VERSION ""

NS_ :

BS_:

BU_: ACC GW LAS BDC mADC FC APA HPP

BO_ 898 ACC_382: 64 ACC
 SG_ ACC_TarVehLngRange : 487|12@0+ (0.1,0) [0|300] "m"  ACC,LAS,GW
 SG_ ACC_Target5ZoneID : 449|5@0+ (1,0) [0|31] ""  ACC,LAS,GW,mADC
 SG_ ACC_Target5HeadingAngle : 443|10@0+ (0.01,-3.14) [-3.14|3.14] "rad"  ACC,LAS,GW,mADC
 SG_ ACC_Target5Direction : 446|3@0+ (1,0) [0|7] ""  ACC,LAS,GW,mADC
 SG_ ACC_Target5LatRange : 424|10@0+ (0.1,-50) [-50|50] "m"  ACC,LAS,GW,mADC
 SG_ ACC_Target5LngRange : 420|12@0+ (0.1,-100) [-100|300] "m"  ACC,LAS,GW,mADC
 SG_ ACC_Target5Type : 408|4@0+ (1,0) [0|15] ""  ACC,LAS,GW,mADC
 SG_ ACC_Target5ID : 414|6@0+ (1,0) [0|63] ""  ACC,LAS,GW,mADC
 SG_ ACC_Target5Detection : 401|3@0+ (1,0) [0|7] ""  ACC,LAS,GW,mADC
 SG_ ACC_Target4ZoneID : 406|5@0+ (1,0) [0|31] ""  ACC,LAS,FC,GW,mADC
 SG_ ACC_Target4HeadingAngle : 384|10@0+ (0.01,-3.14) [-3.14|3.14] "rad"  ACC,LAS,FC,GW,mADC
 SG_ ACC_Target4Direction : 387|3@0+ (1,0) [0|7] ""  ACC,LAS,FC,GW,mADC
 SG_ ACC_Target4LatRange : 381|10@0+ (0.1,-50) [-50|50] "m"  ACC,LAS,FC,GW,mADC
 SG_ ACC_Target4LngRange : 361|12@0+ (0.1,-100) [-100|300] "m"  ACC,LAS,FC,GW,mADC
 SG_ ACC_Target4Type : 365|4@0+ (1,0) [0|15] ""  ACC,LAS,FC,GW,mADC
 SG_ ACC_Target4ID : 355|6@0+ (1,0) [0|63] ""  ACC,LAS,FC,GW,mADC
 SG_ ACC_Target4Detection : 358|3@0+ (1,0) [0|7] ""  ACC,LAS,FC,GW,mADC
 SG_ ACC_Target3ZoneID : 347|5@0+ (1,0) [0|31] ""  ACC,LAS,FC,GW,mADC
 SG_ ACC_Target3HeadingAngle : 341|10@0+ (0.01,-3.14) [-3.14|3.14] "rad"  ACC,LAS,FC,GW,mADC
 SG_ ACC_Target3Direction : 328|3@0+ (1,0) [0|7] ""  ACC,LAS,FC,GW,mADC
 SG_ ACC_Target3LatRange : 322|10@0+ (0.1,-50) [-50|50] "m"  ACC,LAS,FC,GW,mADC
 SG_ ACC_Target3LngRange : 318|12@0+ (0.1,-100) [-100|300] "m"  ACC,LAS,FC,GW,mADC
 SG_ ACC_Target3Type : 306|4@0+ (1,0) [0|15] ""  ACC,LAS,FC,GW,mADC
 SG_ ACC_Target3ID : 296|6@0+ (1,0) [0|63] ""  ACC,LAS,FC,GW,mADC
 SG_ ACC_Target3Detection : 299|3@0+ (1,0) [0|7] ""  ACC,LAS,FC,GW,mADC
 SG_ ACC_Target2ZoneID : 288|5@0+ (1,0) [0|31] ""  ACC,LAS,FC,GW,mADC
 SG_ ACC_Target2HeadingAngle : 282|10@0+ (0.01,-3.14) [-3.14|3.14] "rad"  ACC,LAS,FC,GW,mADC
 SG_ ACC_Target2Direction : 285|3@0+ (1,0) [0|7] ""  ACC,LAS,FC,GW,mADC
 SG_ ACC_Target2LatRange : 279|10@0+ (0.1,-50) [-50|50] "m"  ACC,LAS,FC,GW,mADC
 SG_ ACC_Target2LngRange : 259|12@0+ (0.1,-100) [-100|300] "m"  ACC,LAS,FC,GW,mADC
 SG_ ACC_Target2Type : 263|4@0+ (1,0) [0|15] ""  ACC,LAS,FC,GW,mADC
 SG_ ACC_Target2ID : 253|6@0+ (1,0) [0|63] ""  ACC,LAS,FC,GW,mADC
 SG_ ACC_Target2Detection : 240|3@0+ (1,0) [0|7] ""  ACC,LAS,FC,GW,mADC
 SG_ ACC_Target1ZoneID : 247|5@0+ (1,0) [0|31] ""  ACC,LAS,FC,GW,mADC
 SG_ ACC_Target1HeadingAngle : 225|10@0+ (0.01,-3.14) [-3.14|3.14] "rad"  ACC,LAS,FC,GW,mADC
 SG_ ACC_Target1Direction : 202|3@0+ (1,0) [0|7] ""  ACC,LAS,FC,GW,mADC
 SG_ ACC_Target1LatRange : 219|10@0+ (0.1,-50) [-50|50] "m"  ACC,LAS,FC,GW,mADC
 SG_ ACC_Target1LngRange : 215|12@0+ (0.1,-100) [-100|300] "m"  ACC,LAS,FC,GW,mADC
 SG_ ACC_Target1Type : 206|4@0+ (1,0) [0|15] ""  ACC,LAS,FC,GW,mADC
 SG_ ACC_Target1ID : 196|6@0+ (1,0) [0|63] ""  ACC,LAS,FC,GW,mADC
 SG_ ACC_Target1Detection : 199|3@0+ (1,0) [0|7] ""  ACC,LAS,FC,GW,mADC
 SG_ ACC_RollingCounter_3E6 : 179|4@0+ (1,0) [0|15] ""  ACC,LAS,GW
 SG_ ACC_CRCCheck_3E6 : 191|8@0+ (1,0) [0|255] ""  ACC,LAS,GW
 SG_ ACC_CRCCheck_35C : 127|8@0+ (1,0) [0|255] ""  ACC,LAS,FC,GW
 SG_ ACC_RollingCounter_35C : 115|4@0+ (1,0) [0|15] ""  ACC,LAS,FC,GW
 SG_ ACC_CRCCheck_35D : 63|8@0+ (1,0) [0|255] ""  ACC,LAS,GW
 SG_ ACC_RollingCounter_35D : 51|4@0+ (1,0) [0|15] ""  ACC,LAS,GW
 SG_ ACC_LaneEquationStatus : 181|2@0+ (1,0) [0|3] ""  ACC,LAS,FC,GW,mADC
 SG_ ACC_LaneEquationC3 : 161|12@0+ (4.768E-007,-0.0009760857) [-0.0009760857|0.0009760857] ""  ACC,LAS,FC,GW,mADC
 SG_ ACC_LaneEquationC2 : 157|12@0+ (1.52588E-005,-0.0312347412) [-0.0312347412|0.0312347412] ""  ACC,LAS,FC,GW,mADC
 SG_ ACC_LaneEquationC1 : 137|12@0+ (0.0004882813,-1) [-1|0.9990234375] "rad"  ACC,LAS,FC,GW,mADC
 SG_ ACC_LaneQuality : 134|6@0+ (0.015625,0) [0|0.984375] ""  ACC,LAS,FC,GW

BO_ 676 GW_2A4: 64 GW
 SG_ LCDAR_Left_RCTAAlert : 1|2@0+ (1,0) [0|3] ""  APA,mADC
 SG_ LCDAR_RCTAAlert : 21|2@0+ (1,0) [0|3] ""  APA,mADC
 SG_ LCDAR_BSD_LCASoundWar : 3|1@0+ (1,0) [0|1] ""  mADC
 SG_ LCDAR_RCTBStatus : 17|2@0+ (1,0) [0|3] ""  ACC,LAS,mADC
 SG_ LCDAR_CRCCheck_2AF : 63|8@0+ (1,0) [0|255] ""  LAS,FC,ACC
 SG_ LCDAR_RollingCounter_2AF : 51|4@0+ (1,0) [0|15] ""  LAS,FC,ACC
 SG_ LCDAR_ELK_oAlert : 25|2@0+ (1,0) [0|3] ""  LAS
 SG_ LCDAR_ELK_oStatus : 27|2@0+ (1,0) [0|3] ""  LAS
 SG_ LCDAR_Left_ELK_oAlert : 29|2@0+ (1,0) [0|3] ""  LAS,FC
 SG_ LCDAR_RCTBActive : 19|1@0+ (1,0) [0|1] ""  ACC,LAS,mADC
 SG_ LCDAR_RCTBTargetDecel : 39|16@0+ (0.0005,-16) [-16|16] "m/s2"  ACC,LAS
 SG_ LCDAR_RCTBEnable : 18|1@0+ (1,0) [0|1] ""  mADC
 SG_ LCDAR_SystemStatus : 12|3@0+ (1,0) [0|7] ""  ACC,LAS,FC,mADC

BO_ 1893 GW_765: 64 GW
 SG_ Diagnose_message765 : 0|1@0+ (1,0) [1|1] ""  ACC,mADC

BO_ 1901 ACC_76D: 64 ACC
 SG_ Diagnose_message76D : 0|1@0+ (1,0) [1|1] ""  mADC,GW

BO_ 1937 GW_791: 8 GW
 SG_ Diagnose_message791 : 0|1@0+ (1,0) [1|1] ""  ACC,mADC

BO_ 1945 ACC_799: 8 ACC
 SG_ Diagnose_message799 : 0|1@0+ (1,0) [1|1] ""  mADC,GW

BO_ 1874 GW_752: 64 GW
 SG_ Diagnose_message752 : 0|1@0+ (1,0) [1|1] ""  FC,LAS

BO_ 1882 LAS_75A: 64 LAS
 SG_ Diagnose_message75A : 0|1@0+ (1,0) [1|1] ""  FC,GW

BO_ 1891 GW_763: 8 GW
 SG_ Diagnose_message763 : 0|1@0+ (1,0) [1|1] ""  FC,LAS

BO_ 1899 LAS_76B: 8 LAS
 SG_ Diagnose_message76B : 0|1@0+ (1,0) [1|1] ""  FC,GW

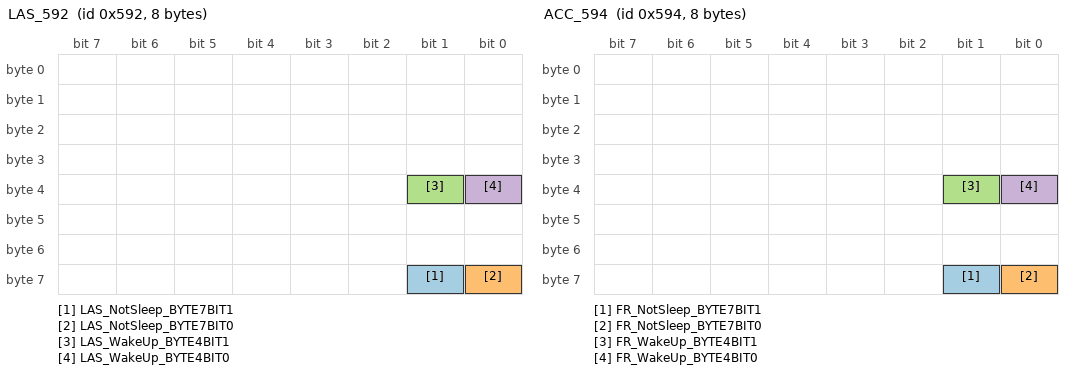
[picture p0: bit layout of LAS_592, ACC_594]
BO_ 1426 LAS_592: 8 LAS
 SG_ LAS_NotSleep_BYTE7BIT1 : 57|1@0+ (1,0) [0|1] ""  FC,GW
 SG_ LAS_NotSleep_BYTE7BIT0 : 56|1@0+ (1,0) [0|1] ""  FC,GW
 SG_ LAS_WakeUp_BYTE4BIT1 : 33|1@0+ (1,0) [0|1] ""  FC,GW
 SG_ LAS_WakeUp_BYTE4BIT0 : 32|1@0+ (1,0) [0|1] ""  FC,GW

BO_ 1428 ACC_594: 8 ACC
 SG_ FR_NotSleep_BYTE7BIT1 : 57|1@0+ (1,0) [0|1] ""  GW,mADC
 SG_ FR_NotSleep_BYTE7BIT0 : 56|1@0+ (1,0) [0|1] ""  GW,mADC
 SG_ FR_WakeUp_BYTE4BIT1 : 33|1@0+ (1,0) [0|1] ""  GW,mADC
 SG_ FR_WakeUp_BYTE4BIT0 : 32|1@0+ (1,0) [0|1] ""  GW,mADC

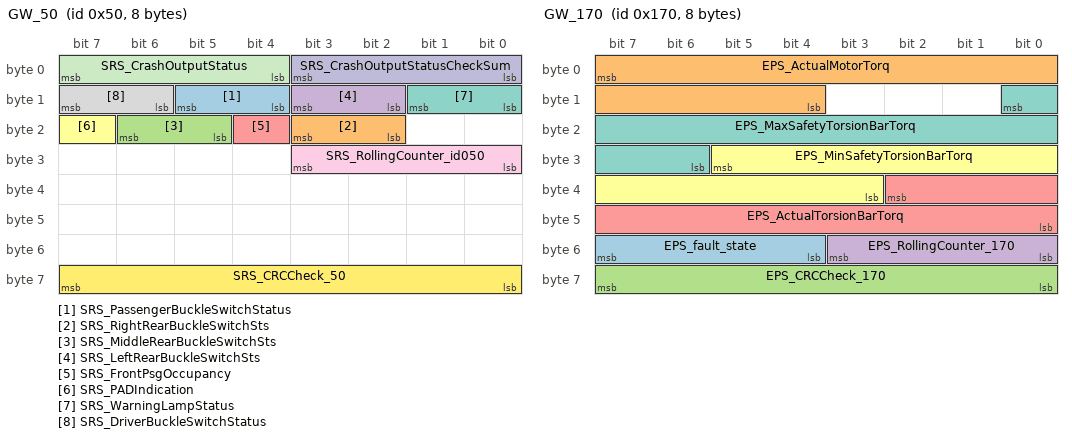
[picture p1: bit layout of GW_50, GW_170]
BO_ 80 GW_50: 8 GW
 SG_ SRS_PassengerBuckleSwitchStatus : 13|2@0+ (1,0) [0|3] ""  mADC
 SG_ SRS_RightRearBuckleSwitchSts : 19|2@0+ (1,0) [0|3] ""  mADC
 SG_ SRS_MiddleRearBuckleSwitchSts : 22|2@0+ (1,0) [0|3] ""  mADC
 SG_ SRS_LeftRearBuckleSwitchSts : 11|2@0+ (1,0) [0|3] ""  mADC
 SG_ SRS_FrontPsgOccupancy : 20|1@0+ (1,0) [0|1] ""  mADC
 SG_ SRS_PADIndication : 23|1@0+ (1,0) [0|1] ""  mADC
 SG_ SRS_WarningLampStatus : 9|2@0+ (1,0) [0|3] ""  ACC,LAS,FC,mADC
 SG_ SRS_DriverBuckleSwitchStatus : 15|2@0+ (1,0) [0|3] ""  ACC,LAS,FC,APA,mADC
 SG_ SRS_RollingCounter_id050 : 27|4@0+ (1,0) [0|15] ""  ACC,LAS,FC,mADC
 SG_ SRS_CrashOutputStatusCheckSum : 3|4@0+ (1,0) [0|15] ""  ACC,LAS,FC,mADC
 SG_ SRS_CrashOutputStatus : 7|4@0+ (1,0) [0|15] ""  ACC,LAS,FC,APA,mADC
 SG_ SRS_CRCCheck_50 : 63|8@0+ (1,0) [0|255] ""  ACC,LAS,FC,mADC

BO_ 368 GW_170: 8 GW
 SG_ EPS_fault_state : 55|4@0+ (1,0) [0|15] ""  LAS,ACC,FC,mADC
 SG_ EPS_ActualMotorTorq : 7|12@0+ (0.01,-20.48) [-20.48|20.46] "Nm"  LAS,FC,mADC
 SG_ EPS_CRCCheck_170 : 63|8@0+ (1,0) [0|255] ""  mADC,ACC,LAS
 SG_ EPS_RollingCounter_170 : 51|4@0+ (1,0) [0|15] ""  ACC,LAS,FC,mADC
 SG_ EPS_ActualTorsionBarTorq : 34|11@0+ (0.02,-20.48) [-20.48|20.44] "Nm"  LAS,FC,mADC
 SG_ EPS_MinSafetyTorsionBarTorq : 29|11@0+ (0.02,-20.48) [-20.48|20.44] "Nm"  LAS,FC,mADC
 SG_ EPS_MaxSafetyTorsionBarTorq : 8|11@0+ (0.02,-20.48) [-20.48|20.44] "Nm"  LAS,FC,mADC

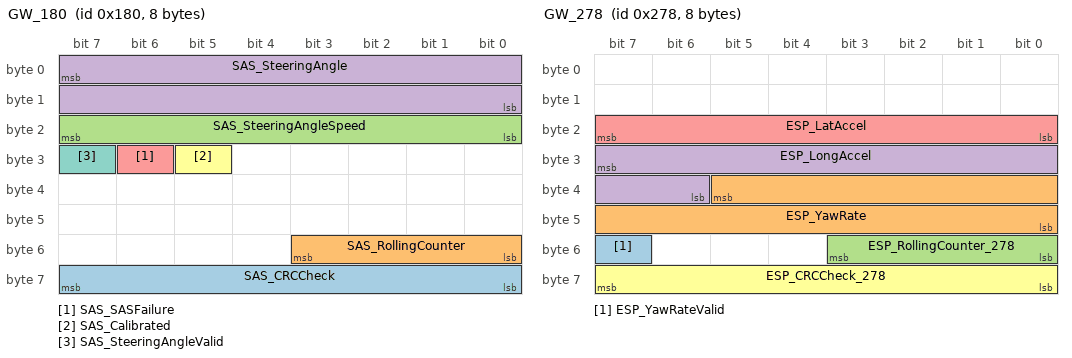
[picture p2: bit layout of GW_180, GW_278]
BO_ 384 GW_180: 8 GW
 SG_ SAS_CRCCheck : 63|8@0+ (1,0) [0|255] ""  APA,ACC,LAS,FC,HPP,mADC
 SG_ SAS_RollingCounter : 51|4@0+ (1,0) [0|15] ""  APA,ACC,LAS,FC,HPP,mADC
 SG_ SAS_SteeringAngleSpeed : 23|8@0+ (4,0) [0|1016] "deg/s"  APA,ACC,LAS,FC,HPP,mADC
 SG_ SAS_SteeringAngle : 7|16@0- (0.1,0) [-780|780] "degree"  APA,ACC,LAS,FC,HPP,mADC
 SG_ SAS_SASFailure : 30|1@0+ (1,0) [0|1] ""  APA,ACC,LAS,FC,mADC
 SG_ SAS_Calibrated : 29|1@0+ (1,0) [0|1] ""  APA,ACC,LAS,FC,mADC
 SG_ SAS_SteeringAngleValid : 31|1@0+ (1,0) [0|1] ""  APA,ACC,LAS,FC,mADC

BO_ 580 ACC_244: 64 ACC
 SG_ ADS_EOMTOReq : 155|2@0+ (1,0) [0|3] ""  ACC,LAS,GW
 SG_ ACC_HandsOnReq : 158|3@0+ (1,0) [0|7] ""  ACC,LAS,GW,APA,mADC
 SG_ ACC_LatTakeoverReq : 138|2@0+ (1,0) [0|3] ""  ACC,LAS,FC,GW,APA,mADC
 SG_ ACC_LngTakeOverReq : 140|2@0+ (1,0) [0|3] ""  ACC,LAS,FC,GW,APA,mADC
 SG_ ACC_LDWShakeLevStatus : 21|2@0+ (1,0) [0|3] ""  ACC,LAS,GW,mADC
 SG_ ACC_TextInfoForDriver : 30|6@0+ (1,0) [0|63] ""  ACC,LAS,GW,mADC
 SG_ ADS__RollingCounter_244 : 427|4@0+ (1,0) [0|15] ""  ACC,LAS,GW,mADC
 SG_ ADS_CRCCheck_244 : 439|16@0+ (1,0) [0|65535] ""  ACC,LAS,GW,mADC
 SG_ ACC_CRCCheck_25E : 127|8@0+ (1,0) [0|255] ""  ACC,LAS,GW,mADC
 SG_ ACC_RollingCounter_25E : 115|4@0+ (1,0) [0|15] ""  ACC,LAS,GW,mADC
 SG_ ACC_AEBCtrlType : 104|4@0+ (1,0) [0|15] ""  GW,ACC,LAS,APA,mADC
 SG_ ACC_AccTrqReq : 88|14@0+ (5,-5000) [-5000|5000] "NM"  ACC,LAS,GW,mADC
 SG_ ACC_AccTrqReqActive : 106|1@0+ (1,0) [0|1] ""  ACC,LAS,GW,mADC
 SG_ ACC_AEBVehilceHoldReq : 90|1@0+ (1,0) [0|1] ""  ACC,LAS,GW,mADC
 SG_ ACC_FCWPreWarning : 91|1@0+ (1,0) [0|1] ""  ACC,LAS,GW,APA,mADC
 SG_ ACC_FCWLatentWarning : 92|1@0+ (1,0) [0|1] ""  ACC,LAS,GW,mADC
 SG_ ACC_FCWActive : 93|1@0+ (1,0) [0|1] ""  ACC,LAS,GW,mADC
 SG_ ACC_PrefillActive : 94|1@0+ (1,0) [0|1] ""  ACC,LAS,GW,mADC
 SG_ ACC_AWBActive : 95|1@0+ (1,0) [0|1] ""  ACC,LAS,GW,APA,mADC
 SG_ ACC_AWBlevel : 83|4@0+ (1,0) [0|15] ""  ACC,LAS,GW,mADC
 SG_ ACC_ABAActive : 84|1@0+ (1,0) [0|1] ""  ACC,LAS,GW,mADC
 SG_ ACC_ABAlevel : 86|2@0+ (1,0) [0|3] ""  ACC,LAS,GW,mADC
 SG_ ACC_AEBActive : 87|1@0+ (1,0) [0|1] ""  ACC,GW,APA,LAS,mADC
 SG_ ACC_AEBTargetDeceleration : 71|16@0+ (0.0005,-16) [-16|16] "m/s2"  ACC,LAS,GW,mADC
 SG_ ACC_EmergencyDataRrdReq : 23|2@0+ (1,0) [0|3] ""  ACC,LAS,APA,GW,mADC
 SG_ ACC_CRCCheck_24E : 63|8@0+ (1,0) [0|255] ""  ACC,LAS,GW,mADC
 SG_ ACC_RollingCounter_24E : 51|4@0+ (1,0) [0|15] ""  ACC,LAS,GW,mADC
 SG_ ACC_Driveoff_Request : 55|1@0+ (1,0) [0|1] ""  ACC,LAS,GW,mADC
 SG_ ACC_ACCMode : 54|3@0+ (1,0) [0|7] ""  ACC,LAS,GW,APA,mADC
 SG_ ACC_CDDActive : 44|1@0+ (1,0) [0|1] ""  ACC,LAS,GW,mADC
 SG_ ACC_DecToStop : 31|1@0+ (1,0) [0|1] ""  ACC,LAS,GW,mADC
 SG_ ACC_LKAStatus : 13|2@0+ (1,0) [0|3] ""  ACC,LAS,GW,mADC
 SG_ ACC_LDWVibrationWarningReq : 11|2@0+ (1,0) [0|3] ""  ACC,LAS,GW,mADC
 SG_ ACC_LDWStatus : 9|2@0+ (1,0) [0|3] ""  ACC,LAS,GW,mADC
 SG_ ACC_ACCTargetAcceleration : 7|8@0+ (0.05,-5) [-5|7.75] "m/s2"  ACC,LAS,GW,mADC

BO_ 632 GW_278: 8 GW
 SG_ ESP_YawRateValid : 55|1@0+ (1,0) [0|1] ""  ACC,LAS,FC,APA,HPP
 SG_ ESP_YawRate : 37|14@0+ (0.01,-81.91) [-81.91|81.91] "degree/s"  ACC,LAS,FC,APA,HPP
 SG_ ESP_RollingCounter_278 : 51|4@0+ (1,0) [0|15] ""  ACC,LAS,FC,APA,HPP
 SG_ ESP_LongAccel : 31|10@0+ (0.03125,-16) [-16|15.90625] "m/s2"  ACC,LAS,FC,APA,HPP
 SG_ ESP_LatAccel : 23|8@0+ (0.1,-12.7) [-12.7|12.7] "m/s2"  ACC,LAS,FC,APA,HPP
 SG_ ESP_CRCCheck_278 : 63|8@0+ (1,0) [0|255] ""  ACC,LAS,FC,APA,HPP

BO_ 664 GW_298: 8 GW
 SG_ BCM_TrunkUnlockReq : 29|1@0+ (1,0) [0|1] "" Vector__XXX
 SG_ BCM_DriverDoorLockStatus : 44|2@0+ (1,0) [0|3] ""  ACC,LAS,APA,mADC
 SG_ BCM_CRCCheck_298 : 63|8@0+ (1,0) [0|255] ""  mADC
 SG_ BCM_RollingCounter_298 : 51|4@0+ (1,0) [0|15] ""  mADC
 SG_ BCM_PassengerDoorLockStatus : 42|2@0+ (1,0) [0|3] ""  mADC
 SG_ BCM_LeftRearDoorStatus : 40|1@0+ (1,0) [0|1] ""  ACC,FC,LAS,APA,mADC
 SG_ PEPS_SmartWelcomeLightStaus : 37|2@0+ (1,0) [0|3] "" Vector__XXX
 SG_ PEPS_TrunkKeyStatus : 35|2@0+ (1,0) [0|3] ""  APA,mADC
 SG_ PEPS_UnLockKeyStatus : 33|2@0+ (1,0) [0|3] ""  APA,mADC
 SG_ PEPS_LockKeyStatus : 31|2@0+ (1,0) [0|3] ""  APA,mADC
 SG_ PEPS_SmartTrunkUlockRemind : 23|2@0+ (1,0) [0|3] "" Vector__XXX
 SG_ PEPS_UnlockSignal : 21|2@0+ (1,0) [0|3] ""  mADC
 SG_ PEPS_LockSignal : 17|2@0+ (1,0) [0|3] ""  mADC
 SG_ PEPS_KeyNumber : 15|3@0+ (1,0) [0|7] "" Vector__XXX
 SG_ PEPS_KeyAuthenticationStatus : 12|2@0+ (1,0) [0|3] "" Vector__XXX
 SG_ PEPS_Easy_open : 10|1@0+ (1,0) [0|1] "" Vector__XXX
 SG_ PEPS_Welcomelamp : 9|2@0+ (1,0) [0|3] "" Vector__XXX
 SG_ PEPS_TrunkRequestSignal : 7|1@0+ (1,0) [0|1] "" Vector__XXX
 SG_ PEPS_KeyLearningSignal : 6|2@0+ (1,0) [0|3] "" Vector__XXX
 SG_ PEPS_EasyOpenOrginalSignal : 4|1@0+ (1,0) [0|1] "" Vector__XXX
 SG_ PEPS_RemoteFailedAlarmSignal : 3|1@0+ (1,0) [0|1] "" Vector__XXX
 SG_ PEPS_SearchCarSignal : 2|1@0+ (1,0) [0|1] "" Vector__XXX
 SG_ PEPS_LuggageUnlockSignal : 1|2@0+ (1,0) [0|3] "" Vector__XXX

BO_ 775 ACC_307: 64 ACC
 SG_ ACC_AEBTargetSelected : 235|3@0+ (1,0) [0|7] ""  ACC,LAS,GW
 SG_ ACC_AEBFeatureConfig : 84|4@0+ (1,0) [0|15] ""  ACC,LAS,GW
 SG_ ACC_ACCTargetLngRange : 71|9@0+ (0.5,-70) [-70|180] "m"  ACC,GW
 SG_ ACC_IACCSuspendReason : 39|3@0+ (1,0) [0|7] ""  ACC,LAS,FC,GW,mADC
 SG_ ACC_RLaneDistanceFus : 415|7@0+ (0.05,-5) [-5|1] "m"  ACC,LAS,GW,mADC
 SG_ ACC_LLaneDistanceFus : 407|7@0+ (0.05,-1) [-1|5] "m"  ACC,LAS,GW,mADC
 SG_ ACC_RRLaneDis : 399|8@0+ (0.05,-12) [-12|0] "m"  ACC,LAS,GW,mADC
 SG_ ACC_LLLaneDis : 391|8@0+ (0.05,0) [0|12] "m"  ACC,LAS,GW,mADC
 SG_ ACC_Target7ZoneID : 375|5@0+ (1,0) [0|31] ""  ACC,LAS,GW,mADC
 SG_ ACC_Target7HeadingAngle : 353|10@0+ (0.01,-3.14) [-3.14|3.14] "rad"  ACC,LAS,GW,mADC
 SG_ ACC_Target7Direction : 330|3@0+ (1,0) [0|7] ""  ACC,LAS,GW,mADC
 SG_ ACC_Target7LatRange : 347|10@0+ (0.1,-50) [-50|50] "m"  ACC,LAS,GW,mADC
 SG_ ACC_Target7LngRange : 343|12@0+ (0.1,-100) [-100|300] "m"  ACC,LAS,GW,mADC
 SG_ ACC_Target7Type : 334|4@0+ (1,0) [0|15] ""  ACC,LAS,GW,mADC
 SG_ ACC_Target7ID : 324|6@0+ (1,0) [0|63] ""  ACC,LAS,GW,mADC
 SG_ ACC_Target7Detection : 327|3@0+ (1,0) [0|7] ""  ACC,LAS,GW,mADC
 SG_ ACC_Target6ZoneID : 311|5@0+ (1,0) [0|31] ""  ACC,LAS,GW,mADC
 SG_ ACC_Target6HeadingAngle : 289|10@0+ (0.01,-3.14) [-3.14|3.14] "rad"  ACC,LAS,GW,mADC
 SG_ ACC_Target6Direction : 266|3@0+ (1,0) [0|7] ""  ACC,LAS,GW,mADC
 SG_ ACC_Target6LatRange : 283|10@0+ (0.1,-50) [-50|50] "m"  ACC,LAS,GW,mADC
 SG_ ACC_Target6LngRange : 279|12@0+ (0.1,-100) [-100|300] "m"  ACC,LAS,GW,mADC
 SG_ ACC_Target6Type : 270|4@0+ (1,0) [0|15] ""  ACC,LAS,GW,mADC
 SG_ ACC_Target6ID : 260|6@0+ (1,0) [0|63] ""  ACC,LAS,GW,mADC
 SG_ ACC_Target6Detection : 263|3@0+ (1,0) [0|7] ""  ACC,LAS,GW,mADC
 SG_ ACC_AEBEnable : 26|1@0+ (1,0) [0|1] ""  ACC,LAS,GW,mADC
 SG_ ACC_VehicleStartRemindSts : 425|3@0+ (1,0) [0|7] ""  ACC,LAS,GW,mADC
 SG_ ACC_CRCCheck_35F : 255|8@0+ (1,0) [0|255] ""  ACC,LAS,FC,GW,mADC
 SG_ ACC_RollingCounter_35F : 243|4@0+ (1,0) [0|15] ""  ACC,LAS,FC,GW,mADC
 SG_ ACC_CSLAEnableStatus : 245|2@0+ (1,0) [0|3] ""  ACC,LAS,GW
 SG_ ACC_CSLSetReq : 227|1@0+ (1,0) [0|1] ""  ACC,LAS,GW,mADC
 SG_ ACC_CRCCheck_344 : 191|8@0+ (1,0) [0|255] ""  ACC,LAS,FC,GW,mADC
 SG_ ACC_RollingCounter_344 : 179|4@0+ (1,0) [0|15] ""  ACC,LAS,FC,GW,mADC
 SG_ ACC_CRCCheck_322 : 127|8@0+ (1,0) [0|255] ""  ACC,LAS,FC,GW,mADC
 SG_ ACC_RollingCounter_322 : 115|4@0+ (1,0) [0|15] ""  ACC,LAS,FC,GW,mADC
 SG_ ACC_ACCTargetRelSpd : 92|9@0+ (1,-250) [-250|250] "km/h"  ACC,LAS,GW
 SG_ ACC_FRadarCalibrationStatus : 94|2@0+ (1,0) [0|3] ""  ACC,LAS,GW,mADC
 SG_ ACC_CRCCheck_35E : 63|8@0+ (1,0) [0|255] ""  ACC,LAS,FC,GW,mADC
 SG_ ACC_RollingCounter_35E : 51|4@0+ (1,0) [0|15] ""  ACC,LAS,FC,GW,mADC
 SG_ ACC_FCWSettingStatus : 30|3@0+ (1,0) [0|7] ""  ACC,LAS,GW,mADC
 SG_ ACC_ACCEPBrequest : 23|1@0+ (1,0) [0|1] ""  ACC,LAS,FC,GW,mADC
 SG_ ACC_ObjValid : 13|1@0+ (1,0) [0|1] ""  ACC,LAS,FC,GW
 SG_ ACC_TimeGapSet : 18|3@0+ (1,0) [0|7] ""  ACC,LAS,FC,GW,mADC
 SG_ ACC_DistanceLevel : 22|3@0+ (1,0) [0|7] ""  ACC,LAS,FC,GW,mADC
 SG_ ACC_SetSpeed : 6|8@0+ (1,0) [0|254] "Km/h"  ACC,LAS,FC,GW,mADC

BO_ 786 ACC_312: 64 ACC
 SG_ ACC_AEBTargetFourWheelProb : 276|7@0+ (1,0) [0|100] "%"  ACC,LAS,GW
 SG_ ACC_AEBTargetProb : 38|7@0+ (1,0) [0|100] "%"  ACC,LAS,GW,mADC
 SG_ ACC_AEBTargetAx : 263|9@0+ (0.1,-16) [-16|16] "m/s2"  ACC,LAS,mADC,GW
 SG_ ACC_Selflearning_status : 13|2@0+ (1,0) [0|3] ""  FC,ACC,LAS,GW,mADC
 SG_ ACC_Selflearning_angle : 238|11@0+ (0.01,-10.25) [-10.25|10.22] "degree"  ACC,LAS,FC,GW,mADC
 SG_ ADS_NDAAudioWarEnableStatus : 107|1@0+ (1,0) [0|1] ""  ACC,LAS,GW,mADC
 SG_ ADS_ADSVoiceRequest : 102|9@0+ (1,0) [0|511] ""  ACC,LAS,GW
 SG_ ADS_EOMWarnning : 71|3@0+ (1,0) [0|7] ""  ACC,LAS,GW,APA
 SG_ ADS_CRCCheck_3D7 : 255|8@0+ (1,0) [0|255] ""  ACC,LAS,GW
 SG_ ADS_RollingCounter_3D7 : 243|4@0+ (1,0) [0|15] ""  ACC,LAS,GW
 SG_ ACC_DriverWindowControl : 198|7@0+ (1,0) [0|100] "%"  ACC,LAS,GW,mADC
 SG_ ACC_AEBTargetDirection : 47|3@0+ (1,0) [0|7] ""  ACC,LAS,GW,mADC
 SG_ ACC_AEBTargetDetection : 44|1@0+ (1,0) [0|1] ""  ACC,LAS,GW,mADC
 SG_ ACC_AEBTargetType : 43|4@0+ (1,0) [0|15] ""  ACC,LAS,GW,mADC
 SG_ ACC_CRCCheck_3E4 : 63|8@0+ (1,0) [0|255] ""  FC,ACC,LAS,GW,mADC
 SG_ ACC_RollingCounter_3E4 : 51|4@0+ (1,0) [0|15] ""  FC,ACC,LAS,GW,mADC

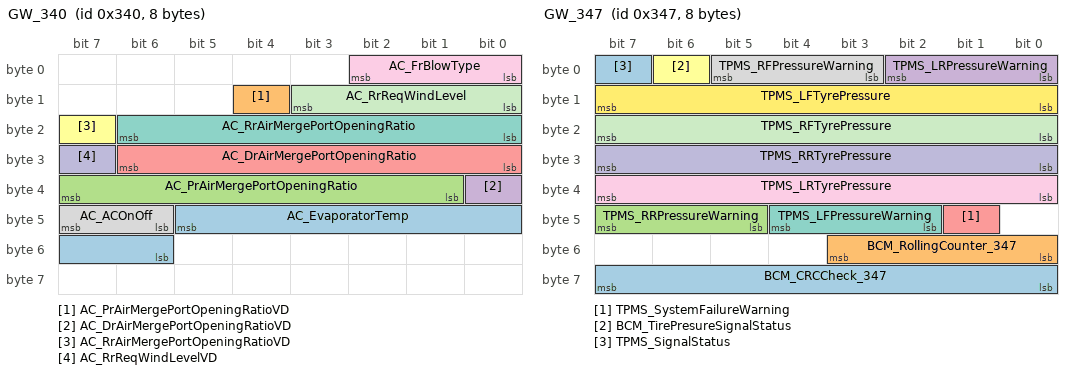
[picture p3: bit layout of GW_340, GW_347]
BO_ 832 GW_340: 8 GW
 SG_ AC_EvaporatorTemp : 45|8@0+ (0.5,-40) [-40|87.5] "degreeC" Vector__XXX
 SG_ AC_PrAirMergePortOpeningRatioVD : 12|1@0+ (1,0) [0|1] "" Vector__XXX
 SG_ AC_PrAirMergePortOpeningRatio : 39|7@0+ (1,0) [0|127] "" Vector__XXX
 SG_ AC_DrAirMergePortOpeningRatioVD : 32|1@0+ (1,0) [0|1] "" Vector__XXX
 SG_ AC_DrAirMergePortOpeningRatio : 30|7@0+ (1,0) [0|127] "" Vector__XXX
 SG_ AC_RrAirMergePortOpeningRatioVD : 23|1@0+ (1,0) [0|1] "" Vector__XXX
 SG_ AC_RrAirMergePortOpeningRatio : 22|7@0+ (1,0) [0|127] "" Vector__XXX
 SG_ AC_ACOnOff : 47|2@0+ (1,0) [0|3] "" Vector__XXX
 SG_ AC_FrBlowType : 2|3@0+ (1,0) [0|7] ""  ACC,LAS,FC
 SG_ AC_RrReqWindLevelVD : 31|1@0+ (1,0) [0|1] "" Vector__XXX
 SG_ AC_RrReqWindLevel : 11|4@0+ (1,0) [0|15] "档" Vector__XXX

BO_ 839 GW_347: 8 GW
 SG_ BCM_CRCCheck_347 : 63|8@0+ (1,0) [0|255] ""  mADC
 SG_ BCM_RollingCounter_347 : 51|4@0+ (1,0) [0|15] ""  mADC
 SG_ TPMS_RRPressureWarning : 47|3@0+ (1,0) [0|7] ""  ACC,LAS,mADC
 SG_ TPMS_LRPressureWarning : 2|3@0+ (1,0) [0|7] ""  ACC,LAS,mADC
 SG_ TPMS_SystemFailureWarning : 41|1@0+ (1,0) [0|1] ""  mADC
 SG_ BCM_TirePresureSignalStatus : 6|1@0+ (1,0) [0|1] "" Vector__XXX
 SG_ TPMS_LFPressureWarning : 44|3@0+ (1,0) [0|7] ""  ACC,LAS,mADC
 SG_ TPMS_RFPressureWarning : 5|3@0+ (1,0) [0|7] ""  ACC,LAS,mADC
 SG_ TPMS_LRTyrePressure : 39|8@0+ (1.373,0) [0|350.115] "KPa"  ACC,LAS
 SG_ TPMS_RRTyrePressure : 31|8@0+ (1.373,0) [0|350.115] "KPa"  ACC,LAS
 SG_ TPMS_RFTyrePressure : 23|8@0+ (1.373,0) [0|350.115] "KPa"  ACC,LAS
 SG_ TPMS_LFTyrePressure : 15|8@0+ (1.373,0) [0|350.115] "KPa"  ACC,LAS
 SG_ TPMS_SignalStatus : 7|1@0+ (1,0) [0|1] ""  mADC

BO_ 869 GW_365: 32 GW
 SG_ DMS_Zlocation_eye : 175|11@0+ (2,-2046) [-2046|2048] "mm"  mADC
 SG_ DMS_Ylocation_eye : 154|11@0+ (2,-2046) [-2046|2048] "mm"  mADC
 SG_ DMS_Xlocation_eye : 149|11@0+ (2,-2046) [-2046|2048] "mm"  mADC
 SG_ IMS_JawOffsetValue : 91|4@0+ (1,0) [0|15] "cm"  ACC,LAS,mADC
 SG_ IMS_BrowOffsetValue : 95|4@0+ (1,0) [0|15] "cm"  ACC,LAS,mADC
 SG_ IMS_PhoneCallSts : 24|1@0+ (1,0) [0|1] ""  mADC
 SG_ IMS_DriverEyesFovArea : 47|4@0+ (1,0) [0|15] ""  mADC
 SG_ IMS_DriverEyeClosestatus : 27|3@0+ (1,0) [0|7] ""  ACC,LAS,mADC
 SG_ IMS_DriverEyeConfidence : 43|8@0+ (1,0) [0|255] "%"  mADC
 SG_ IMS_DriverEyeDetect : 29|2@0+ (1,0) [0|3] ""  mADC
 SG_ IMS_RollingCounter_3A7 : 179|4@0+ (1,0) [0|15] ""  ACC,LAS
 SG_ IMS_CRCCheck_3A7 : 191|8@0+ (1,0) [0|255] ""  ACC,LAS
 SG_ IMS_DistractionWarning : 151|2@0+ (1,0) [0|3] "" Vector__XXX
 SG_ IMS_DistractionSetFb : 137|2@0+ (1,0) [0|3] "" Vector__XXX
 SG_ IMS_DrowsinessSetFb : 139|2@0+ (1,0) [0|3] "" Vector__XXX
 SG_ IMS_DrowsinessSensFb : 141|2@0+ (1,0) [0|3] "" Vector__XXX
 SG_ IMS_DrowsinessWarning : 128|3@0+ (1,0) [0|7] "" Vector__XXX
 SG_ IMS_IDUpdateRemind : 131|3@0+ (1,0) [0|7] "" Vector__XXX
 SG_ IMS_DriverID : 135|4@0+ (1,0) [0|15] "" Vector__XXX
 SG_ IMS_RollingCounter_360 : 115|4@0+ (1,0) [0|15] ""  ACC,LAS
 SG_ IMS_CRCCheck_360 : 127|8@0+ (1,0) [0|255] ""  ACC,LAS
 SG_ IMS_HeadDetectSts_Yaw : 87|8@0+ (1,-75) [-75|75] "度"  ACC,LAS,mADC
 SG_ IMS_HeadDetectSts_Roll : 79|8@0+ (1,-45) [-45|45] "度"  ACC,LAS,mADC
 SG_ IMS_HeadDetectSts_Pitch : 71|8@0+ (1,-25) [-25|45] "度"  ACC,LAS,mADC
 SG_ IMS_RollingCounter_356 : 51|4@0+ (1,0) [0|15] ""  ACC,LAS
 SG_ IMS_CRCCheck_356 : 63|8@0+ (1,0) [0|255] ""  ACC,LAS
 SG_ IMS_IMSStatus : 0|3@0+ (1,0) [0|7] ""  ACC,LAS,mADC
 SG_ IMS_EyeGazeStatus : 21|8@0+ (1,-75) [-75|75] "度"  ACC,LAS,mADC
 SG_ IMS_EyeDetectSatus : 13|8@0+ (1,0) [0|100] "%"  ACC,LAS,mADC
 SG_ IMS_DrowsinessStatus : 3|3@0+ (1,0) [0|7] ""  ACC,LAS,mADC
 SG_ IMS_DriverHeadDetect : 5|2@0+ (1,0) [0|3] ""  ACC,LAS,mADC
 SG_ IMS_DistractionStatus : 7|2@0+ (1,0) [0|3] ""  ACC,LAS,mADC

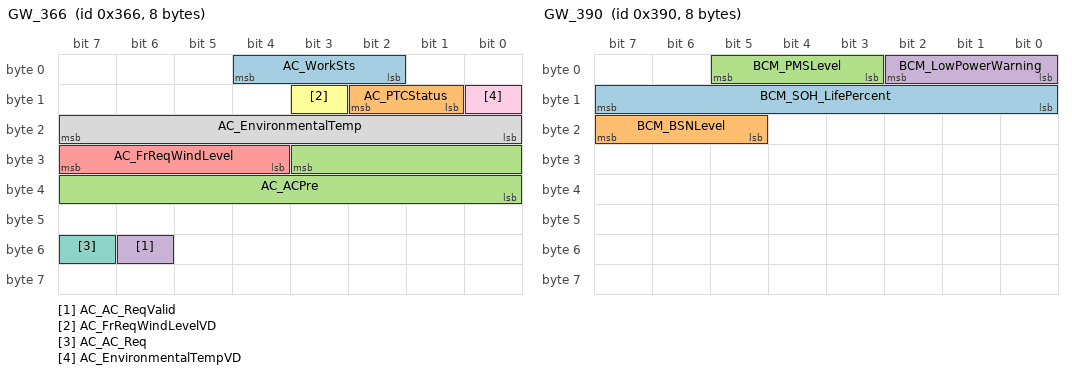
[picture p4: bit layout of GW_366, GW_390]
BO_ 870 GW_366: 8 GW
 SG_ AC_WorkSts : 4|3@0+ (1,0) [0|7] "" Vector__XXX
 SG_ AC_PTCStatus : 10|2@0+ (1,0) [0|3] "" Vector__XXX
 SG_ AC_ACPre : 27|12@0+ (0.01,0) [0|40.95] "Mpa" Vector__XXX
 SG_ AC_AC_ReqValid : 54|1@0+ (1,0) [0|1] "" Vector__XXX
 SG_ AC_FrReqWindLevel : 31|4@0+ (1,0) [0|15] "" Vector__XXX
 SG_ AC_FrReqWindLevelVD : 11|1@0+ (1,0) [0|1] "" Vector__XXX
 SG_ AC_AC_Req : 55|1@0+ (1,0) [0|1] "" Vector__XXX
 SG_ AC_EnvironmentalTemp : 23|8@0+ (0.5,-40) [-40|87] "degreeC"  ACC,LAS,mADC
 SG_ AC_EnvironmentalTempVD : 8|1@0+ (1,0) [0|1] ""  ACC,LAS,mADC

BO_ 903 GW_387: 8 GW
 SG_ BCM_WelcomeLightModeFB : 10|3@0+ (1,0) [0|7] "" Vector__XXX
 SG_ BCM_CRCCheck_387 : 63|8@0+ (1,0) [0|255] ""  ACC,LAS,mADC
 SG_ BCM_RollingCounter_387 : 51|4@0+ (1,0) [0|15] ""  ACC,LAS,mADC
 SG_ BCM_RainfallLevel : 19|4@0+ (1,0) [0|15] ""  ACC,LAS,APA,mADC
 SG_ BCM_BLEKeyIndicator : 1|2@0+ (1,0) [0|3] ""  mADC
 SG_ BCM_SaveEnergySetStatus : 53|2@0+ (1,0) [0|3] "" Vector__XXX
 SG_ BCM_RearWiperStatus : 54|1@0+ (1,0) [0|1] ""  mADC
 SG_ BCM_FrontWashStatus : 27|2@0+ (1,0) [0|3] "" Vector__XXX
 SG_ BCM_FrontWiperStatus : 25|2@0+ (1,0) [0|3] ""  APA,ACC,LAS,mADC
 SG_ BCM_SystemFailureFlag : 55|1@0+ (1,0) [0|1] ""  APA,mADC
 SG_ BCM_BuzzerWarningMode : 47|5@0+ (1,0) [0|31] "" Vector__XXX
 SG_ BCM_LightSensor : 42|1@0+ (1,0) [0|1] ""  mADC
 SG_ BCM_RLS_Light_switch_reason : 39|8@0+ (1,0) [0|255] ""  ACC,APA,LAS,FC,mADC
 SG_ BCM_Statusrainsensor : 41|1@0+ (1,0) [0|1] ""  mADC
 SG_ BCM_Statuslowbeam : 40|1@0+ (1,0) [0|1] ""  mADC
 SG_ BCM_DrivingModeMemoryStatus : 15|2@0+ (1,0) [0|3] "" Vector__XXX
 SG_ BCM_DriveModeSet : 13|3@0+ (1,0) [0|7] "" Vector__XXX
 SG_ BCM_ThemeChangeSet : 29|2@0+ (1,0) [0|3] "" Vector__XXX
 SG_ BCM_EPSTorqueModeFeedback : 31|2@0+ (1,0) [0|3] "" Vector__XXX
 SG_ BCM_DriveModeFeedback : 7|2@0+ (1,0) [0|3] "" Vector__XXX
 SG_ BCM_DriveModeStatus : 5|4@0+ (1,0) [0|15] ""  mADC

BO_ 912 GW_390: 8 GW
 SG_ BCM_SOH_LifePercent : 15|8@0+ (1,0) [0|255] "%"  ACC,LAS
 SG_ BCM_BSNLevel : 23|3@0+ (1,0) [0|7] "" Vector__XXX
 SG_ BCM_PMSLevel : 5|3@0+ (1,0) [0|7] ""  ACC,LAS,mADC
 SG_ BCM_LowPowerWarning : 2|3@0+ (1,0) [0|7] "" Vector__XXX

BO_ 918 GW_396: 8 GW
 SG_ BCM_Sunroof_APActive : 50|1@0+ (1,0) [0|1] "" Vector__XXX
 SG_ BCM_Sunroof_Intialized : 63|1@0+ (1,0) [0|1] "" Vector__XXX
 SG_ BCM_AerationHintReq : 52|2@0+ (1,0) [0|3] "" Vector__XXX
 SG_ PEPS_RemoteWindowUpSignal : 49|1@0+ (1,0) [0|1] "" Vector__XXX
 SG_ BCM_RemoteWindowUpSetStaus : 45|2@0+ (1,0) [0|3] "" Vector__XXX
 SG_ BCM_RemoteWindowDownSetStaus : 43|2@0+ (1,0) [0|3] "" Vector__XXX
 SG_ PEPS_RemoteWindowDownSignal : 48|1@0+ (1,0) [0|1] "" Vector__XXX
 SG_ BCM_RemoteWindowControl : 39|3@0+ (1,0) [0|7] "" Vector__XXX
 SG_ BCM_AutoCloseWindow : 41|2@0+ (1,0) [0|3] "" Vector__XXX
 SG_ BCM_WinOpenWarn : 36|1@0+ (1,0) [0|1] "" Vector__XXX
 SG_ BCM_WinDownCfgSts : 35|2@0+ (1,0) [0|3] "" Vector__XXX
 SG_ BCM_WinUpCfgSts : 33|2@0+ (1,0) [0|3] "" Vector__XXX
 SG_ BCM_LockAutoClsWinSetStatus : 30|2@0+ (1,0) [0|3] "" Vector__XXX
 SG_ BCM_SunroofMotor : 28|2@0+ (1,0) [0|3] "" Vector__XXX
 SG_ BCM_SunroofRainSetStatus : 23|2@0+ (1,0) [0|3] "" Vector__XXX
 SG_ BCM_Sunshade_Movement : 21|3@0+ (1,0) [0|7] "%" Vector__XXX
 SG_ BCM_Sunshade_POS_VIT_FL : 15|7@0+ (1,0) [0|127] "%" Vector__XXX
 SG_ BCM_Sunroof_POS_Direction : 8|1@0+ (1,0) [0|1] "" Vector__XXX
 SG_ BCM_Sunroof_Movement : 18|3@0+ (1,0) [0|7] "%" Vector__XXX
 SG_ BCM_Sunroof_POS_VIT : 7|7@0+ (1,0) [0|127] "" Vector__XXX
 SG_ BCM_SunroofStatus : 0|1@0+ (1,0) [0|1] ""  ACC,LAS,APA,mADC

BO_ 1287 GW_507: 64 GW
 SG_ HU_NDANavEnable : 183|2@0+ (1,0) [0|3] "" Vector__XXX
 SG_ HU_NDAEnable : 167|2@0+ (1,0) [0|3] "" Vector__XXX
 SG_ HU_Tutorialmodel : 158|2@0+ (1,0) [0|3] ""  APA
 SG_ HU_APAActive3 : 154|1@0+ (1,0) [0|1] ""  APA
 SG_ HU_LaneChangeStyle : 233|3@0+ (1,0) [0|7] ""  mADC
 SG_ HU_DoorOpenWarningSelect : 173|2@0+ (1,0) [0|3] ""  APA
 SG_ HU_FullSpeedPanoramicSelect : 175|2@0+ (1,0) [0|3] ""  APA
 SG_ HU_ParkVoiceIntSetStatus : 130|2@0+ (1,0) [0|3] ""  APA
 SG_ HU_TJPEnable : 49|2@0+ (1,0) [0|3] "" Vector__XXX
 SG_ HU_FCTAEnable : 2|2@0+ (1,0) [0|3] "" Vector__XXX
 SG_ HU_FCTBEnable : 43|2@0+ (1,0) [0|3] "" Vector__XXX
 SG_ HU_RCTBEnable : 19|2@0+ (1,0) [0|3] ""  mADC
 SG_ HU_SlotVoiceSelect : 63|4@0+ (1,0) [0|15] ""  APA
 SG_ HU_ParkingModeSelect : 7|2@0+ (1,0) [0|3] ""  APA
 SG_ HU_TopLookDownSwitch : 65|2@0+ (1,0) [0|3] ""  APA
 SG_ HU_TransparentCarSwitch : 121|2@0+ (1,0) [0|3] ""  APA
 SG_ HU_DVREmergencyRecord : 115|2@0+ (1,0) [0|3] ""  APA,mADC
 SG_ HU_MODEnable : 117|2@0+ (1,0) [0|3] ""  APA
 SG_ HU_AVMCalibrationSwitch : 119|2@0+ (1,0) [0|3] ""  APA
 SG_ HU_DVRDistortCorrectSwitch : 99|2@0+ (1,0) [0|3] ""  APA
 SG_ HU_DVRTapeSet : 81|2@0+ (1,0) [0|3] ""  APA
 SG_ HU_ResolutionSet : 101|2@0+ (1,0) [0|3] ""  APA
 SG_ HU_DVREnableSet : 83|2@0+ (1,0) [0|3] ""  APA
 SG_ HU_DVRReplaySpeed : 85|2@0+ (1,0) [0|3] ""  APA
 SG_ HU_DVRReplayMode : 103|2@0+ (1,0) [0|3] ""  APA
 SG_ HU_ShootControl : 123|2@0+ (1,0) [0|3] ""  APA
 SG_ HU_RecordingcycleSetting : 69|2@0+ (1,0) [0|3] ""  APA
 SG_ HU_LanguageSet : 95|4@0+ (1,0) [0|15] ""  APA
 SG_ HU_DVRVedioSeek : 79|3@0+ (1,0) [0|7] ""  APA
 SG_ HU_DVRFormatReq : 67|2@0+ (1,0) [0|3] ""  APA
 SG_ HU_DVRReplayCommand : 71|2@0+ (1,0) [0|3] ""  APA
 SG_ HU_DVRVideoPlayUserTime : 96|9@0+ (1,0) [0|511] "second"  APA
 SG_ HU_TurnLightAVMSwitch : 91|2@0+ (1,0) [0|3] ""  APA
 SG_ HU_RadarAVMSwitch : 89|2@0+ (1,0) [0|3] ""  APA
 SG_ HU_VC_CruiseSetSpeed : 151|8@0+ (1,0) [0|255] ""  ACC,LAS,FC,mADC
 SG_ HU_VC_CruiseSetDistance : 142|3@0+ (1,0) [0|7] ""  ACC,LAS,FC,mADC
 SG_ HU_VC_CruiseControl : 138|3@0+ (1,0) [0|7] ""  ACC,LAS,FC,mADC
 SG_ HU_BSDLCASetting : 162|3@0+ (1,0) [0|7] ""  mADC
 SG_ HU_FCWSetting : 165|3@0+ (1,0) [0|7] ""  LAS,FC,ACC,mADC
 SG_ HU_FrontRadarActive : 156|2@0+ (1,0) [0|3] ""  APA,mADC
 SG_ HU_APAActive2 : 153|2@0+ (1,0) [0|3] ""  APA
 SG_ HU_ACCObjEnable : 128|2@0+ (1,0) [0|3] "" Vector__XXX
 SG_ HU_CruiseControlSet : 135|3@0+ (1,0) [0|7] "" Vector__XXX
 SG_ HU_AutoBrakeEnable : 132|2@0+ (1,0) [0|3] ""  ACC,LAS,APA,FC,mADC
 SG_ HU_DVRPrintScreen : 87|2@0+ (1,0) [0|3] ""  APA
 SG_ HU_AVMCalibrationConfirm : 73|2@0+ (1,0) [0|3] ""  APA
 SG_ HU_IACCEnable : 29|2@0+ (1,0) [0|3] ""  LAS,FC,mADC
 SG_ HU_LockCtrlEnable : 27|2@0+ (1,0) [0|3] "" Vector__XXX
 SG_ HU_AudioWarningEnable : 25|2@0+ (1,0) [0|3] ""  mADC
 SG_ HU_LDWShakeLev : 23|2@0+ (1,0) [0|3] "" Vector__XXX
 SG_ HU_SEAEnable : 17|2@0+ (1,0) [0|3] ""  mADC
 SG_ HU_RCTAEnable : 0|2@0+ (1,0) [0|3] ""  mADC
 SG_ HU_RCWEnable : 14|2@0+ (1,0) [0|3] ""  mADC
 SG_ HU_HMAEnable : 75|2@0+ (1,0) [0|3] ""  LAS,FC,mADC
 SG_ HU_TSRSwitch : 11|1@0+ (1,0) [0|1] ""  LAS,mADC
 SG_ HU_LASWarningModeSelection : 10|3@0+ (1,0) [0|7] ""  APA,mADC,FC,LAS
 SG_ HU_LASModeSelection : 5|3@0+ (1,0) [0|7] ""  LAS,FC,mADC
 SG_ HU_ObstacleSafeDistanceSet : 58|3@0+ (1,0) [0|7] "cm"  APA
 SG_ HU_ParkingConfirm : 54|1@0+ (1,0) [0|1] ""  APA
 SG_ HU_RemoteDistanceSet : 53|4@0+ (1,0) [0|15] "m"  APA
 SG_ HU_ParkingResume : 46|1@0+ (1,0) [0|1] ""  APA
 SG_ HU_Uls_FKP_Activation : 45|2@0+ (1,0) [0|3] ""  APA
 SG_ HU_Uls_BSD_Activation : 41|2@0+ (1,0) [0|3] ""  APA
 SG_ HU_OverspeedWarningOffset : 239|6@0+ (1,-10) [-10|47] ""  LAS,mADC
 SG_ HU_OverspeedWarningEnable : 33|2@0+ (1,0) [0|3] ""  LAS,mADC
 SG_ HU_OverspeedSoundWarEnable : 31|2@0+ (1,0) [0|3] ""  LAS,mADC
 SG_ HU_FatigueDectionEnable : 21|2@0+ (1,0) [0|3] "" Vector__XXX
 SG_ HU_DVRBrowseCommand : 127|4@0+ (1,0) [0|15] ""  APA
 SG_ HU_NDAAudioWarEnable : 169|2@0+ (1,0) [0|3] ""  ACC,LAS,mADC
 SG_ HU_RampAVMSwitch : 113|2@0+ (1,0) [0|3] ""  APA
 SG_ HU_NDASetSpdMode : 181|2@0+ (1,0) [0|3] "" Vector__XXX
 SG_ HU_HZPOnOff : 47|1@0+ (1,0) [0|1] ""  APA
 SG_ HU_HZPRecomendRes : 39|1@0+ (1,0) [0|1] ""  APA

BO_ 1302 GW_516: 32 GW
 SG_ HU_AirHumidityValid : 87|1@0+ (1,0) [0|1] "" Vector__XXX
 SG_ HU_AirHumidity : 70|7@0+ (1,0) [0|100] "%" Vector__XXX
 SG_ HU_LeaveMaintainMileage : 147|20@0+ (1,0) [0|100000] "km" Vector__XXX
 SG_ HU_LeaveMaintainDay : 131|12@0+ (1,0) [0|3100] "天" Vector__XXX
 SG_ HU_MaintainRemindReq : 133|2@0+ (1,0) [0|3] "" Vector__XXX
 SG_ HU_LocalTimeSystem : 111|2@0+ (1,0) [0|3] ""  APA,ACC,LAS,FC,HPP,mADC
 SG_ HU_LocalTimeSecond : 109|6@0+ (1,0) [0|59] "second"  APA,ACC,LAS,FC,HPP,mADC
 SG_ HU_LocalTimeMinute : 101|6@0+ (1,0) [0|59] "minute"  APA,ACC,LAS,FC,HPP,mADC
 SG_ HU_LocalTimeHour : 92|5@0+ (1,0) [0|23] "hour"  APA,ACC,LAS,FC,HPP,mADC
 SG_ HU_LocalTimeDate : 84|5@0+ (1,0) [1|31] "day"  APA,ACC,LAS,FC,HPP,mADC
 SG_ HU_LocalTimeYear : 119|8@0+ (1,2013) [2013|2268] "year"  APA,ACC,LAS,FC,mADC
 SG_ HU_LocalTimeMonth : 75|4@0+ (1,0) [1|12] "month"  APA,ACC,LAS,FC,mADC
 SG_ HU_LocalTimeValid : 71|1@0+ (1,0) [0|1] ""  APA,ACC,LAS,FC,mADC
 SG_ HU_CurrentLocationLatitude : 35|28@0+ (1E-006,-134.217727) [-90|90] "degree"  APA,ACC,LAS,FC,mADC
 SG_ HU_CurrentLocationLongitude : 4|29@0+ (1E-006,-268.435455) [-180|180] "degree"  APA,ACC,LAS,FC,mADC
 SG_ HU_CurrentLocationValid : 7|1@0+ (1,0) [0|1] ""  APA,ACC,LAS,FC,mADC
 SG_ HU_CurrentLocationstd : 175|14@0+ (0.01,0) [0|100] "m"  APA

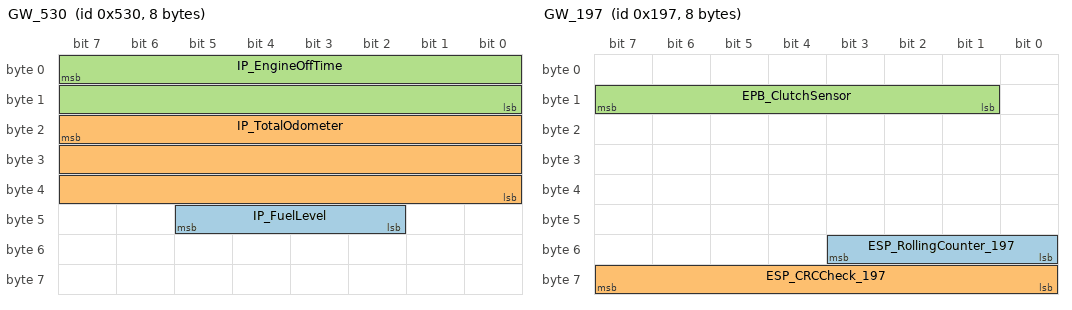
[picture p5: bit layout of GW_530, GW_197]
BO_ 1328 GW_530: 8 GW
 SG_ IP_FuelLevel : 45|4@0+ (1,0) [0|15] "" Vector__XXX
 SG_ IP_TotalOdometer : 23|24@0+ (0.1,0) [0|999999] "Km"  LAS,FC,ACC,HPP,APA,mADC
 SG_ IP_EngineOffTime : 7|16@0+ (1,0) [0|65535] "s" Vector__XXX

BO_ 391 GW_187: 8 GW
 SG_ IBCU_BrakeFluid_Warning : 27|2@0+ (1,0) [0|3] ""  APA
 SG_ ESP_VehicleSpeed : 36|13@0+ (0.05625,0) [0|360] "km/h"  APA,ACC,LAS,FC,HPP
 SG_ ESP_VehicleSpeedValid : 37|1@0+ (1,0) [0|1] ""  APA,ACC,LAS,FC,HPP
 SG_ ESP_TorqIncwhlFront : 15|15@0+ (1,-5400) [-5400|12000] "Nm"  APA
 SG_ ESP_TCSFailStatus : 4|1@0+ (1,0) [0|1] ""  APA,ACC,LAS,FC
 SG_ ESP_RollingCounter_187 : 51|4@0+ (1,0) [0|15] ""  ACC,LAS,FC,APA,HPP
 SG_ ESP_GearHoldRequestValid : 5|1@0+ (1,0) [0|1] "" Vector__XXX
 SG_ ESP_GearHoldRequest : 6|1@0+ (1,0) [0|1] "" Vector__XXX
 SG_ ESP_ESPFunctionStatus : 1|1@0+ (1,0) [0|1] ""  APA,ACC,LAS,FC
 SG_ ESP_ESPActiveStatus : 0|1@0+ (1,0) [0|1] ""  APA,ACC,LAS,FC
 SG_ ESP_EngTorqIncFrontActive : 38|1@0+ (1,0) [0|1] ""  LAS,ACC,APA
 SG_ ESP_EngTorqDecActive : 39|1@0+ (1,0) [0|1] ""  LAS,ACC,APA
 SG_ ESP_EBDFailStatus : 2|1@0+ (1,0) [0|1] ""  APA
 SG_ ESP_CRCCheck_187 : 63|8@0+ (1,0) [0|255] ""  APA,ACC,LAS,FC,HPP
 SG_ ESP_ADBF_Active : 52|1@0+ (1,0) [0|1] "" Vector__XXX
 SG_ ESP_ABSFailStatus : 3|1@0+ (1,0) [0|1] ""  APA,ACC,LAS,FC
 SG_ ESP_ABSActiveStatus : 7|1@0+ (1,0) [0|1] ""  ACC,LAS,FC,APA
 SG_ EPBi_MILReq : 55|1@0+ (1,0) [0|1] "" Vector__XXX
 SG_ EPBi_ClearDiagnosticInfo : 25|2@0+ (1,0) [0|3] "" Vector__XXX

BO_ 407 GW_197: 8 GW
 SG_ ESP_RollingCounter_197 : 51|4@0+ (1,0) [0|15] ""  ACC,LAS,APA
 SG_ ESP_CRCCheck_197 : 63|8@0+ (1,0) [0|255] ""  APA,ACC,LAS,FC,HPP
 SG_ EPB_ClutchSensor : 15|7@0+ (1,0) [0|100] "%"  APA

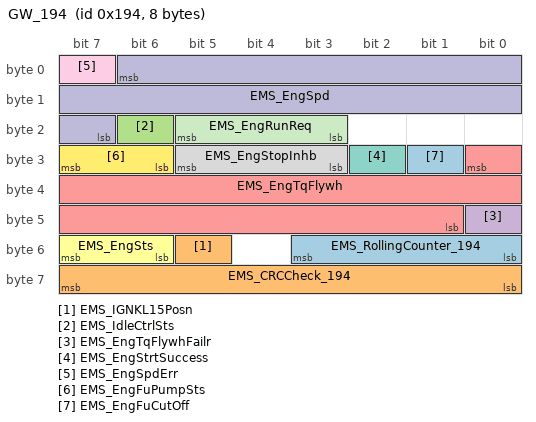
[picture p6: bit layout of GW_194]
BO_ 404 GW_194: 8 GW
 SG_ EMS_RollingCounter_194 : 51|4@0+ (1,0) [0|15] ""  ACC,LAS,FC
 SG_ EMS_IGNKL15Posn : 53|1@0+ (1,0) [0|1] "" Vector__XXX
 SG_ EMS_IdleCtrlSts : 22|1@0+ (1,0) [0|1] "" Vector__XXX
 SG_ EMS_EngTqFlywhFailr : 40|1@0+ (1,0) [0|1] "" Vector__XXX
 SG_ EMS_EngTqFlywh : 24|16@0+ (0.02,-350) [-350|400] "Nm" Vector__XXX
 SG_ EMS_EngSts : 55|2@0+ (1,0) [0|3] ""  APA,ACC,LAS,FC
 SG_ EMS_EngStrtSuccess : 26|1@0+ (1,0) [0|1] "" Vector__XXX
 SG_ EMS_EngStopInhb : 29|3@0+ (1,0) [0|3] "" Vector__XXX
 SG_ EMS_EngSpdErr : 7|1@0+ (1,0) [0|1] ""  ACC,LAS,FC
 SG_ EMS_EngSpd : 6|16@0+ (0.25,0) [0|16383.5] "Rpm"  ACC,LAS,FC
 SG_ EMS_EngRunReq : 21|3@0+ (1,0) [0|3] "" Vector__XXX
 SG_ EMS_EngFuPumpSts : 31|2@0+ (1,0) [0|3] "" Vector__XXX
 SG_ EMS_EngFuCutOff : 25|1@0+ (1,0) [0|1] ""  LAS,ACC
 SG_ EMS_CRCCheck_194 : 63|8@0+ (1,0) [0|255] ""  ACC,LAS,FC,APA,HPP

CM_ BO_ 898 " ";
CM_ SG_ 898 ACC_Target5ZoneID " ";
CM_ SG_ 898 ACC_Target5HeadingAngle " ";
CM_ SG_ 898 ACC_Target5Direction " ";
CM_ SG_ 898 ACC_Target5LatRange " ";
CM_ SG_ 898 ACC_Target5LngRange " ";
CM_ SG_ 898 ACC_Target5Type " ";
CM_ SG_ 898 ACC_Target5ID " ";
CM_ SG_ 898 ACC_Target5Detection " ";
CM_ SG_ 898 ACC_Target4ZoneID "ACC 主控则ACC发送，LAS 主控则LAS发送 ";
CM_ SG_ 898 ACC_Target4HeadingAngle "ACC 主控则ACC发送，LAS 主控则LAS发送 ";
CM_ SG_ 898 ACC_Target4Direction "ACC 主控则ACC发送，LAS 主控则LAS发送 ";
CM_ SG_ 898 ACC_Target4LatRange "ACC 主控则ACC发送，LAS 主控则LAS发送 ";
CM_ SG_ 898 ACC_Target4LngRange "ACC 主控则ACC发送，LAS 主控则LAS发送 ";
CM_ SG_ 898 ACC_Target4Type "ACC 主控则ACC发送，LAS 主控则LAS发送 ";
CM_ SG_ 898 ACC_Target4ID "ACC 主控则ACC发送，LAS 主控则LAS发送 ";
CM_ SG_ 898 ACC_Target4Detection "ACC 主控则ACC发送，LAS 主控则LAS发送 ";
CM_ SG_ 898 ACC_Target3ZoneID "ACC 主控则ACC发送，LAS 主控则LAS发送 ";
CM_ SG_ 898 ACC_Target3HeadingAngle "ACC 主控则ACC发送，LAS 主控则LAS发送 ";
CM_ SG_ 898 ACC_Target3Direction "ACC 主控则ACC发送，LAS 主控则LAS发送 ";
CM_ SG_ 898 ACC_Target3LatRange "ACC 主控则ACC发送，LAS 主控则LAS发送 ";
CM_ SG_ 898 ACC_Target3LngRange "ACC 主控则ACC发送，LAS 主控则LAS发送 ";
CM_ SG_ 898 ACC_Target3Type "ACC 主控则ACC发送，LAS 主控则LAS发送 ";
CM_ SG_ 898 ACC_Target3ID "ACC 主控则ACC发送，LAS 主控则LAS发送 ";
CM_ SG_ 898 ACC_Target3Detection "ACC 主控则ACC发送，LAS 主控则LAS发送 ";
CM_ SG_ 898 ACC_Target2ZoneID "ACC 主控则ACC发送，LAS 主控则LAS发送 ";
CM_ SG_ 898 ACC_Target2HeadingAngle "ACC 主控则ACC发送，LAS 主控则LAS发送 ";
CM_ SG_ 898 ACC_Target2Direction "ACC 主控则ACC发送，LAS 主控则LAS发送 ";
CM_ SG_ 898 ACC_Target2LatRange "ACC 主控则ACC发送，LAS 主控则LAS发送 ";
CM_ SG_ 898 ACC_Target2LngRange "ACC 主控则ACC发送，LAS 主控则LAS发送 ";
CM_ SG_ 898 ACC_Target2Type "ACC 主控则ACC发送，LAS 主控则LAS发送 ";
CM_ SG_ 898 ACC_Target2ID "ACC 主控则ACC发送，LAS 主控则LAS发送 ";
CM_ SG_ 898 ACC_Target2Detection "ACC 主控则ACC发送，LAS 主控则LAS发送 ";
CM_ SG_ 898 ACC_Target1ZoneID "ACC 主控则ACC发送，LAS 主控则LAS发送 ";
CM_ SG_ 898 ACC_Target1HeadingAngle "ACC 主控则ACC发送，LAS 主控则LAS发送 ";
CM_ SG_ 898 ACC_Target1Direction "ACC 主控则ACC发送，LAS 主控则LAS发送 ";
CM_ SG_ 898 ACC_Target1LatRange "ACC 主控则ACC发送，LAS 主控则LAS发送 ";
CM_ SG_ 898 ACC_Target1LngRange "ACC 主控则ACC发送，LAS 主控则LAS发送 ";
CM_ SG_ 898 ACC_Target1Type "ACC 主控则ACC发送，LAS 主控则LAS发送 ";
CM_ SG_ 898 ACC_Target1ID "ACC 主控则ACC发送，LAS 主控则LAS发送 ";
CM_ SG_ 898 ACC_Target1Detection "ACC 主控则ACC发送，LAS 主控则LAS发送 ";
CM_ SG_ 898 ACC_RollingCounter_3E6 " ";
CM_ SG_ 898 ACC_CRCCheck_3E6 "ACC 主控则ACC发送，LAS 主控则LAS发送 ";
CM_ SG_ 898 ACC_CRCCheck_35C "ACC 主控则ACC发送，LAS 主控则LAS发送 ";
CM_ SG_ 898 ACC_RollingCounter_35C "ACC 主控则ACC发送，LAS 主控则LAS发送 ";
CM_ SG_ 898 ACC_CRCCheck_35D " ";
CM_ SG_ 898 ACC_RollingCounter_35D " ";
CM_ SG_ 898 ACC_LaneEquationStatus "ACC 主控则ACC发送，LAS 主控则LAS发送 ";
CM_ SG_ 898 ACC_LaneEquationC3 "ACC 主控则ACC发送，LAS 主控则LAS发送 ";
CM_ SG_ 898 ACC_LaneEquationC2 "ACC 主控则ACC发送，LAS 主控则LAS发送 ";
CM_ SG_ 898 ACC_LaneEquationC1 "ACC 主控则ACC发送，LAS 主控则LAS发送 ";
CM_ SG_ 898 ACC_LaneQuality "ACC 主控则ACC发送，LAS 主控则LAS发送 ";
CM_ BO_ 676 " ";
CM_ SG_ 676 LCDAR_Left_RCTAAlert " ";
CM_ SG_ 676 LCDAR_BSD_LCASoundWar " ";
CM_ SG_ 676 LCDAR_RCTBStatus "ACC 主控则ACC接收，LAS 主控则LAS接收 ";
CM_ SG_ 676 LCDAR_CRCCheck_2AF " ";
CM_ SG_ 676 LCDAR_RollingCounter_2AF "rolling counter ";
CM_ SG_ 676 LCDAR_ELK_oAlert " ";
CM_ SG_ 676 LCDAR_ELK_oStatus " ";
CM_ SG_ 676 LCDAR_Left_ELK_oAlert " ";
CM_ SG_ 676 LCDAR_RCTBActive "ACC 主控则ACC接收，LAS 主控则LAS接收 ";
CM_ SG_ 676 LCDAR_RCTBTargetDecel "ACC 主控则ACC接收，LAS 主控则LAS接收 ";
CM_ SG_ 676 LCDAR_RCTBEnable " ";
CM_ BO_ 1893 "CANFD诊断仪使用 ";
CM_ BO_ 1901 "CANFD诊断仪使用 ";
CM_ BO_ 1937 "CAN诊断仪使用 ";
CM_ BO_ 1945 "CAN诊断仪使用 ";
CM_ BO_ 1874 "CANFD诊断仪使用 ";
CM_ BO_ 1882 "CANFD诊断仪使用 ";
CM_ BO_ 1891 "CAN诊断仪使用 ";
CM_ BO_ 1899 "CAN诊断仪使用 ";
CM_ BO_ 1426 " ";
CM_ SG_ 1426 LAS_NotSleep_BYTE7BIT1 " ";
CM_ SG_ 1426 LAS_NotSleep_BYTE7BIT0 " ";
CM_ SG_ 1426 LAS_WakeUp_BYTE4BIT1 " ";
CM_ SG_ 1426 LAS_WakeUp_BYTE4BIT0 " ";
CM_ BO_ 1428 " ";
CM_ SG_ 1428 FR_NotSleep_BYTE7BIT1 " ";
CM_ SG_ 1428 FR_NotSleep_BYTE7BIT0 " ";
CM_ SG_ 1428 FR_WakeUp_BYTE4BIT1 " ";
CM_ SG_ 1428 FR_WakeUp_BYTE4BIT0 " ";
CM_ BO_ 80 " ";
CM_ SG_ 80 SRS_PassengerBuckleSwitchStatus "For PDM is configured projects=
(if PDM is configured, logical detection with PDM is required)
0x0= [Buckled] or [Unbuckled and passenger not occupied]
0x1= [Unbuckle and passenger occupied]
0x2= Not Used
0x3= Not Used
 ";
CM_ SG_ 80 SRS_FrontPsgOccupancy "副驾座椅重量检测传感器与副驾安全带扣串联的车型不发该信号 ";
CM_ SG_ 80 SRS_PADIndication "SRS_PADIndication =0=off时副驾驶气囊打开指示灯点亮，   SRS_PADIndication =1=on时副驾驶气囊关闭指示灯点亮 ";
CM_ SG_ 80 SRS_DriverBuckleSwitchStatus " ";
CM_ SG_ 80 SRS_RollingCounter_id050 "ACM接收为AT专用 ";
CM_ BO_ 368 " ";
CM_ SG_ 368 EPS_fault_state "APA配置接收方无BDC ";
CM_ SG_ 368 EPS_ActualMotorTorq " ";
CM_ SG_ 368 EPS_CRCCheck_170 "平台为10ms，CD569特例为8ms ";
CM_ SG_ 368 EPS_RollingCounter_170 "平台为10ms，CD569特例为8ms ";
CM_ SG_ 368 EPS_ActualTorsionBarTorq "平台为10ms，CD569特例为8ms ";
CM_ SG_ 368 EPS_MinSafetyTorsionBarTorq "平台为10ms，CD569特例为8ms ";
CM_ SG_ 368 EPS_MaxSafetyTorsionBarTorq "平台为10ms，CD569特例为8ms ";
CM_ BO_ 384 " ";
CM_ SG_ 384 SAS_SteeringAngle "APA配置接收方无BDC ";
CM_ BO_ 580 " ";
CM_ SG_ 580 ADS_EOMTOReq "ACC 主控则ACC发送，LAS 主控则LAS发送 ";
CM_ SG_ 580 ACC_HandsOnReq "ACC 主控则ACC发送，LAS 主控则LAS发送 ";
CM_ SG_ 580 ACC_LatTakeoverReq "ACC 主控则ACC发送，LAS 主控则LAS发送 ";
CM_ SG_ 580 ACC_LngTakeOverReq "ACC 主控则ACC发送，LAS 主控则LAS发送 ";
CM_ SG_ 580 ACC_LDWShakeLevStatus "ACC 主控则ACC发送，LAS 主控则LAS发送 ";
CM_ SG_ 580 ACC_TextInfoForDriver "ACC 主控则ACC发送，LAS 主控则LAS发送 ";
CM_ SG_ 580 ADS__RollingCounter_244 "ACC 主控则ACC发送，LAS 主控则LAS发送 ";
CM_ SG_ 580 ADS_CRCCheck_244 "ACC 主控则ACC发送，LAS 主控则LAS发送 ";
CM_ SG_ 580 ACC_CRCCheck_25E "ACC 主控则ACC发送，LAS 主控则LAS发送 ";
CM_ SG_ 580 ACC_RollingCounter_25E "ACC 主控则ACC发送，LAS 主控则LAS发送 ";
CM_ SG_ 580 ACC_AEBCtrlType "ACC 主控则ACC发送，LAS 主控则LAS发送 ";
CM_ SG_ 580 ACC_AccTrqReq "ACC 主控则ACC发送，LAS 主控则LAS发送 ";
CM_ SG_ 580 ACC_AccTrqReqActive "ACC 主控则ACC发送，LAS 主控则LAS发送 ";
CM_ SG_ 580 ACC_AEBVehilceHoldReq "ACC 主控则ACC发送，LAS 主控则LAS发送 ";
CM_ SG_ 580 ACC_FCWPreWarning "ACC 主控则ACC发送，LAS 主控则LAS发送 ";
CM_ SG_ 580 ACC_FCWLatentWarning "ACC 主控则ACC发送，LAS 主控则LAS发送 ";
CM_ SG_ 580 ACC_FCWActive "ACC 主控则ACC发送，LAS 主控则LAS发送 ";
CM_ SG_ 580 ACC_PrefillActive "ACC 主控则ACC发送，LAS 主控则LAS发送 ";
CM_ SG_ 580 ACC_AWBActive "ACC 主控则ACC发送，LAS 主控则LAS发送 ";
CM_ SG_ 580 ACC_AWBlevel "ACC 主控则ACC发送，LAS 主控则LAS发送 ";
CM_ SG_ 580 ACC_ABAActive "ACC 主控则ACC发送，LAS 主控则LAS发送 ";
CM_ SG_ 580 ACC_ABAlevel "ACC 主控则ACC发送，LAS 主控则LAS发送 ";
CM_ SG_ 580 ACC_AEBActive "ACC 主控则ACC发送，LAS 主控则LAS发送 ";
CM_ SG_ 580 ACC_AEBTargetDeceleration "ACC 主控则ACC发送，LAS 主控则LAS发送 ";
CM_ SG_ 580 ACC_EmergencyDataRrdReq "ACC 主控则ACC发送，LAS 主控则LAS发送 ";
CM_ SG_ 580 ACC_CRCCheck_24E "ACC 主控则ACC发送，LAS 主控则LAS发送 ";
CM_ SG_ 580 ACC_RollingCounter_24E "ACC 主控则ACC发送，LAS 主控则LAS发送 ";
CM_ SG_ 580 ACC_Driveoff_Request "ACC 主控则ACC发送，LAS 主控则LAS发送 ";
CM_ SG_ 580 ACC_ACCMode "ACC 主控则ACC发送，LAS 主控则LAS发送 ";
CM_ SG_ 580 ACC_CDDActive "ACC 主控则ACC发送，LAS 主控则LAS发送 ";
CM_ SG_ 580 ACC_DecToStop "ACC 主控则ACC发送，LAS 主控则LAS发送 ";
CM_ SG_ 580 ACC_LKAStatus "ACC 主控则ACC发送，LAS 主控则LAS发送 ";
CM_ SG_ 580 ACC_LDWVibrationWarningReq "ACC 主控则ACC发送，LAS 主控则LAS发送，其余由APA或AVM发送 ";
CM_ SG_ 580 ACC_LDWStatus "ACC 主控则ACC发送，LAS 主控则LAS发送，其余由APA或AVM发送 ";
CM_ SG_ 580 ACC_ACCTargetAcceleration "1、ACC target acceleration for transmission.
2、ACC 主控则ACC发送，LAS 主控则LAS发送 ";
CM_ BO_ 632 " ";
CM_ SG_ 632 ESP_LongAccel "APA配置接收方无BDC ";
CM_ BO_ 664 " ";
CM_ SG_ 664 PEPS_Welcomelamp "C207独有 ";
CM_ BO_ 775 " ";
CM_ SG_ 775 ACC_AEBTargetSelected "同C236 ";
CM_ SG_ 775 ACC_AEBFeatureConfig "同C236 ";
CM_ SG_ 775 ACC_ACCTargetLngRange "欧尚专用 ";
CM_ SG_ 775 ACC_RLaneDistanceFus "ACC 主控则ACC发送，LAS 主控则LAS发送 ";
CM_ SG_ 775 ACC_LLaneDistanceFus "ACC 主控则ACC发送，LAS 主控则LAS发送 ";
CM_ SG_ 775 ACC_RRLaneDis "ACC 主控则ACC发送，LAS 主控则LAS发送 ";
CM_ SG_ 775 ACC_LLLaneDis "ACC 主控则ACC发送，LAS 主控则LAS发送 ";
CM_ SG_ 775 ACC_Target7ZoneID "ACC 主控则ACC发送，LAS 主控则LAS发送 ";
CM_ SG_ 775 ACC_Target7HeadingAngle "ACC 主控则ACC发送，LAS 主控则LAS发送 ";
CM_ SG_ 775 ACC_Target7Direction "ACC 主控则ACC发送，LAS 主控则LAS发送 ";
CM_ SG_ 775 ACC_Target7LatRange "ACC 主控则ACC发送，LAS 主控则LAS发送 ";
CM_ SG_ 775 ACC_Target7LngRange "ACC 主控则ACC发送，LAS 主控则LAS发送 ";
CM_ SG_ 775 ACC_Target7Type "ACC 主控则ACC发送，LAS 主控则LAS发送 ";
CM_ SG_ 775 ACC_Target7ID "ACC 主控则ACC发送，LAS 主控则LAS发送 ";
CM_ SG_ 775 ACC_Target7Detection "ACC 主控则ACC发送，LAS 主控则LAS发送 ";
CM_ SG_ 775 ACC_Target6ZoneID "ACC 主控则ACC发送，LAS 主控则LAS发送 ";
CM_ SG_ 775 ACC_Target6HeadingAngle "ACC 主控则ACC发送，LAS 主控则LAS发送 ";
CM_ SG_ 775 ACC_Target6Direction "ACC 主控则ACC发送，LAS 主控则LAS发送 ";
CM_ SG_ 775 ACC_Target6LatRange "ACC 主控则ACC发送，LAS 主控则LAS发送 ";
CM_ SG_ 775 ACC_Target6LngRange "ACC 主控则ACC发送，LAS 主控则LAS发送 ";
CM_ SG_ 775 ACC_Target6Type "ACC 主控则ACC发送，LAS 主控则LAS发送 ";
CM_ SG_ 775 ACC_Target6ID "ACC 主控则ACC发送，LAS 主控则LAS发送 ";
CM_ SG_ 775 ACC_Target6Detection "ACC 主控则ACC发送，LAS 主控则LAS发送 ";
CM_ SG_ 775 ACC_AEBEnable "ACC 主控则ACC发送，LAS 主控则LAS发送 ";
CM_ SG_ 775 ACC_VehicleStartRemindSts "ACC 主控则ACC发送，LAS 主控则LAS发送 ";
CM_ SG_ 775 ACC_CRCCheck_35F "ACC 主控则ACC发送，LAS 主控则LAS发送 ";
CM_ SG_ 775 ACC_RollingCounter_35F "ACC 主控则ACC发送，LAS 主控则LAS发送 ";
CM_ SG_ 775 ACC_CSLAEnableStatus "ACC 主控则ACC发送，LAS 主控则LAS发送 ";
CM_ SG_ 775 ACC_CSLSetReq "ACC 主控则ACC发送，LAS 主控则LAS发送 ";
CM_ SG_ 775 ACC_CRCCheck_344 "ACC 主控则ACC发送，LAS 主控则LAS发送 ";
CM_ SG_ 775 ACC_RollingCounter_344 "ACC 主控则ACC发送，LAS 主控则LAS发送 ";
CM_ SG_ 775 ACC_CRCCheck_322 "ACC 主控则ACC发送，LAS 主控则LAS发送 ";
CM_ SG_ 775 ACC_RollingCounter_322 "ACC 主控则ACC发送，LAS 主控则LAS发送 ";
CM_ SG_ 775 ACC_ACCTargetRelSpd "ACC 主控则ACC发送，LAS 主控则LAS发送 ";
CM_ SG_ 775 ACC_CRCCheck_35E "ACC 主控则ACC发送，LAS 主控则LAS发送 ";
CM_ SG_ 775 ACC_RollingCounter_35E "ACC 主控则ACC发送，LAS 主控则LAS发送 ";
CM_ SG_ 775 ACC_FCWSettingStatus "ACC 主控则ACC发送，LAS 主控则LAS发送 ";
CM_ SG_ 775 ACC_ACCEPBrequest "ACC 主控则ACC发送，LAS 主控则LAS发送 ";
CM_ SG_ 775 ACC_ObjValid "ACC 主控则ACC发送，LAS 主控则LAS发送 ";
CM_ SG_ 775 ACC_TimeGapSet "ACC 主控则ACC发送，LAS 主控则LAS发送 ";
CM_ SG_ 775 ACC_DistanceLevel "ACC 主控则ACC发送，LAS 主控则LAS发送 ";
CM_ SG_ 775 ACC_SetSpeed "ACC 主控则ACC发送，LAS 主控则LAS发送 ";
CM_ BO_ 786 " ";
CM_ SG_ 786 ACC_AEBTargetFourWheelProb "新增，取值范围同 ACC_AEBTargetProb ";
CM_ SG_ 786 ACC_AEBTargetProb "借鉴C385 ";
CM_ SG_ 786 ACC_Selflearning_status "ACC 主控则ACC发送，LAS 主控则LAS发送 ";
CM_ SG_ 786 ACC_Selflearning_angle "ACC 主控则ACC发送，LAS 主控则LAS发送 ";
CM_ SG_ 786 ADS_NDAAudioWarEnableStatus "ACC 主控则ACC发送，LAS 主控则LAS发送 ";
CM_ SG_ 786 ADS_ADSVoiceRequest "ACC 主控则ACC发送，LAS 主控则LAS发送 ";
CM_ SG_ 786 ADS_EOMWarnning " ";
CM_ SG_ 786 ADS_CRCCheck_3D7 " ";
CM_ SG_ 786 ADS_RollingCounter_3D7 " ";
CM_ SG_ 786 ACC_DriverWindowControl "ACC 主控则ACC发送，LAS 主控则LAS发送 ";
CM_ SG_ 786 ACC_AEBTargetDirection "ACC 主控则ACC发送，LAS 主控则LAS发送 ";
CM_ SG_ 786 ACC_AEBTargetDetection "ACC 主控则ACC发送，LAS 主控则LAS发送 ";
CM_ SG_ 786 ACC_AEBTargetType "ACC 主控则ACC发送，LAS 主控则LAS发送 ";
CM_ SG_ 786 ACC_CRCCheck_3E4 "ACC 主控则ACC发送，LAS 主控则LAS发送 ";
CM_ SG_ 786 ACC_RollingCounter_3E4 "ACC 主控则ACC发送，LAS 主控则LAS发送 ";
CM_ BO_ 832 "源端B_TMS_340或
HybridA_TMS_398,6 ";
CM_ SG_ 832 AC_PrAirMergePortOpeningRatioVD "国6增加
双暖通（S401及改款）国六项目（新增） ";
CM_ SG_ 832 AC_PrAirMergePortOpeningRatio "国6增加
双暖通（S401及改款）国六项目（新增） ";
CM_ SG_ 832 AC_DrAirMergePortOpeningRatioVD "国6增加
双暖通（S401及改款）国六项目（新增） ";
CM_ SG_ 832 AC_DrAirMergePortOpeningRatio "国6增加
双暖通（S401及改款）国六项目（新增） ";
CM_ SG_ 832 AC_RrAirMergePortOpeningRatioVD "国6增加
双暖通（S401及改款）国六项目（新增） ";
CM_ SG_ 832 AC_RrAirMergePortOpeningRatio "国6增加
双暖通（S401及改款）国六项目（新增） ";
CM_ SG_ 832 AC_RrReqWindLevelVD "国6增加
双暖通（S401及改款）国六项目（新增） ";
CM_ BO_ 839 " ";
CM_ SG_ 839 TPMS_RRPressureWarning "1、无效值是为转DBC
2、ACC 主控则ACC接收，LAS 主控则LAS接收 ";
CM_ SG_ 839 TPMS_LRPressureWarning "1、无效值是为转DBC
2、ACC 主控则ACC接收，LAS 主控则LAS接收 ";
CM_ SG_ 839 TPMS_SystemFailureWarning "无效值是为转DBC ";
CM_ SG_ 839 BCM_TirePresureSignalStatus "无效值是为转DBC ";
CM_ SG_ 839 TPMS_LFPressureWarning "1、无效值是为转DBC
2、ACC 主控则ACC接收，LAS 主控则LAS接收 ";
CM_ SG_ 839 TPMS_RFPressureWarning "1、无效值是为转DBC
2、ACC 主控则ACC接收，LAS 主控则LAS接收 ";
CM_ SG_ 839 TPMS_LRTyrePressure "ACC 主控则ACC接收，LAS 主控则LAS接收 ";
CM_ SG_ 839 TPMS_RRTyrePressure "ACC 主控则ACC接收，LAS 主控则LAS接收 ";
CM_ SG_ 839 TPMS_RFTyrePressure "ACC 主控则ACC接收，LAS 主控则LAS接收 ";
CM_ SG_ 839 TPMS_LFTyrePressure "ACC 主控则ACC接收，LAS 主控则LAS接收 ";
CM_ BO_ 869 " ";
CM_ SG_ 869 DMS_Zlocation_eye " ";
CM_ SG_ 869 DMS_Ylocation_eye " ";
CM_ SG_ 869 DMS_Xlocation_eye " ";
CM_ SG_ 869 IMS_JawOffsetValue " ";
CM_ SG_ 869 IMS_BrowOffsetValue " ";
CM_ SG_ 869 IMS_PhoneCallSts " ";
CM_ SG_ 869 IMS_DistractionWarning " ";
CM_ SG_ 869 IMS_DistractionSetFb " ";
CM_ SG_ 869 IMS_DrowsinessSetFb " ";
CM_ SG_ 869 IMS_DrowsinessSensFb " ";
CM_ SG_ 869 IMS_DrowsinessWarning " ";
CM_ SG_ 869 IMS_IDUpdateRemind " ";
CM_ SG_ 869 IMS_DriverID " ";
CM_ SG_ 869 IMS_HeadDetectSts_Yaw " ";
CM_ SG_ 869 IMS_HeadDetectSts_Roll " ";
CM_ SG_ 869 IMS_HeadDetectSts_Pitch " ";
CM_ SG_ 869 IMS_IMSStatus " ";
CM_ SG_ 869 IMS_EyeGazeStatus " ";
CM_ SG_ 869 IMS_EyeDetectSatus "10以下认为闭眼 ";
CM_ SG_ 869 IMS_DrowsinessStatus " ";
CM_ SG_ 869 IMS_DriverHeadDetect " ";
CM_ SG_ 869 IMS_DistractionStatus " ";
CM_ BO_ 870 "源端B_TMS_366或
HybridA_TMS_398,3 ";
CM_ SG_ 870 AC_FrReqWindLevelVD "国6增加
双暖通（S401及改款）国六项目（新增） ";
CM_ BO_ 903 " ";
CM_ SG_ 903 BCM_BLEKeyIndicator "GW报文转发 ";
CM_ SG_ 903 BCM_FrontWashStatus "未平台化，仅S401发送 ";
CM_ SG_ 903 BCM_SystemFailureFlag "APA配置接收方无BDC ";
CM_ SG_ 903 BCM_DriveModeSet "仅用于S302 ";
CM_ BO_ 912 " ";
CM_ SG_ 912 BCM_PMSLevel "无效值是为转DBC ";
CM_ SG_ 912 BCM_LowPowerWarning "无效值是为转DBC ";
CM_ BO_ 918 " ";
CM_ SG_ 918 BCM_RemoteWindowControl "此信号用于纹波防夹，非霍尔防夹 ";
CM_ SG_ 918 BCM_Sunroof_POS_Direction "Relative position of window in percent.
When the signal “Sunroof_POS_Direction”=0=
0%表示天窗完全关闭。
100%表示天窗全开。
信号精度5%
When the signal “Sunroof_POS_Direction”=1=
0%表示天窗完全关闭。
100%表示完全起翘。
信号精度10%    ";
CM_ BO_ 1287 " ";
CM_ SG_ 1287 HU_NDANavEnable " ";
CM_ SG_ 1287 HU_NDAEnable " ";
CM_ SG_ 1287 HU_LaneChangeStyle " ";
CM_ SG_ 1287 HU_FCTAEnable " ";
CM_ SG_ 1287 HU_FCTBEnable " ";
CM_ SG_ 1287 HU_RCTBEnable " ";
CM_ SG_ 1287 HU_VC_CruiseSetSpeed "ACC 主控则ACC接收，LAS 主控则LAS接收 ";
CM_ SG_ 1287 HU_VC_CruiseSetDistance "ACC 主控则ACC接收，LAS 主控则LAS接收 ";
CM_ SG_ 1287 HU_VC_CruiseControl "ACC 主控则ACC接收，LAS 主控则LAS接收 ";
CM_ SG_ 1287 HU_FCWSetting "ACC 主控则ACC接收，LAS 主控则LAS接收 ";
CM_ SG_ 1287 HU_FrontRadarActive "0x1= Activate用于软按键和语音激活；
0x2= Deactivate用于软按键和语音关闭；发送0x1/0x2的逻辑由HU判断，初始化和故障时发0x0=Invalid ";
CM_ SG_ 1287 HU_APAActive2 "仅用于APA2.0功能
0x1= Activate用于软按键和语音激活；
0x2= Deactivate用于软按键和语音关闭；发送0x1/0x2的逻辑由HU判断，初始化和故障时发0x0=Invalid ";
CM_ SG_ 1287 HU_AutoBrakeEnable "ACC 主控则ACC接收，LAS 主控则LAS接收 ";
CM_ SG_ 1287 HU_IACCEnable "513(周期)和514(事件)，当前多数项目使用514(事件)报文。 ";
CM_ SG_ 1287 HU_LockCtrlEnable " ";
CM_ SG_ 1287 HU_AudioWarningEnable " ";
CM_ SG_ 1287 HU_LDWShakeLev "513(周期)和514(事件)，当前多数项目使用514(事件)报文。 ";
CM_ SG_ 1287 HU_SEAEnable "513(周期)和514(事件)，当前多数项目使用514(事件)报文。 ";
CM_ SG_ 1287 HU_RCTAEnable "513(周期)和514(事件)，当前多数项目使用514(事件)报文。 ";
CM_ SG_ 1287 HU_RCWEnable "513(周期)和514(事件)，当前多数项目使用514(事件)报文。 ";
CM_ SG_ 1287 HU_HMAEnable "513(周期)和514(事件)，当前多数项目使用514(事件)报文。 ";
CM_ SG_ 1287 HU_TSRSwitch "513(周期)和514(事件)，当前多数项目使用514(事件)报文。 ";
CM_ SG_ 1287 HU_LASWarningModeSelection "513(周期)和514(事件)，当前多数项目使用514(事件)报文。 ";
CM_ SG_ 1287 HU_LASModeSelection "513(周期)和514(事件)，当前多数项目使用514(事件)报文。 ";
CM_ SG_ 1287 HU_ObstacleSafeDistanceSet "513(周期)和514(事件)，当前多数项目使用514(事件)报文。 ";
CM_ SG_ 1287 HU_ParkingConfirm "513(周期)和514(事件)，当前多数项目使用514(事件)报文。 ";
CM_ SG_ 1287 HU_RemoteDistanceSet "513(周期)和514(事件)，当前多数项目使用514(事件)报文。 ";
CM_ SG_ 1287 HU_ParkingResume "513(周期)和514(事件)，当前多数项目使用514(事件)报文。 ";
CM_ SG_ 1287 HU_Uls_FKP_Activation "513(周期)和514(事件)，当前多数项目使用514(事件)报文。 ";
CM_ SG_ 1287 HU_Uls_BSD_Activation "预留 ";
CM_ SG_ 1287 HU_OverspeedWarningOffset "513(周期)和514(事件)，当前多数项目使用514(事件)报文。 ";
CM_ SG_ 1287 HU_OverspeedWarningEnable "513(周期)和514(事件)，当前多数项目使用514(事件)报文。 ";
CM_ SG_ 1287 HU_OverspeedSoundWarEnable "513(周期)和514(事件)，当前多数项目使用514(事件)报文。 ";
CM_ SG_ 1287 HU_FatigueDectionEnable "513(周期)和514(事件)，当前多数项目使用514(事件)报文。 ";
CM_ SG_ 1287 HU_DVRBrowseCommand "513(周期)和514(事件)，当前多数项目使用514(事件)报文。 ";
CM_ SG_ 1287 HU_NDAAudioWarEnable "ACC 主控则ACC接收，LAS 主控则LAS接收 ";
CM_ SG_ 1287 HU_NDASetSpdMode " ";
CM_ BO_ 1302 " ";
CM_ SG_ 1302 HU_AirHumidityValid "预留信号，由动力院输入项目是否搭载 ";
CM_ SG_ 1302 HU_AirHumidity "预留信号，由动力院输入项目是否搭载 ";
CM_ BO_ 1328 " ";
CM_ SG_ 1328 IP_FuelLevel "GW报文转发 ";
CM_ SG_ 1328 IP_TotalOdometer "GW报文转发 ";
CM_ SG_ 1328 IP_EngineOffTime "This signal identifies the amount of time from IGN Off to the next Ignition cycle.  This signal is required for the Thermal Estimation algorithms to work properly.
GW报文转发 ";
CM_ BO_ 391 "源端CHS_EPBi/IBCU_17A,0 ";
CM_ SG_ 391 IBCU_BrakeFluid_Warning " ";
CM_ SG_ 391 ESP_VehicleSpeed "TCU接收为DCT专用
ACM接收为AT/DCT专用 ";
CM_ SG_ 391 ESP_VehicleSpeedValid "TCU接收为DCT专用 ";
CM_ SG_ 391 ESP_TorqIncwhlFront " ";
CM_ SG_ 391 ESP_RollingCounter_187 "AT/DCT ";
CM_ SG_ 391 ESP_ESPActiveStatus "TCU接收为DCT专用 ";
CM_ SG_ 391 ESP_EngTorqIncFrontActive "ACC 主控则ACC接收，LAS 主控则LAS接收 ";
CM_ SG_ 391 ESP_EngTorqDecActive "ACC 主控则ACC接收，LAS 主控则LAS接收 ";
CM_ SG_ 391 ESP_EBDFailStatus "TCU接收为DCT专用 ";
CM_ SG_ 391 ESP_CRCCheck_187 "AT/DCT ";
CM_ SG_ 391 ESP_ADBF_Active "Assist Dynamic Brake Failure ";
CM_ BO_ 407 "源端CHS_IBCU/EPBi_17A,1 ";
CM_ SG_ 407 ESP_CRCCheck_197 " ";
CM_ BO_ 404 "源端HybridA_EMS/PDCU_17C,1 ";
CM_ SG_ 404 EMS_EngSts "APA配置接收方无BDC ";
CM_ SG_ 404 EMS_EngFuCutOff "ACC 主控则ACC接收，LAS 主控则LAS接收 ";
BA_DEF_ SG_  "GenSigStartValue" INT 0 0;
BA_DEF_ SG_  "GenSigInvalidValue" STRING ;
BA_DEF_ SG_  "GenSigCycleTime" INT 0 0;
BA_DEF_ SG_  "GenSigSendType" ENUM  "Cyclic","OnWrite","OnWriteWithRepetition","OnChange","OnChangeWithRepetition","IfActive","IfActiveWithRepetition","NoSigSendType","NotUsed","NotUsed","NotUsed","NotUsed","NotUsed";
BA_DEF_  "Baudrate" INT 0 1000000;
BA_DEF_  "BusType" STRING ;
BA_DEF_  "NmType" STRING ;
BA_DEF_  "Manufacturer" STRING ;
BA_DEF_  "VersionYear" INT 2009 2210;
BA_DEF_  "VersionNumber" INT 0 65535;
BA_DEF_  "VersionMonth" INT 0 18;
BA_DEF_  "VersionDay" INT 0 49;
BA_DEF_ BU_  "NodeLayerModules" STRING ;
BA_DEF_ BU_  "ILUsed" ENUM  "No","Yes";
BA_DEF_  "GenNWMTalkNM" STRING ;
BA_DEF_  "GenNWMGotoMode_BusSleep" STRING ;
BA_DEF_  "GenNWMGotoMode_Awake" STRING ;
BA_DEF_  "GenNWMApCanWakeUp" STRING ;
BA_DEF_  "GenNWMApCanSleep" STRING ;
BA_DEF_  "GenNWMApCanOn" STRING ;
BA_DEF_  "GenNWMApCanOff" STRING ;
BA_DEF_  "GenNWMApCanNormal" STRING ;
BA_DEF_  "GenNWMApBusSleep" STRING ;
BA_DEF_ BO_  "GenMsgSendType" ENUM  "Cyclic","Event","NotUsed","NotUsed","NotUsed","Cyclic","NotUsed","IfActive","NoMsgSendType","NotUsed";
BA_DEF_ BO_  "GenMsgILSupport" ENUM  "No","Yes";
BA_DEF_ BO_  "GenMsgCycleTime" INT 0 65535;
BA_DEF_ BO_  "CANFD_BRS" ENUM  "0","1";
BA_DEF_ BO_  "VFrameFormat" ENUM  "StandardCAN","ExtendedCAN","reserved","reserved","reserved","reserved","reserved","reserved","reserved","reserved","reserved","reserved","reserved","reserved","StandardCAN_FD","ExtendedCAN_FD";
BA_DEF_DEF_  "GenSigStartValue" 0;
BA_DEF_DEF_  "GenSigInvalidValue" "/";
BA_DEF_DEF_  "GenSigCycleTime" 0;
BA_DEF_DEF_  "GenSigSendType" "Cyclic";
BA_DEF_DEF_  "Baudrate" 500000;
BA_DEF_DEF_  "BusType" "";
BA_DEF_DEF_  "NmType" "";
BA_DEF_DEF_  "Manufacturer" "CHANA";
BA_DEF_DEF_  "VersionYear" 2010;
BA_DEF_DEF_  "VersionNumber" 0;
BA_DEF_DEF_  "VersionMonth" 11;
BA_DEF_DEF_  "VersionDay" 0;
BA_DEF_DEF_  "NodeLayerModules" "CANoeILNLVector.dll";
BA_DEF_DEF_  "ILUsed" "Yes";
BA_DEF_DEF_  "GenNWMTalkNM" "TalkNM()";
BA_DEF_DEF_  "GenNWMGotoMode_BusSleep" "GotoMode_BusSleep()";
BA_DEF_DEF_  "GenNWMGotoMode_Awake" "GotoMode_Awake()";
BA_DEF_DEF_  "GenNWMApCanWakeUp" "apCanWakeUp()";
BA_DEF_DEF_  "GenNWMApCanSleep" "apCanSleep()";
BA_DEF_DEF_  "GenNWMApCanOn" "apCanOn()";
BA_DEF_DEF_  "GenNWMApCanOff" "apCanOff()";
BA_DEF_DEF_  "GenNWMApCanNormal" "apCanNormal()";
BA_DEF_DEF_  "GenNWMApBusSleep" "apBusSleep()";
BA_DEF_DEF_  "GenMsgSendType" "NoMsgSendType";
BA_DEF_DEF_  "GenMsgILSupport" "Yes";
BA_DEF_DEF_  "GenMsgCycleTime" 0;
BA_DEF_DEF_  "CANFD_BRS" "1";
BA_DEF_DEF_  "VFrameFormat" "StandardCAN";
BA_ "BusType" "CAN FD";
BA_ "NmType" "OSEK";
BA_ "Baudrate" 2000000;
BA_ "VersionDay" 24;
BA_ "VersionMonth" 1;
BA_ "VersionNumber" 11;
BA_ "VersionYear" 2024;
BA_ "GenMsgSendType" BO_ 898 0;
BA_ "GenMsgCycleTime" BO_ 898 100;
BA_ "VFrameFormat" BO_ 898 14;
BA_ "GenMsgSendType" BO_ 676 0;
BA_ "GenMsgCycleTime" BO_ 676 50;
BA_ "VFrameFormat" BO_ 676 14;
BA_ "GenMsgSendType" BO_ 1893 1;
BA_ "VFrameFormat" BO_ 1893 14;
BA_ "GenMsgSendType" BO_ 1901 1;
BA_ "VFrameFormat" BO_ 1901 14;
BA_ "GenMsgSendType" BO_ 1937 1;
BA_ "VFrameFormat" BO_ 1937 14;
BA_ "GenMsgSendType" BO_ 1945 1;
BA_ "VFrameFormat" BO_ 1945 14;
BA_ "GenMsgSendType" BO_ 1874 1;
BA_ "VFrameFormat" BO_ 1874 14;
BA_ "GenMsgSendType" BO_ 1882 1;
BA_ "VFrameFormat" BO_ 1882 14;
BA_ "GenMsgSendType" BO_ 1891 1;
BA_ "VFrameFormat" BO_ 1891 14;
BA_ "GenMsgSendType" BO_ 1899 1;
BA_ "VFrameFormat" BO_ 1899 14;
BA_ "GenMsgSendType" BO_ 1426 0;
BA_ "GenMsgCycleTime" BO_ 1426 1000;
BA_ "VFrameFormat" BO_ 1426 14;
BA_ "GenMsgSendType" BO_ 1428 0;
BA_ "GenMsgCycleTime" BO_ 1428 1000;
BA_ "VFrameFormat" BO_ 1428 14;
BA_ "GenMsgSendType" BO_ 80 0;
BA_ "GenMsgCycleTime" BO_ 80 500;
BA_ "VFrameFormat" BO_ 80 14;
BA_ "GenMsgSendType" BO_ 368 0;
BA_ "GenMsgCycleTime" BO_ 368 10;
BA_ "VFrameFormat" BO_ 368 14;
BA_ "GenMsgSendType" BO_ 384 0;
BA_ "GenMsgCycleTime" BO_ 384 10;
BA_ "VFrameFormat" BO_ 384 14;
BA_ "GenMsgSendType" BO_ 580 0;
BA_ "GenMsgCycleTime" BO_ 580 20;
BA_ "VFrameFormat" BO_ 580 14;
BA_ "GenMsgSendType" BO_ 632 0;
BA_ "GenMsgCycleTime" BO_ 632 20;
BA_ "VFrameFormat" BO_ 632 14;
BA_ "GenMsgSendType" BO_ 664 0;
BA_ "GenMsgCycleTime" BO_ 664 40;
BA_ "VFrameFormat" BO_ 664 14;
BA_ "GenMsgSendType" BO_ 775 0;
BA_ "GenMsgCycleTime" BO_ 775 100;
BA_ "VFrameFormat" BO_ 775 14;
BA_ "GenMsgSendType" BO_ 786 0;
BA_ "GenMsgCycleTime" BO_ 786 100;
BA_ "VFrameFormat" BO_ 786 14;
BA_ "GenMsgSendType" BO_ 832 0;
BA_ "GenMsgCycleTime" BO_ 832 100;
BA_ "VFrameFormat" BO_ 832 14;
BA_ "GenMsgSendType" BO_ 839 0;
BA_ "GenMsgCycleTime" BO_ 839 500;
BA_ "VFrameFormat" BO_ 839 14;
BA_ "GenMsgSendType" BO_ 869 0;
BA_ "GenMsgCycleTime" BO_ 869 100;
BA_ "VFrameFormat" BO_ 869 14;
BA_ "GenMsgSendType" BO_ 870 0;
BA_ "GenMsgCycleTime" BO_ 870 100;
BA_ "VFrameFormat" BO_ 870 14;
BA_ "GenMsgSendType" BO_ 903 0;
BA_ "GenMsgCycleTime" BO_ 903 100;
BA_ "VFrameFormat" BO_ 903 14;
BA_ "GenMsgSendType" BO_ 912 0;
BA_ "GenMsgCycleTime" BO_ 912 500;
BA_ "VFrameFormat" BO_ 912 14;
BA_ "GenMsgSendType" BO_ 918 0;
BA_ "GenMsgCycleTime" BO_ 918 100;
BA_ "VFrameFormat" BO_ 918 14;
BA_ "GenMsgSendType" BO_ 1287 1;
BA_ "VFrameFormat" BO_ 1287 14;
BA_ "GenMsgSendType" BO_ 1302 0;
BA_ "GenMsgCycleTime" BO_ 1302 1000;
BA_ "VFrameFormat" BO_ 1302 14;
BA_ "GenMsgSendType" BO_ 1328 0;
BA_ "GenMsgCycleTime" BO_ 1328 500;
BA_ "VFrameFormat" BO_ 1328 14;
BA_ "GenMsgSendType" BO_ 391 0;
BA_ "GenMsgCycleTime" BO_ 391 10;
BA_ "VFrameFormat" BO_ 391 14;
BA_ "GenMsgSendType" BO_ 407 0;
BA_ "GenMsgCycleTime" BO_ 407 10;
BA_ "VFrameFormat" BO_ 407 14;
BA_ "GenMsgSendType" BO_ 404 0;
BA_ "GenMsgCycleTime" BO_ 404 10;
BA_ "VFrameFormat" BO_ 404 14;
BA_ "GenSigInvalidValue" SG_ 898 ACC_TarVehLngRange "4095";
BA_ "GenSigStartValue" SG_ 898 ACC_TarVehLngRange 1500;
BA_ "GenSigCycleTime" SG_ 898 ACC_TarVehLngRange 100;
BA_ "GenSigCycleTime" SG_ 898 ACC_Target5ZoneID 100;
BA_ "GenSigStartValue" SG_ 898 ACC_Target5HeadingAngle 314;
BA_ "GenSigCycleTime" SG_ 898 ACC_Target5HeadingAngle 100;
BA_ "GenSigStartValue" SG_ 898 ACC_Target5Direction 5;
BA_ "GenSigCycleTime" SG_ 898 ACC_Target5Direction 100;
BA_ "GenSigInvalidValue" SG_ 898 ACC_Target5LatRange "1023";
BA_ "GenSigStartValue" SG_ 898 ACC_Target5LatRange 500;
BA_ "GenSigCycleTime" SG_ 898 ACC_Target5LatRange 100;
BA_ "GenSigInvalidValue" SG_ 898 ACC_Target5LngRange "4095";
BA_ "GenSigStartValue" SG_ 898 ACC_Target5LngRange 1500;
BA_ "GenSigCycleTime" SG_ 898 ACC_Target5LngRange 100;
BA_ "GenSigCycleTime" SG_ 898 ACC_Target5Type 100;
BA_ "GenSigCycleTime" SG_ 898 ACC_Target5ID 100;
BA_ "GenSigCycleTime" SG_ 898 ACC_Target5Detection 100;
BA_ "GenSigCycleTime" SG_ 898 ACC_Target4ZoneID 100;
BA_ "GenSigStartValue" SG_ 898 ACC_Target4HeadingAngle 314;
BA_ "GenSigCycleTime" SG_ 898 ACC_Target4HeadingAngle 100;
BA_ "GenSigStartValue" SG_ 898 ACC_Target4Direction 5;
BA_ "GenSigCycleTime" SG_ 898 ACC_Target4Direction 100;
BA_ "GenSigInvalidValue" SG_ 898 ACC_Target4LatRange "1023";
BA_ "GenSigStartValue" SG_ 898 ACC_Target4LatRange 500;
BA_ "GenSigCycleTime" SG_ 898 ACC_Target4LatRange 100;
BA_ "GenSigInvalidValue" SG_ 898 ACC_Target4LngRange "4095";
BA_ "GenSigStartValue" SG_ 898 ACC_Target4LngRange 1500;
BA_ "GenSigCycleTime" SG_ 898 ACC_Target4LngRange 100;
BA_ "GenSigCycleTime" SG_ 898 ACC_Target4Type 100;
BA_ "GenSigCycleTime" SG_ 898 ACC_Target4ID 100;
BA_ "GenSigCycleTime" SG_ 898 ACC_Target4Detection 100;
BA_ "GenSigCycleTime" SG_ 898 ACC_Target3ZoneID 100;
BA_ "GenSigStartValue" SG_ 898 ACC_Target3HeadingAngle 314;
BA_ "GenSigCycleTime" SG_ 898 ACC_Target3HeadingAngle 100;
BA_ "GenSigStartValue" SG_ 898 ACC_Target3Direction 5;
BA_ "GenSigCycleTime" SG_ 898 ACC_Target3Direction 100;
BA_ "GenSigInvalidValue" SG_ 898 ACC_Target3LatRange "1023";
BA_ "GenSigStartValue" SG_ 898 ACC_Target3LatRange 500;
BA_ "GenSigCycleTime" SG_ 898 ACC_Target3LatRange 100;
BA_ "GenSigInvalidValue" SG_ 898 ACC_Target3LngRange "4095";
BA_ "GenSigStartValue" SG_ 898 ACC_Target3LngRange 1500;
BA_ "GenSigCycleTime" SG_ 898 ACC_Target3LngRange 100;
BA_ "GenSigCycleTime" SG_ 898 ACC_Target3Type 100;
BA_ "GenSigCycleTime" SG_ 898 ACC_Target3ID 100;
BA_ "GenSigCycleTime" SG_ 898 ACC_Target3Detection 100;
BA_ "GenSigCycleTime" SG_ 898 ACC_Target2ZoneID 100;
BA_ "GenSigStartValue" SG_ 898 ACC_Target2HeadingAngle 314;
BA_ "GenSigCycleTime" SG_ 898 ACC_Target2HeadingAngle 100;
BA_ "GenSigStartValue" SG_ 898 ACC_Target2Direction 5;
BA_ "GenSigCycleTime" SG_ 898 ACC_Target2Direction 100;
BA_ "GenSigInvalidValue" SG_ 898 ACC_Target2LatRange "1023";
BA_ "GenSigStartValue" SG_ 898 ACC_Target2LatRange 500;
BA_ "GenSigCycleTime" SG_ 898 ACC_Target2LatRange 100;
BA_ "GenSigInvalidValue" SG_ 898 ACC_Target2LngRange "4095";
BA_ "GenSigStartValue" SG_ 898 ACC_Target2LngRange 1500;
BA_ "GenSigCycleTime" SG_ 898 ACC_Target2LngRange 100;
BA_ "GenSigCycleTime" SG_ 898 ACC_Target2Type 100;
BA_ "GenSigCycleTime" SG_ 898 ACC_Target2ID 100;
BA_ "GenSigCycleTime" SG_ 898 ACC_Target2Detection 100;
BA_ "GenSigCycleTime" SG_ 898 ACC_Target1ZoneID 100;
BA_ "GenSigStartValue" SG_ 898 ACC_Target1HeadingAngle 314;
BA_ "GenSigCycleTime" SG_ 898 ACC_Target1HeadingAngle 100;
BA_ "GenSigStartValue" SG_ 898 ACC_Target1Direction 5;
BA_ "GenSigCycleTime" SG_ 898 ACC_Target1Direction 100;
BA_ "GenSigInvalidValue" SG_ 898 ACC_Target1LatRange "1023";
BA_ "GenSigStartValue" SG_ 898 ACC_Target1LatRange 500;
BA_ "GenSigCycleTime" SG_ 898 ACC_Target1LatRange 100;
BA_ "GenSigInvalidValue" SG_ 898 ACC_Target1LngRange "4095";
BA_ "GenSigStartValue" SG_ 898 ACC_Target1LngRange 1500;
BA_ "GenSigCycleTime" SG_ 898 ACC_Target1LngRange 100;
BA_ "GenSigCycleTime" SG_ 898 ACC_Target1Type 100;
BA_ "GenSigCycleTime" SG_ 898 ACC_Target1ID 100;
BA_ "GenSigCycleTime" SG_ 898 ACC_Target1Detection 100;
BA_ "GenSigCycleTime" SG_ 898 ACC_RollingCounter_3E6 100;
BA_ "GenSigCycleTime" SG_ 898 ACC_CRCCheck_3E6 100;
BA_ "GenSigCycleTime" SG_ 898 ACC_CRCCheck_35C 100;
BA_ "GenSigCycleTime" SG_ 898 ACC_RollingCounter_35C 100;
BA_ "GenSigCycleTime" SG_ 898 ACC_CRCCheck_35D 100;
BA_ "GenSigCycleTime" SG_ 898 ACC_RollingCounter_35D 100;
BA_ "GenSigCycleTime" SG_ 898 ACC_LaneEquationStatus 100;
BA_ "GenSigStartValue" SG_ 898 ACC_LaneEquationC3 2047;
BA_ "GenSigCycleTime" SG_ 898 ACC_LaneEquationC3 100;
BA_ "GenSigStartValue" SG_ 898 ACC_LaneEquationC2 2047;
BA_ "GenSigCycleTime" SG_ 898 ACC_LaneEquationC2 100;
BA_ "GenSigStartValue" SG_ 898 ACC_LaneEquationC1 2047;
BA_ "GenSigCycleTime" SG_ 898 ACC_LaneEquationC1 100;
BA_ "GenSigCycleTime" SG_ 898 ACC_LaneQuality 100;
BA_ "GenSigCycleTime" SG_ 676 LCDAR_Left_RCTAAlert 50;
BA_ "GenSigCycleTime" SG_ 676 LCDAR_RCTAAlert 50;
BA_ "GenSigCycleTime" SG_ 676 LCDAR_BSD_LCASoundWar 50;
BA_ "GenSigInvalidValue" SG_ 676 LCDAR_RCTBStatus "3";
BA_ "GenSigCycleTime" SG_ 676 LCDAR_RCTBStatus 50;
BA_ "GenSigCycleTime" SG_ 676 LCDAR_CRCCheck_2AF 50;
BA_ "GenSigCycleTime" SG_ 676 LCDAR_RollingCounter_2AF 50;
BA_ "GenSigCycleTime" SG_ 676 LCDAR_ELK_oAlert 50;
BA_ "GenSigInvalidValue" SG_ 676 LCDAR_ELK_oStatus "3";
BA_ "GenSigCycleTime" SG_ 676 LCDAR_ELK_oStatus 50;
BA_ "GenSigCycleTime" SG_ 676 LCDAR_Left_ELK_oAlert 50;
BA_ "GenSigInvalidValue" SG_ 676 LCDAR_RCTBActive "0";
BA_ "GenSigCycleTime" SG_ 676 LCDAR_RCTBActive 50;
BA_ "GenSigStartValue" SG_ 676 LCDAR_RCTBTargetDecel 32000;
BA_ "GenSigCycleTime" SG_ 676 LCDAR_RCTBTargetDecel 50;
BA_ "GenSigInvalidValue" SG_ 676 LCDAR_RCTBEnable "0";
BA_ "GenSigStartValue" SG_ 676 LCDAR_RCTBEnable 1;
BA_ "GenSigCycleTime" SG_ 676 LCDAR_RCTBEnable 50;
BA_ "GenSigInvalidValue" SG_ 676 LCDAR_SystemStatus "7";
BA_ "GenSigStartValue" SG_ 676 LCDAR_SystemStatus 1;
BA_ "GenSigCycleTime" SG_ 676 LCDAR_SystemStatus 50;
BA_ "GenSigSendType" SG_ 1893 Diagnose_message765 1;
BA_ "GenSigSendType" SG_ 1901 Diagnose_message76D 1;
BA_ "GenSigSendType" SG_ 1937 Diagnose_message791 1;
BA_ "GenSigSendType" SG_ 1945 Diagnose_message799 1;
BA_ "GenSigSendType" SG_ 1874 Diagnose_message752 1;
BA_ "GenSigSendType" SG_ 1882 Diagnose_message75A 1;
BA_ "GenSigSendType" SG_ 1891 Diagnose_message763 1;
BA_ "GenSigSendType" SG_ 1899 Diagnose_message76B 1;
BA_ "GenSigCycleTime" SG_ 1426 LAS_NotSleep_BYTE7BIT1 1000;
BA_ "GenSigCycleTime" SG_ 1426 LAS_NotSleep_BYTE7BIT0 1000;
BA_ "GenSigCycleTime" SG_ 1426 LAS_WakeUp_BYTE4BIT1 1000;
BA_ "GenSigCycleTime" SG_ 1426 LAS_WakeUp_BYTE4BIT0 1000;
BA_ "GenSigCycleTime" SG_ 1428 FR_NotSleep_BYTE7BIT1 1000;
BA_ "GenSigCycleTime" SG_ 1428 FR_NotSleep_BYTE7BIT0 1000;
BA_ "GenSigCycleTime" SG_ 1428 FR_WakeUp_BYTE4BIT1 1000;
BA_ "GenSigCycleTime" SG_ 1428 FR_WakeUp_BYTE4BIT0 1000;
BA_ "GenSigCycleTime" SG_ 80 SRS_PassengerBuckleSwitchStatus 500;
BA_ "GenSigCycleTime" SG_ 80 SRS_RightRearBuckleSwitchSts 500;
BA_ "GenSigCycleTime" SG_ 80 SRS_MiddleRearBuckleSwitchSts 500;
BA_ "GenSigCycleTime" SG_ 80 SRS_LeftRearBuckleSwitchSts 500;
BA_ "GenSigCycleTime" SG_ 80 SRS_FrontPsgOccupancy 500;
BA_ "GenSigCycleTime" SG_ 80 SRS_PADIndication 500;
BA_ "GenSigCycleTime" SG_ 80 SRS_WarningLampStatus 500;
BA_ "GenSigCycleTime" SG_ 80 SRS_DriverBuckleSwitchStatus 500;
BA_ "GenSigCycleTime" SG_ 80 SRS_RollingCounter_id050 500;
BA_ "GenSigCycleTime" SG_ 80 SRS_CrashOutputStatusCheckSum 500;
BA_ "GenSigCycleTime" SG_ 80 SRS_CrashOutputStatus 500;
BA_ "GenSigCycleTime" SG_ 80 SRS_CRCCheck_50 500;
BA_ "GenSigCycleTime" SG_ 368 EPS_fault_state 10;
BA_ "GenSigInvalidValue" SG_ 368 EPS_ActualMotorTorq "4095";
BA_ "GenSigStartValue" SG_ 368 EPS_ActualMotorTorq 2048;
BA_ "GenSigCycleTime" SG_ 368 EPS_ActualMotorTorq 10;
BA_ "GenSigCycleTime" SG_ 368 EPS_CRCCheck_170 10;
BA_ "GenSigCycleTime" SG_ 368 EPS_RollingCounter_170 10;
BA_ "GenSigInvalidValue" SG_ 368 EPS_ActualTorsionBarTorq "2047";
BA_ "GenSigStartValue" SG_ 368 EPS_ActualTorsionBarTorq 1024;
BA_ "GenSigCycleTime" SG_ 368 EPS_ActualTorsionBarTorq 10;
BA_ "GenSigInvalidValue" SG_ 368 EPS_MinSafetyTorsionBarTorq "2047";
BA_ "GenSigStartValue" SG_ 368 EPS_MinSafetyTorsionBarTorq 1024;
BA_ "GenSigCycleTime" SG_ 368 EPS_MinSafetyTorsionBarTorq 10;
BA_ "GenSigInvalidValue" SG_ 368 EPS_MaxSafetyTorsionBarTorq "2047";
BA_ "GenSigStartValue" SG_ 368 EPS_MaxSafetyTorsionBarTorq 1024;
BA_ "GenSigCycleTime" SG_ 368 EPS_MaxSafetyTorsionBarTorq 10;
BA_ "GenSigCycleTime" SG_ 384 SAS_CRCCheck 10;
BA_ "GenSigCycleTime" SG_ 384 SAS_RollingCounter 10;
BA_ "GenSigInvalidValue" SG_ 384 SAS_SteeringAngleSpeed "255";
BA_ "GenSigCycleTime" SG_ 384 SAS_SteeringAngleSpeed 10;
BA_ "GenSigInvalidValue" SG_ 384 SAS_SteeringAngle "32767";
BA_ "GenSigCycleTime" SG_ 384 SAS_SteeringAngle 10;
BA_ "GenSigInvalidValue" SG_ 384 SAS_SASFailure "1";
BA_ "GenSigCycleTime" SG_ 384 SAS_SASFailure 10;
BA_ "GenSigCycleTime" SG_ 384 SAS_Calibrated 10;
BA_ "GenSigInvalidValue" SG_ 384 SAS_SteeringAngleValid "1";
BA_ "GenSigCycleTime" SG_ 384 SAS_SteeringAngleValid 10;
BA_ "GenSigCycleTime" SG_ 580 ADS_EOMTOReq 20;
BA_ "GenSigCycleTime" SG_ 580 ACC_HandsOnReq 20;
BA_ "GenSigCycleTime" SG_ 580 ACC_LatTakeoverReq 20;
BA_ "GenSigCycleTime" SG_ 580 ACC_LngTakeOverReq 20;
BA_ "GenSigStartValue" SG_ 580 ACC_LDWShakeLevStatus 2;
BA_ "GenSigCycleTime" SG_ 580 ACC_LDWShakeLevStatus 20;
BA_ "GenSigCycleTime" SG_ 580 ACC_TextInfoForDriver 20;
BA_ "GenSigCycleTime" SG_ 580 ADS__RollingCounter_244 20;
BA_ "GenSigCycleTime" SG_ 580 ADS_CRCCheck_244 20;
BA_ "GenSigCycleTime" SG_ 580 ACC_CRCCheck_25E 20;
BA_ "GenSigCycleTime" SG_ 580 ACC_RollingCounter_25E 20;
BA_ "GenSigCycleTime" SG_ 580 ACC_AEBCtrlType 20;
BA_ "GenSigCycleTime" SG_ 580 ACC_AccTrqReq 20;
BA_ "GenSigCycleTime" SG_ 580 ACC_AccTrqReqActive 20;
BA_ "GenSigCycleTime" SG_ 580 ACC_AEBVehilceHoldReq 20;
BA_ "GenSigCycleTime" SG_ 580 ACC_FCWPreWarning 20;
BA_ "GenSigCycleTime" SG_ 580 ACC_FCWLatentWarning 20;
BA_ "GenSigCycleTime" SG_ 580 ACC_FCWActive 20;
BA_ "GenSigCycleTime" SG_ 580 ACC_PrefillActive 20;
BA_ "GenSigCycleTime" SG_ 580 ACC_AWBActive 20;
BA_ "GenSigCycleTime" SG_ 580 ACC_AWBlevel 20;
BA_ "GenSigCycleTime" SG_ 580 ACC_ABAActive 20;
BA_ "GenSigStartValue" SG_ 580 ACC_ABAlevel 3;
BA_ "GenSigCycleTime" SG_ 580 ACC_ABAlevel 20;
BA_ "GenSigCycleTime" SG_ 580 ACC_AEBActive 20;
BA_ "GenSigStartValue" SG_ 580 ACC_AEBTargetDeceleration 32000;
BA_ "GenSigCycleTime" SG_ 580 ACC_AEBTargetDeceleration 20;
BA_ "GenSigCycleTime" SG_ 580 ACC_EmergencyDataRrdReq 20;
BA_ "GenSigCycleTime" SG_ 580 ACC_CRCCheck_24E 20;
BA_ "GenSigCycleTime" SG_ 580 ACC_RollingCounter_24E 20;
BA_ "GenSigCycleTime" SG_ 580 ACC_Driveoff_Request 20;
BA_ "GenSigInvalidValue" SG_ 580 ACC_ACCMode "7";
BA_ "GenSigCycleTime" SG_ 580 ACC_ACCMode 20;
BA_ "GenSigCycleTime" SG_ 580 ACC_CDDActive 20;
BA_ "GenSigCycleTime" SG_ 580 ACC_DecToStop 20;
BA_ "GenSigInvalidValue" SG_ 580 ACC_LKAStatus "3";
BA_ "GenSigCycleTime" SG_ 580 ACC_LKAStatus 20;
BA_ "GenSigCycleTime" SG_ 580 ACC_LDWVibrationWarningReq 20;
BA_ "GenSigInvalidValue" SG_ 580 ACC_LDWStatus "3";
BA_ "GenSigCycleTime" SG_ 580 ACC_LDWStatus 20;
BA_ "GenSigStartValue" SG_ 580 ACC_ACCTargetAcceleration 100;
BA_ "GenSigCycleTime" SG_ 580 ACC_ACCTargetAcceleration 20;
BA_ "GenSigCycleTime" SG_ 632 ESP_YawRateValid 20;
BA_ "GenSigInvalidValue" SG_ 632 ESP_YawRate "16383";
BA_ "GenSigCycleTime" SG_ 632 ESP_YawRate 20;
BA_ "GenSigCycleTime" SG_ 632 ESP_RollingCounter_278 20;
BA_ "GenSigInvalidValue" SG_ 632 ESP_LongAccel "1023";
BA_ "GenSigCycleTime" SG_ 632 ESP_LongAccel 20;
BA_ "GenSigInvalidValue" SG_ 632 ESP_LatAccel "255";
BA_ "GenSigCycleTime" SG_ 632 ESP_LatAccel 20;
BA_ "GenSigCycleTime" SG_ 632 ESP_CRCCheck_278 20;
BA_ "GenSigCycleTime" SG_ 664 BCM_TrunkUnlockReq 40;
BA_ "GenSigStartValue" SG_ 664 BCM_DriverDoorLockStatus 3;
BA_ "GenSigCycleTime" SG_ 664 BCM_DriverDoorLockStatus 40;
BA_ "GenSigCycleTime" SG_ 664 BCM_CRCCheck_298 40;
BA_ "GenSigCycleTime" SG_ 664 BCM_RollingCounter_298 40;
BA_ "GenSigCycleTime" SG_ 664 BCM_PassengerDoorLockStatus 40;
BA_ "GenSigCycleTime" SG_ 664 BCM_LeftRearDoorStatus 40;
BA_ "GenSigInvalidValue" SG_ 664 PEPS_SmartWelcomeLightStaus "0";
BA_ "GenSigCycleTime" SG_ 664 PEPS_SmartWelcomeLightStaus 40;
BA_ "GenSigInvalidValue" SG_ 664 PEPS_TrunkKeyStatus "0";
BA_ "GenSigCycleTime" SG_ 664 PEPS_TrunkKeyStatus 40;
BA_ "GenSigInvalidValue" SG_ 664 PEPS_UnLockKeyStatus "0";
BA_ "GenSigCycleTime" SG_ 664 PEPS_UnLockKeyStatus 40;
BA_ "GenSigInvalidValue" SG_ 664 PEPS_LockKeyStatus "0";
BA_ "GenSigCycleTime" SG_ 664 PEPS_LockKeyStatus 40;
BA_ "GenSigInvalidValue" SG_ 664 PEPS_SmartTrunkUlockRemind "0";
BA_ "GenSigCycleTime" SG_ 664 PEPS_SmartTrunkUlockRemind 40;
BA_ "GenSigInvalidValue" SG_ 664 PEPS_UnlockSignal "0";
BA_ "GenSigCycleTime" SG_ 664 PEPS_UnlockSignal 40;
BA_ "GenSigInvalidValue" SG_ 664 PEPS_LockSignal "0";
BA_ "GenSigCycleTime" SG_ 664 PEPS_LockSignal 40;
BA_ "GenSigInvalidValue" SG_ 664 PEPS_KeyNumber "7";
BA_ "GenSigCycleTime" SG_ 664 PEPS_KeyNumber 40;
BA_ "GenSigCycleTime" SG_ 664 PEPS_KeyAuthenticationStatus 40;
BA_ "GenSigInvalidValue" SG_ 664 PEPS_Easy_open "0";
BA_ "GenSigCycleTime" SG_ 664 PEPS_Easy_open 40;
BA_ "GenSigInvalidValue" SG_ 664 PEPS_Welcomelamp "0";
BA_ "GenSigCycleTime" SG_ 664 PEPS_Welcomelamp 40;
BA_ "GenSigCycleTime" SG_ 664 PEPS_TrunkRequestSignal 40;
BA_ "GenSigInvalidValue" SG_ 664 PEPS_KeyLearningSignal "3";
BA_ "GenSigCycleTime" SG_ 664 PEPS_KeyLearningSignal 40;
BA_ "GenSigInvalidValue" SG_ 664 PEPS_EasyOpenOrginalSignal "0";
BA_ "GenSigCycleTime" SG_ 664 PEPS_EasyOpenOrginalSignal 40;
BA_ "GenSigCycleTime" SG_ 664 PEPS_RemoteFailedAlarmSignal 40;
BA_ "GenSigCycleTime" SG_ 664 PEPS_SearchCarSignal 40;
BA_ "GenSigInvalidValue" SG_ 664 PEPS_LuggageUnlockSignal "0";
BA_ "GenSigCycleTime" SG_ 664 PEPS_LuggageUnlockSignal 40;
BA_ "GenSigInvalidValue" SG_ 775 ACC_AEBTargetSelected "7";
BA_ "GenSigCycleTime" SG_ 775 ACC_AEBTargetSelected 100;
BA_ "GenSigInvalidValue" SG_ 775 ACC_AEBFeatureConfig "15";
BA_ "GenSigCycleTime" SG_ 775 ACC_AEBFeatureConfig 100;
BA_ "GenSigStartValue" SG_ 775 ACC_ACCTargetLngRange 511;
BA_ "GenSigCycleTime" SG_ 775 ACC_ACCTargetLngRange 100;
BA_ "GenSigInvalidValue" SG_ 775 ACC_IACCSuspendReason "0";
BA_ "GenSigCycleTime" SG_ 775 ACC_IACCSuspendReason 100;
BA_ "GenSigStartValue" SG_ 775 ACC_RLaneDistanceFus 100;
BA_ "GenSigCycleTime" SG_ 775 ACC_RLaneDistanceFus 100;
BA_ "GenSigStartValue" SG_ 775 ACC_LLaneDistanceFus 20;
BA_ "GenSigCycleTime" SG_ 775 ACC_LLaneDistanceFus 100;
BA_ "GenSigStartValue" SG_ 775 ACC_RRLaneDis 240;
BA_ "GenSigCycleTime" SG_ 775 ACC_RRLaneDis 100;
BA_ "GenSigCycleTime" SG_ 775 ACC_LLLaneDis 100;
BA_ "GenSigCycleTime" SG_ 775 ACC_Target7ZoneID 100;
BA_ "GenSigStartValue" SG_ 775 ACC_Target7HeadingAngle 314;
BA_ "GenSigCycleTime" SG_ 775 ACC_Target7HeadingAngle 100;
BA_ "GenSigStartValue" SG_ 775 ACC_Target7Direction 5;
BA_ "GenSigCycleTime" SG_ 775 ACC_Target7Direction 100;
BA_ "GenSigInvalidValue" SG_ 775 ACC_Target7LatRange "1023";
BA_ "GenSigStartValue" SG_ 775 ACC_Target7LatRange 500;
BA_ "GenSigCycleTime" SG_ 775 ACC_Target7LatRange 100;
BA_ "GenSigInvalidValue" SG_ 775 ACC_Target7LngRange "4095";
BA_ "GenSigStartValue" SG_ 775 ACC_Target7LngRange 1500;
BA_ "GenSigCycleTime" SG_ 775 ACC_Target7LngRange 100;
BA_ "GenSigCycleTime" SG_ 775 ACC_Target7Type 100;
BA_ "GenSigCycleTime" SG_ 775 ACC_Target7ID 100;
BA_ "GenSigCycleTime" SG_ 775 ACC_Target7Detection 100;
BA_ "GenSigCycleTime" SG_ 775 ACC_Target6ZoneID 100;
BA_ "GenSigStartValue" SG_ 775 ACC_Target6HeadingAngle 314;
BA_ "GenSigCycleTime" SG_ 775 ACC_Target6HeadingAngle 100;
BA_ "GenSigStartValue" SG_ 775 ACC_Target6Direction 5;
BA_ "GenSigCycleTime" SG_ 775 ACC_Target6Direction 100;
BA_ "GenSigInvalidValue" SG_ 775 ACC_Target6LatRange "1023";
BA_ "GenSigStartValue" SG_ 775 ACC_Target6LatRange 500;
BA_ "GenSigCycleTime" SG_ 775 ACC_Target6LatRange 100;
BA_ "GenSigInvalidValue" SG_ 775 ACC_Target6LngRange "4095";
BA_ "GenSigStartValue" SG_ 775 ACC_Target6LngRange 1500;
BA_ "GenSigCycleTime" SG_ 775 ACC_Target6LngRange 100;
BA_ "GenSigCycleTime" SG_ 775 ACC_Target6Type 100;
BA_ "GenSigCycleTime" SG_ 775 ACC_Target6ID 100;
BA_ "GenSigCycleTime" SG_ 775 ACC_Target6Detection 100;
BA_ "GenSigStartValue" SG_ 775 ACC_AEBEnable 1;
BA_ "GenSigCycleTime" SG_ 775 ACC_AEBEnable 100;
BA_ "GenSigCycleTime" SG_ 775 ACC_VehicleStartRemindSts 100;
BA_ "GenSigCycleTime" SG_ 775 ACC_CRCCheck_35F 100;
BA_ "GenSigCycleTime" SG_ 775 ACC_RollingCounter_35F 100;
BA_ "GenSigInvalidValue" SG_ 775 ACC_CSLAEnableStatus "3";
BA_ "GenSigCycleTime" SG_ 775 ACC_CSLAEnableStatus 100;
BA_ "GenSigCycleTime" SG_ 775 ACC_CSLSetReq 100;
BA_ "GenSigCycleTime" SG_ 775 ACC_CRCCheck_344 100;
BA_ "GenSigCycleTime" SG_ 775 ACC_RollingCounter_344 100;
BA_ "GenSigCycleTime" SG_ 775 ACC_CRCCheck_322 100;
BA_ "GenSigCycleTime" SG_ 775 ACC_RollingCounter_322 100;
BA_ "GenSigStartValue" SG_ 775 ACC_ACCTargetRelSpd 250;
BA_ "GenSigCycleTime" SG_ 775 ACC_ACCTargetRelSpd 100;
BA_ "GenSigInvalidValue" SG_ 775 ACC_FRadarCalibrationStatus "3";
BA_ "GenSigCycleTime" SG_ 775 ACC_FRadarCalibrationStatus 100;
BA_ "GenSigCycleTime" SG_ 775 ACC_CRCCheck_35E 100;
BA_ "GenSigCycleTime" SG_ 775 ACC_RollingCounter_35E 100;
BA_ "GenSigStartValue" SG_ 775 ACC_FCWSettingStatus 1;
BA_ "GenSigCycleTime" SG_ 775 ACC_FCWSettingStatus 100;
BA_ "GenSigCycleTime" SG_ 775 ACC_ACCEPBrequest 100;
BA_ "GenSigCycleTime" SG_ 775 ACC_ObjValid 100;
BA_ "GenSigCycleTime" SG_ 775 ACC_TimeGapSet 100;
BA_ "GenSigCycleTime" SG_ 775 ACC_DistanceLevel 100;
BA_ "GenSigCycleTime" SG_ 775 ACC_SetSpeed 100;
BA_ "GenSigCycleTime" SG_ 786 ACC_AEBTargetFourWheelProb 100;
BA_ "GenSigCycleTime" SG_ 786 ACC_AEBTargetProb 100;
BA_ "GenSigCycleTime" SG_ 786 ACC_AEBTargetAx 100;
BA_ "GenSigCycleTime" SG_ 786 ACC_Selflearning_status 100;
BA_ "GenSigCycleTime" SG_ 786 ACC_Selflearning_angle 100;
BA_ "GenSigCycleTime" SG_ 786 ADS_NDAAudioWarEnableStatus 100;
BA_ "GenSigCycleTime" SG_ 786 ADS_ADSVoiceRequest 100;
BA_ "GenSigCycleTime" SG_ 786 ADS_EOMWarnning 100;
BA_ "GenSigCycleTime" SG_ 786 ADS_CRCCheck_3D7 100;
BA_ "GenSigCycleTime" SG_ 786 ADS_RollingCounter_3D7 100;
BA_ "GenSigCycleTime" SG_ 786 ACC_DriverWindowControl 100;
BA_ "GenSigStartValue" SG_ 786 ACC_AEBTargetDirection 5;
BA_ "GenSigCycleTime" SG_ 786 ACC_AEBTargetDirection 100;
BA_ "GenSigCycleTime" SG_ 786 ACC_AEBTargetDetection 100;
BA_ "GenSigStartValue" SG_ 786 ACC_AEBTargetType 15;
BA_ "GenSigCycleTime" SG_ 786 ACC_AEBTargetType 100;
BA_ "GenSigCycleTime" SG_ 786 ACC_CRCCheck_3E4 100;
BA_ "GenSigCycleTime" SG_ 786 ACC_RollingCounter_3E4 100;
BA_ "GenSigInvalidValue" SG_ 832 AC_EvaporatorTemp "255";
BA_ "GenSigStartValue" SG_ 832 AC_EvaporatorTemp 255;
BA_ "GenSigCycleTime" SG_ 832 AC_EvaporatorTemp 100;
BA_ "GenSigInvalidValue" SG_ 832 AC_PrAirMergePortOpeningRatioVD "1";
BA_ "GenSigCycleTime" SG_ 832 AC_PrAirMergePortOpeningRatioVD 100;
BA_ "GenSigStartValue" SG_ 832 AC_PrAirMergePortOpeningRatio 127;
BA_ "GenSigCycleTime" SG_ 832 AC_PrAirMergePortOpeningRatio 100;
BA_ "GenSigInvalidValue" SG_ 832 AC_DrAirMergePortOpeningRatioVD "1";
BA_ "GenSigCycleTime" SG_ 832 AC_DrAirMergePortOpeningRatioVD 100;
BA_ "GenSigStartValue" SG_ 832 AC_DrAirMergePortOpeningRatio 127;
BA_ "GenSigCycleTime" SG_ 832 AC_DrAirMergePortOpeningRatio 100;
BA_ "GenSigInvalidValue" SG_ 832 AC_RrAirMergePortOpeningRatioVD "1";
BA_ "GenSigCycleTime" SG_ 832 AC_RrAirMergePortOpeningRatioVD 100;
BA_ "GenSigStartValue" SG_ 832 AC_RrAirMergePortOpeningRatio 127;
BA_ "GenSigCycleTime" SG_ 832 AC_RrAirMergePortOpeningRatio 100;
BA_ "GenSigInvalidValue" SG_ 832 AC_ACOnOff "3";
BA_ "GenSigCycleTime" SG_ 832 AC_ACOnOff 100;
BA_ "GenSigInvalidValue" SG_ 832 AC_FrBlowType "7";
BA_ "GenSigCycleTime" SG_ 832 AC_FrBlowType 100;
BA_ "GenSigInvalidValue" SG_ 832 AC_RrReqWindLevelVD "1";
BA_ "GenSigCycleTime" SG_ 832 AC_RrReqWindLevelVD 100;
BA_ "GenSigInvalidValue" SG_ 832 AC_RrReqWindLevel "15";
BA_ "GenSigCycleTime" SG_ 832 AC_RrReqWindLevel 100;
BA_ "GenSigCycleTime" SG_ 839 BCM_CRCCheck_347 500;
BA_ "GenSigCycleTime" SG_ 839 BCM_RollingCounter_347 500;
BA_ "GenSigCycleTime" SG_ 839 TPMS_RRPressureWarning 500;
BA_ "GenSigCycleTime" SG_ 839 TPMS_LRPressureWarning 500;
BA_ "GenSigCycleTime" SG_ 839 TPMS_SystemFailureWarning 500;
BA_ "GenSigStartValue" SG_ 839 BCM_TirePresureSignalStatus 1;
BA_ "GenSigCycleTime" SG_ 839 BCM_TirePresureSignalStatus 500;
BA_ "GenSigInvalidValue" SG_ 839 TPMS_LFPressureWarning "0";
BA_ "GenSigCycleTime" SG_ 839 TPMS_LFPressureWarning 500;
BA_ "GenSigCycleTime" SG_ 839 TPMS_RFPressureWarning 500;
BA_ "GenSigInvalidValue" SG_ 839 TPMS_LRTyrePressure "255";
BA_ "GenSigCycleTime" SG_ 839 TPMS_LRTyrePressure 500;
BA_ "GenSigInvalidValue" SG_ 839 TPMS_RRTyrePressure "255";
BA_ "GenSigCycleTime" SG_ 839 TPMS_RRTyrePressure 500;
BA_ "GenSigInvalidValue" SG_ 839 TPMS_RFTyrePressure "255";
BA_ "GenSigCycleTime" SG_ 839 TPMS_RFTyrePressure 500;
BA_ "GenSigInvalidValue" SG_ 839 TPMS_LFTyrePressure "255";
BA_ "GenSigCycleTime" SG_ 839 TPMS_LFTyrePressure 500;
BA_ "GenSigInvalidValue" SG_ 839 TPMS_SignalStatus "1";
BA_ "GenSigStartValue" SG_ 839 TPMS_SignalStatus 1;
BA_ "GenSigCycleTime" SG_ 839 TPMS_SignalStatus 500;
BA_ "GenSigInvalidValue" SG_ 869 DMS_Zlocation_eye "2047";
BA_ "GenSigStartValue" SG_ 869 DMS_Zlocation_eye 2047;
BA_ "GenSigCycleTime" SG_ 869 DMS_Zlocation_eye 100;
BA_ "GenSigInvalidValue" SG_ 869 DMS_Ylocation_eye "2047";
BA_ "GenSigStartValue" SG_ 869 DMS_Ylocation_eye 2047;
BA_ "GenSigCycleTime" SG_ 869 DMS_Ylocation_eye 100;
BA_ "GenSigInvalidValue" SG_ 869 DMS_Xlocation_eye "2047";
BA_ "GenSigStartValue" SG_ 869 DMS_Xlocation_eye 2047;
BA_ "GenSigCycleTime" SG_ 869 DMS_Xlocation_eye 100;
BA_ "GenSigCycleTime" SG_ 869 IMS_JawOffsetValue 100;
BA_ "GenSigCycleTime" SG_ 869 IMS_BrowOffsetValue 100;
BA_ "GenSigCycleTime" SG_ 869 IMS_PhoneCallSts 100;
BA_ "GenSigInvalidValue" SG_ 869 IMS_DriverEyesFovArea "15";
BA_ "GenSigCycleTime" SG_ 869 IMS_DriverEyesFovArea 100;
BA_ "GenSigInvalidValue" SG_ 869 IMS_DriverEyeClosestatus "7";
BA_ "GenSigStartValue" SG_ 869 IMS_DriverEyeClosestatus 7;
BA_ "GenSigCycleTime" SG_ 869 IMS_DriverEyeClosestatus 100;
BA_ "GenSigInvalidValue" SG_ 869 IMS_DriverEyeConfidence "0";
BA_ "GenSigCycleTime" SG_ 869 IMS_DriverEyeConfidence 100;
BA_ "GenSigInvalidValue" SG_ 869 IMS_DriverEyeDetect "0";
BA_ "GenSigCycleTime" SG_ 869 IMS_DriverEyeDetect 100;
BA_ "GenSigCycleTime" SG_ 869 IMS_RollingCounter_3A7 100;
BA_ "GenSigCycleTime" SG_ 869 IMS_CRCCheck_3A7 100;
BA_ "GenSigInvalidValue" SG_ 869 IMS_DistractionWarning "0";
BA_ "GenSigCycleTime" SG_ 869 IMS_DistractionWarning 100;
BA_ "GenSigInvalidValue" SG_ 869 IMS_DistractionSetFb "0";
BA_ "GenSigCycleTime" SG_ 869 IMS_DistractionSetFb 100;
BA_ "GenSigInvalidValue" SG_ 869 IMS_DrowsinessSetFb "0";
BA_ "GenSigCycleTime" SG_ 869 IMS_DrowsinessSetFb 100;
BA_ "GenSigInvalidValue" SG_ 869 IMS_DrowsinessSensFb "0";
BA_ "GenSigStartValue" SG_ 869 IMS_DrowsinessSensFb 2;
BA_ "GenSigCycleTime" SG_ 869 IMS_DrowsinessSensFb 100;
BA_ "GenSigInvalidValue" SG_ 869 IMS_DrowsinessWarning "0";
BA_ "GenSigCycleTime" SG_ 869 IMS_DrowsinessWarning 100;
BA_ "GenSigInvalidValue" SG_ 869 IMS_IDUpdateRemind "0";
BA_ "GenSigCycleTime" SG_ 869 IMS_IDUpdateRemind 100;
BA_ "GenSigInvalidValue" SG_ 869 IMS_DriverID "0";
BA_ "GenSigCycleTime" SG_ 869 IMS_DriverID 100;
BA_ "GenSigCycleTime" SG_ 869 IMS_RollingCounter_360 100;
BA_ "GenSigCycleTime" SG_ 869 IMS_CRCCheck_360 100;
BA_ "GenSigInvalidValue" SG_ 869 IMS_HeadDetectSts_Yaw "255";
BA_ "GenSigStartValue" SG_ 869 IMS_HeadDetectSts_Yaw 255;
BA_ "GenSigCycleTime" SG_ 869 IMS_HeadDetectSts_Yaw 100;
BA_ "GenSigInvalidValue" SG_ 869 IMS_HeadDetectSts_Roll "255";
BA_ "GenSigStartValue" SG_ 869 IMS_HeadDetectSts_Roll 255;
BA_ "GenSigCycleTime" SG_ 869 IMS_HeadDetectSts_Roll 100;
BA_ "GenSigInvalidValue" SG_ 869 IMS_HeadDetectSts_Pitch "255";
BA_ "GenSigStartValue" SG_ 869 IMS_HeadDetectSts_Pitch 255;
BA_ "GenSigCycleTime" SG_ 869 IMS_HeadDetectSts_Pitch 100;
BA_ "GenSigCycleTime" SG_ 869 IMS_RollingCounter_356 100;
BA_ "GenSigCycleTime" SG_ 869 IMS_CRCCheck_356 100;
BA_ "GenSigInvalidValue" SG_ 869 IMS_IMSStatus "7";
BA_ "GenSigStartValue" SG_ 869 IMS_IMSStatus 1;
BA_ "GenSigCycleTime" SG_ 869 IMS_IMSStatus 100;
BA_ "GenSigInvalidValue" SG_ 869 IMS_EyeGazeStatus "255";
BA_ "GenSigStartValue" SG_ 869 IMS_EyeGazeStatus 255;
BA_ "GenSigCycleTime" SG_ 869 IMS_EyeGazeStatus 100;
BA_ "GenSigInvalidValue" SG_ 869 IMS_EyeDetectSatus "255";
BA_ "GenSigStartValue" SG_ 869 IMS_EyeDetectSatus 255;
BA_ "GenSigCycleTime" SG_ 869 IMS_EyeDetectSatus 100;
BA_ "GenSigInvalidValue" SG_ 869 IMS_DrowsinessStatus "7";
BA_ "GenSigCycleTime" SG_ 869 IMS_DrowsinessStatus 100;
BA_ "GenSigInvalidValue" SG_ 869 IMS_DriverHeadDetect "0";
BA_ "GenSigCycleTime" SG_ 869 IMS_DriverHeadDetect 100;
BA_ "GenSigInvalidValue" SG_ 869 IMS_DistractionStatus "3";
BA_ "GenSigCycleTime" SG_ 869 IMS_DistractionStatus 100;
BA_ "GenSigCycleTime" SG_ 870 AC_WorkSts 100;
BA_ "GenSigInvalidValue" SG_ 870 AC_PTCStatus "3";
BA_ "GenSigCycleTime" SG_ 870 AC_PTCStatus 100;
BA_ "GenSigInvalidValue" SG_ 870 AC_ACPre "4095";
BA_ "GenSigCycleTime" SG_ 870 AC_ACPre 100;
BA_ "GenSigInvalidValue" SG_ 870 AC_AC_ReqValid "1";
BA_ "GenSigCycleTime" SG_ 870 AC_AC_ReqValid 100;
BA_ "GenSigInvalidValue" SG_ 870 AC_FrReqWindLevel "15";
BA_ "GenSigCycleTime" SG_ 870 AC_FrReqWindLevel 100;
BA_ "GenSigInvalidValue" SG_ 870 AC_FrReqWindLevelVD "1";
BA_ "GenSigCycleTime" SG_ 870 AC_FrReqWindLevelVD 100;
BA_ "GenSigCycleTime" SG_ 870 AC_AC_Req 100;
BA_ "GenSigInvalidValue" SG_ 870 AC_EnvironmentalTemp "255";
BA_ "GenSigStartValue" SG_ 870 AC_EnvironmentalTemp 255;
BA_ "GenSigCycleTime" SG_ 870 AC_EnvironmentalTemp 100;
BA_ "GenSigInvalidValue" SG_ 870 AC_EnvironmentalTempVD "1";
BA_ "GenSigCycleTime" SG_ 870 AC_EnvironmentalTempVD 100;
BA_ "GenSigStartValue" SG_ 903 BCM_WelcomeLightModeFB 3;
BA_ "GenSigCycleTime" SG_ 903 BCM_WelcomeLightModeFB 100;
BA_ "GenSigCycleTime" SG_ 903 BCM_CRCCheck_387 100;
BA_ "GenSigCycleTime" SG_ 903 BCM_RollingCounter_387 100;
BA_ "GenSigInvalidValue" SG_ 903 BCM_RainfallLevel "15";
BA_ "GenSigStartValue" SG_ 903 BCM_RainfallLevel 14;
BA_ "GenSigCycleTime" SG_ 903 BCM_RainfallLevel 100;
BA_ "GenSigInvalidValue" SG_ 903 BCM_BLEKeyIndicator "0";
BA_ "GenSigCycleTime" SG_ 903 BCM_BLEKeyIndicator 100;
BA_ "GenSigInvalidValue" SG_ 903 BCM_SaveEnergySetStatus "0";
BA_ "GenSigCycleTime" SG_ 903 BCM_SaveEnergySetStatus 100;
BA_ "GenSigCycleTime" SG_ 903 BCM_RearWiperStatus 100;
BA_ "GenSigInvalidValue" SG_ 903 BCM_FrontWashStatus "3";
BA_ "GenSigCycleTime" SG_ 903 BCM_FrontWashStatus 100;
BA_ "GenSigInvalidValue" SG_ 903 BCM_FrontWiperStatus "3";
BA_ "GenSigCycleTime" SG_ 903 BCM_FrontWiperStatus 100;
BA_ "GenSigCycleTime" SG_ 903 BCM_SystemFailureFlag 100;
BA_ "GenSigCycleTime" SG_ 903 BCM_BuzzerWarningMode 100;
BA_ "GenSigCycleTime" SG_ 903 BCM_LightSensor 100;
BA_ "GenSigInvalidValue" SG_ 903 BCM_RLS_Light_switch_reason "255";
BA_ "GenSigStartValue" SG_ 903 BCM_RLS_Light_switch_reason 255;
BA_ "GenSigCycleTime" SG_ 903 BCM_RLS_Light_switch_reason 100;
BA_ "GenSigCycleTime" SG_ 903 BCM_Statusrainsensor 100;
BA_ "GenSigInvalidValue" SG_ 903 BCM_Statuslowbeam "0";
BA_ "GenSigCycleTime" SG_ 903 BCM_Statuslowbeam 100;
BA_ "GenSigInvalidValue" SG_ 903 BCM_DrivingModeMemoryStatus "0";
BA_ "GenSigCycleTime" SG_ 903 BCM_DrivingModeMemoryStatus 100;
BA_ "GenSigInvalidValue" SG_ 903 BCM_DriveModeSet "0";
BA_ "GenSigCycleTime" SG_ 903 BCM_DriveModeSet 100;
BA_ "GenSigInvalidValue" SG_ 903 BCM_ThemeChangeSet "0";
BA_ "GenSigCycleTime" SG_ 903 BCM_ThemeChangeSet 100;
BA_ "GenSigCycleTime" SG_ 903 BCM_EPSTorqueModeFeedback 100;
BA_ "GenSigCycleTime" SG_ 903 BCM_DriveModeFeedback 100;
BA_ "GenSigInvalidValue" SG_ 903 BCM_DriveModeStatus "15";
BA_ "GenSigCycleTime" SG_ 903 BCM_DriveModeStatus 100;
BA_ "GenSigInvalidValue" SG_ 912 BCM_SOH_LifePercent "255";
BA_ "GenSigStartValue" SG_ 912 BCM_SOH_LifePercent 255;
BA_ "GenSigCycleTime" SG_ 912 BCM_SOH_LifePercent 500;
BA_ "GenSigInvalidValue" SG_ 912 BCM_BSNLevel "7";
BA_ "GenSigCycleTime" SG_ 912 BCM_BSNLevel 500;
BA_ "GenSigCycleTime" SG_ 912 BCM_PMSLevel 500;
BA_ "GenSigCycleTime" SG_ 912 BCM_LowPowerWarning 500;
BA_ "GenSigCycleTime" SG_ 918 BCM_Sunroof_APActive 100;
BA_ "GenSigStartValue" SG_ 918 BCM_Sunroof_Intialized 1;
BA_ "GenSigCycleTime" SG_ 918 BCM_Sunroof_Intialized 100;
BA_ "GenSigInvalidValue" SG_ 918 BCM_AerationHintReq "0";
BA_ "GenSigCycleTime" SG_ 918 BCM_AerationHintReq 100;
BA_ "GenSigCycleTime" SG_ 918 PEPS_RemoteWindowUpSignal 100;
BA_ "GenSigInvalidValue" SG_ 918 BCM_RemoteWindowUpSetStaus "0";
BA_ "GenSigStartValue" SG_ 918 BCM_RemoteWindowUpSetStaus 1;
BA_ "GenSigCycleTime" SG_ 918 BCM_RemoteWindowUpSetStaus 100;
BA_ "GenSigInvalidValue" SG_ 918 BCM_RemoteWindowDownSetStaus "0";
BA_ "GenSigStartValue" SG_ 918 BCM_RemoteWindowDownSetStaus 1;
BA_ "GenSigCycleTime" SG_ 918 BCM_RemoteWindowDownSetStaus 100;
BA_ "GenSigCycleTime" SG_ 918 PEPS_RemoteWindowDownSignal 100;
BA_ "GenSigCycleTime" SG_ 918 BCM_RemoteWindowControl 100;
BA_ "GenSigInvalidValue" SG_ 918 BCM_AutoCloseWindow "0";
BA_ "GenSigCycleTime" SG_ 918 BCM_AutoCloseWindow 100;
BA_ "GenSigInvalidValue" SG_ 918 BCM_WinOpenWarn "0";
BA_ "GenSigCycleTime" SG_ 918 BCM_WinOpenWarn 100;
BA_ "GenSigInvalidValue" SG_ 918 BCM_WinDownCfgSts "3";
BA_ "GenSigCycleTime" SG_ 918 BCM_WinDownCfgSts 100;
BA_ "GenSigInvalidValue" SG_ 918 BCM_WinUpCfgSts "3";
BA_ "GenSigCycleTime" SG_ 918 BCM_WinUpCfgSts 100;
BA_ "GenSigInvalidValue" SG_ 918 BCM_LockAutoClsWinSetStatus "0";
BA_ "GenSigCycleTime" SG_ 918 BCM_LockAutoClsWinSetStatus 100;
BA_ "GenSigInvalidValue" SG_ 918 BCM_SunroofMotor "3";
BA_ "GenSigCycleTime" SG_ 918 BCM_SunroofMotor 100;
BA_ "GenSigInvalidValue" SG_ 918 BCM_SunroofRainSetStatus "0";
BA_ "GenSigCycleTime" SG_ 918 BCM_SunroofRainSetStatus 100;
BA_ "GenSigInvalidValue" SG_ 918 BCM_Sunshade_Movement "0";
BA_ "GenSigCycleTime" SG_ 918 BCM_Sunshade_Movement 100;
BA_ "GenSigInvalidValue" SG_ 918 BCM_Sunshade_POS_VIT_FL "127";
BA_ "GenSigStartValue" SG_ 918 BCM_Sunshade_POS_VIT_FL 127;
BA_ "GenSigCycleTime" SG_ 918 BCM_Sunshade_POS_VIT_FL 100;
BA_ "GenSigInvalidValue" SG_ 918 BCM_Sunroof_POS_Direction "0";
BA_ "GenSigCycleTime" SG_ 918 BCM_Sunroof_POS_Direction 100;
BA_ "GenSigInvalidValue" SG_ 918 BCM_Sunroof_Movement "0";
BA_ "GenSigCycleTime" SG_ 918 BCM_Sunroof_Movement 100;
BA_ "GenSigInvalidValue" SG_ 918 BCM_Sunroof_POS_VIT "127";
BA_ "GenSigCycleTime" SG_ 918 BCM_Sunroof_POS_VIT 100;
BA_ "GenSigCycleTime" SG_ 918 BCM_SunroofStatus 100;
BA_ "GenSigSendType" SG_ 1287 HU_NDANavEnable 1;
BA_ "GenSigSendType" SG_ 1287 HU_NDAEnable 1;
BA_ "GenSigSendType" SG_ 1287 HU_Tutorialmodel 1;
BA_ "GenSigSendType" SG_ 1287 HU_APAActive3 1;
BA_ "GenSigStartValue" SG_ 1287 HU_LaneChangeStyle 2;
BA_ "GenSigSendType" SG_ 1287 HU_LaneChangeStyle 1;
BA_ "GenSigSendType" SG_ 1287 HU_DoorOpenWarningSelect 1;
BA_ "GenSigSendType" SG_ 1287 HU_FullSpeedPanoramicSelect 1;
BA_ "GenSigSendType" SG_ 1287 HU_ParkVoiceIntSetStatus 1;
BA_ "GenSigSendType" SG_ 1287 HU_TJPEnable 1;
BA_ "GenSigSendType" SG_ 1287 HU_FCTAEnable 1;
BA_ "GenSigSendType" SG_ 1287 HU_FCTBEnable 1;
BA_ "GenSigSendType" SG_ 1287 HU_RCTBEnable 1;
BA_ "GenSigSendType" SG_ 1287 HU_SlotVoiceSelect 1;
BA_ "GenSigSendType" SG_ 1287 HU_ParkingModeSelect 1;
BA_ "GenSigSendType" SG_ 1287 HU_TopLookDownSwitch 1;
BA_ "GenSigSendType" SG_ 1287 HU_TransparentCarSwitch 1;
BA_ "GenSigSendType" SG_ 1287 HU_DVREmergencyRecord 1;
BA_ "GenSigSendType" SG_ 1287 HU_MODEnable 1;
BA_ "GenSigSendType" SG_ 1287 HU_AVMCalibrationSwitch 1;
BA_ "GenSigSendType" SG_ 1287 HU_DVRDistortCorrectSwitch 1;
BA_ "GenSigSendType" SG_ 1287 HU_DVRTapeSet 1;
BA_ "GenSigSendType" SG_ 1287 HU_ResolutionSet 1;
BA_ "GenSigSendType" SG_ 1287 HU_DVREnableSet 1;
BA_ "GenSigSendType" SG_ 1287 HU_DVRReplaySpeed 1;
BA_ "GenSigSendType" SG_ 1287 HU_DVRReplayMode 1;
BA_ "GenSigSendType" SG_ 1287 HU_ShootControl 1;
BA_ "GenSigSendType" SG_ 1287 HU_RecordingcycleSetting 1;
BA_ "GenSigSendType" SG_ 1287 HU_LanguageSet 1;
BA_ "GenSigSendType" SG_ 1287 HU_DVRVedioSeek 1;
BA_ "GenSigSendType" SG_ 1287 HU_DVRFormatReq 1;
BA_ "GenSigSendType" SG_ 1287 HU_DVRReplayCommand 1;
BA_ "GenSigStartValue" SG_ 1287 HU_DVRVideoPlayUserTime 511;
BA_ "GenSigSendType" SG_ 1287 HU_DVRVideoPlayUserTime 1;
BA_ "GenSigSendType" SG_ 1287 HU_TurnLightAVMSwitch 1;
BA_ "GenSigSendType" SG_ 1287 HU_RadarAVMSwitch 1;
BA_ "GenSigSendType" SG_ 1287 HU_VC_CruiseSetSpeed 1;
BA_ "GenSigSendType" SG_ 1287 HU_VC_CruiseSetDistance 1;
BA_ "GenSigSendType" SG_ 1287 HU_VC_CruiseControl 1;
BA_ "GenSigSendType" SG_ 1287 HU_BSDLCASetting 1;
BA_ "GenSigSendType" SG_ 1287 HU_FCWSetting 1;
BA_ "GenSigSendType" SG_ 1287 HU_FrontRadarActive 1;
BA_ "GenSigSendType" SG_ 1287 HU_APAActive2 1;
BA_ "GenSigSendType" SG_ 1287 HU_ACCObjEnable 1;
BA_ "GenSigSendType" SG_ 1287 HU_CruiseControlSet 1;
BA_ "GenSigSendType" SG_ 1287 HU_AutoBrakeEnable 1;
BA_ "GenSigSendType" SG_ 1287 HU_DVRPrintScreen 1;
BA_ "GenSigSendType" SG_ 1287 HU_AVMCalibrationConfirm 1;
BA_ "GenSigSendType" SG_ 1287 HU_IACCEnable 1;
BA_ "GenSigSendType" SG_ 1287 HU_LockCtrlEnable 1;
BA_ "GenSigSendType" SG_ 1287 HU_AudioWarningEnable 1;
BA_ "GenSigSendType" SG_ 1287 HU_LDWShakeLev 1;
BA_ "GenSigSendType" SG_ 1287 HU_SEAEnable 1;
BA_ "GenSigSendType" SG_ 1287 HU_RCTAEnable 1;
BA_ "GenSigSendType" SG_ 1287 HU_RCWEnable 1;
BA_ "GenSigSendType" SG_ 1287 HU_HMAEnable 1;
BA_ "GenSigSendType" SG_ 1287 HU_TSRSwitch 1;
BA_ "GenSigSendType" SG_ 1287 HU_LASWarningModeSelection 1;
BA_ "GenSigSendType" SG_ 1287 HU_LASModeSelection 1;
BA_ "GenSigSendType" SG_ 1287 HU_ObstacleSafeDistanceSet 1;
BA_ "GenSigSendType" SG_ 1287 HU_ParkingConfirm 1;
BA_ "GenSigSendType" SG_ 1287 HU_RemoteDistanceSet 1;
BA_ "GenSigSendType" SG_ 1287 HU_ParkingResume 1;
BA_ "GenSigSendType" SG_ 1287 HU_Uls_FKP_Activation 1;
BA_ "GenSigSendType" SG_ 1287 HU_Uls_BSD_Activation 1;
BA_ "GenSigSendType" SG_ 1287 HU_OverspeedWarningOffset 1;
BA_ "GenSigSendType" SG_ 1287 HU_OverspeedWarningEnable 1;
BA_ "GenSigSendType" SG_ 1287 HU_OverspeedSoundWarEnable 1;
BA_ "GenSigSendType" SG_ 1287 HU_FatigueDectionEnable 1;
BA_ "GenSigSendType" SG_ 1287 HU_DVRBrowseCommand 1;
BA_ "GenSigSendType" SG_ 1287 HU_NDAAudioWarEnable 1;
BA_ "GenSigSendType" SG_ 1287 HU_RampAVMSwitch 1;
BA_ "GenSigSendType" SG_ 1287 HU_NDASetSpdMode 1;
BA_ "GenSigSendType" SG_ 1287 HU_HZPOnOff 1;
BA_ "GenSigSendType" SG_ 1287 HU_HZPRecomendRes 1;
BA_ "GenSigInvalidValue" SG_ 1302 HU_AirHumidityValid "1";
BA_ "GenSigCycleTime" SG_ 1302 HU_AirHumidityValid 1000;
BA_ "GenSigInvalidValue" SG_ 1302 HU_AirHumidity "127";
BA_ "GenSigCycleTime" SG_ 1302 HU_AirHumidity 1000;
BA_ "GenSigInvalidValue" SG_ 1302 HU_LeaveMaintainMileage "1048575";
BA_ "GenSigCycleTime" SG_ 1302 HU_LeaveMaintainMileage 1000;
BA_ "GenSigInvalidValue" SG_ 1302 HU_LeaveMaintainDay "4095";
BA_ "GenSigCycleTime" SG_ 1302 HU_LeaveMaintainDay 1000;
BA_ "GenSigInvalidValue" SG_ 1302 HU_MaintainRemindReq "0";
BA_ "GenSigCycleTime" SG_ 1302 HU_MaintainRemindReq 1000;
BA_ "GenSigCycleTime" SG_ 1302 HU_LocalTimeSystem 1000;
BA_ "GenSigInvalidValue" SG_ 1302 HU_LocalTimeSecond "0";
BA_ "GenSigCycleTime" SG_ 1302 HU_LocalTimeSecond 1000;
BA_ "GenSigInvalidValue" SG_ 1302 HU_LocalTimeMinute "0";
BA_ "GenSigCycleTime" SG_ 1302 HU_LocalTimeMinute 1000;
BA_ "GenSigInvalidValue" SG_ 1302 HU_LocalTimeHour "0";
BA_ "GenSigCycleTime" SG_ 1302 HU_LocalTimeHour 1000;
BA_ "GenSigInvalidValue" SG_ 1302 HU_LocalTimeDate "1";
BA_ "GenSigStartValue" SG_ 1302 HU_LocalTimeDate 1;
BA_ "GenSigCycleTime" SG_ 1302 HU_LocalTimeDate 1000;
BA_ "GenSigInvalidValue" SG_ 1302 HU_LocalTimeYear "0";
BA_ "GenSigCycleTime" SG_ 1302 HU_LocalTimeYear 1000;
BA_ "GenSigInvalidValue" SG_ 1302 HU_LocalTimeMonth "1";
BA_ "GenSigStartValue" SG_ 1302 HU_LocalTimeMonth 1;
BA_ "GenSigCycleTime" SG_ 1302 HU_LocalTimeMonth 1000;
BA_ "GenSigInvalidValue" SG_ 1302 HU_LocalTimeValid "1";
BA_ "GenSigCycleTime" SG_ 1302 HU_LocalTimeValid 1000;
BA_ "GenSigInvalidValue" SG_ 1302 HU_CurrentLocationLatitude "268435455";
BA_ "GenSigCycleTime" SG_ 1302 HU_CurrentLocationLatitude 1000;
BA_ "GenSigInvalidValue" SG_ 1302 HU_CurrentLocationLongitude "536870911";
BA_ "GenSigCycleTime" SG_ 1302 HU_CurrentLocationLongitude 1000;
BA_ "GenSigInvalidValue" SG_ 1302 HU_CurrentLocationValid "1";
BA_ "GenSigCycleTime" SG_ 1302 HU_CurrentLocationValid 1000;
BA_ "GenSigCycleTime" SG_ 1302 HU_CurrentLocationstd 1000;
BA_ "GenSigInvalidValue" SG_ 1328 IP_FuelLevel "0";
BA_ "GenSigCycleTime" SG_ 1328 IP_FuelLevel 500;
BA_ "GenSigInvalidValue" SG_ 1328 IP_TotalOdometer "16777215";
BA_ "GenSigCycleTime" SG_ 1328 IP_TotalOdometer 500;
BA_ "GenSigInvalidValue" SG_ 1328 IP_EngineOffTime "65535";
BA_ "GenSigCycleTime" SG_ 1328 IP_EngineOffTime 500;
BA_ "GenSigInvalidValue" SG_ 391 IBCU_BrakeFluid_Warning "3";
BA_ "GenSigCycleTime" SG_ 391 IBCU_BrakeFluid_Warning 10;
BA_ "GenSigInvalidValue" SG_ 391 ESP_VehicleSpeed "8191";
BA_ "GenSigCycleTime" SG_ 391 ESP_VehicleSpeed 10;
BA_ "GenSigInvalidValue" SG_ 391 ESP_VehicleSpeedValid "1";
BA_ "GenSigCycleTime" SG_ 391 ESP_VehicleSpeedValid 10;
BA_ "GenSigCycleTime" SG_ 391 ESP_TorqIncwhlFront 10;
BA_ "GenSigCycleTime" SG_ 391 ESP_TCSFailStatus 10;
BA_ "GenSigCycleTime" SG_ 391 ESP_RollingCounter_187 10;
BA_ "GenSigCycleTime" SG_ 391 ESP_GearHoldRequestValid 10;
BA_ "GenSigInvalidValue" SG_ 391 ESP_GearHoldRequest "0";
BA_ "GenSigCycleTime" SG_ 391 ESP_GearHoldRequest 10;
BA_ "GenSigStartValue" SG_ 391 ESP_ESPFunctionStatus 1;
BA_ "GenSigCycleTime" SG_ 391 ESP_ESPFunctionStatus 10;
BA_ "GenSigCycleTime" SG_ 391 ESP_ESPActiveStatus 10;
BA_ "GenSigCycleTime" SG_ 391 ESP_EngTorqIncFrontActive 10;
BA_ "GenSigCycleTime" SG_ 391 ESP_EngTorqDecActive 10;
BA_ "GenSigCycleTime" SG_ 391 ESP_EBDFailStatus 10;
BA_ "GenSigCycleTime" SG_ 391 ESP_CRCCheck_187 10;
BA_ "GenSigCycleTime" SG_ 391 ESP_ADBF_Active 10;
BA_ "GenSigCycleTime" SG_ 391 ESP_ABSFailStatus 10;
BA_ "GenSigCycleTime" SG_ 391 ESP_ABSActiveStatus 10;
BA_ "GenSigCycleTime" SG_ 391 EPBi_MILReq 10;
BA_ "GenSigCycleTime" SG_ 391 EPBi_ClearDiagnosticInfo 10;
BA_ "GenSigCycleTime" SG_ 407 ESP_RollingCounter_197 10;
BA_ "GenSigCycleTime" SG_ 407 ESP_CRCCheck_197 10;
BA_ "GenSigInvalidValue" SG_ 407 EPB_ClutchSensor "127";
BA_ "GenSigCycleTime" SG_ 407 EPB_ClutchSensor 10;
BA_ "GenSigCycleTime" SG_ 404 EMS_RollingCounter_194 10;
BA_ "GenSigCycleTime" SG_ 404 EMS_IGNKL15Posn 10;
BA_ "GenSigCycleTime" SG_ 404 EMS_IdleCtrlSts 10;
BA_ "GenSigCycleTime" SG_ 404 EMS_EngTqFlywhFailr 10;
BA_ "GenSigInvalidValue" SG_ 404 EMS_EngTqFlywh "65535";
BA_ "GenSigStartValue" SG_ 404 EMS_EngTqFlywh 17500;
BA_ "GenSigCycleTime" SG_ 404 EMS_EngTqFlywh 10;
BA_ "GenSigCycleTime" SG_ 404 EMS_EngSts 10;
BA_ "GenSigCycleTime" SG_ 404 EMS_EngStrtSuccess 10;
BA_ "GenSigCycleTime" SG_ 404 EMS_EngStopInhb 10;
BA_ "GenSigCycleTime" SG_ 404 EMS_EngSpdErr 10;
BA_ "GenSigInvalidValue" SG_ 404 EMS_EngSpd "65535";
BA_ "GenSigCycleTime" SG_ 404 EMS_EngSpd 10;
BA_ "GenSigCycleTime" SG_ 404 EMS_EngRunReq 10;
BA_ "GenSigCycleTime" SG_ 404 EMS_EngFuPumpSts 10;
BA_ "GenSigCycleTime" SG_ 404 EMS_EngFuCutOff 10;
BA_ "GenSigCycleTime" SG_ 404 EMS_CRCCheck_194 10;
VAL_ 898 ACC_TarVehLngRange 0 "0~300" 3001 "Reserved" 4095 "Invalid" ;
VAL_ 898 ACC_Target5ZoneID 0 "no zoneid" 1 "zoneid1-11
0xC=hostlane_zone
0xD=leftlane_zone
0xE=rightlane_zone
0xF=LLLane_zone
0x10=RRLane_zone
0x11=Ramp_zone" 18 "others" 19 "reserved" ;
VAL_ 898 ACC_Target5Direction 0 "Forward" 1 "OnComing" 2 "Left" 3 "Right" 4 "unknown" 5 "refer to headingangle" 6 "reserved" ;
VAL_ 898 ACC_Target5LatRange 0 "-50-50m" 1001 "reserved" 1023 "Invalid" ;
VAL_ 898 ACC_Target5LngRange 0 "-100~300" 4001 "reserved" 4095 "Invalid" ;
VAL_ 898 ACC_Target5Type 0 "no display" 1 "sedan" 2 "motorcycle" 3 "pedestrian" 4 "Bicycle" 5 "Bus" 6 "VAN" 7 "truck" 8 "Cone Consideration" 9 "Warning Column" 10 "Water Horse" 11 "Anti-Collision Bucket" 12 "others" 13 "animal" 14 "Non-road vehicle" 15 "CarWarningTriangle" ;
VAL_ 898 ACC_Target5ID 0 "" ;
VAL_ 898 ACC_Target5Detection 0 "not dectected" 1 "IP display" 2 "Front Target" 3 "IACC target" 4 "AEB target" 5 "dangerous target（ELK、UDLC、RCW, etc）" 6 "other target" 7 "reserved" ;
VAL_ 898 ACC_Target4ZoneID 0 "no zoneid" 1 "zoneid1-11
0xC=hostlane_zone
0xD=leftlane_zone
0xE=rightlane_zone
0xF=LLLane_zone
0x10=RRLane_zone
0x11=Ramp_zone" 18 "others" 19 "reserved" ;
VAL_ 898 ACC_Target4Direction 0 "Forward" 1 "OnComing" 2 "Left" 3 "Right" 4 "unknown" 5 "refer to headingangle" 6 "reserved" ;
VAL_ 898 ACC_Target4LatRange 0 "-50-50m" 1001 "reserved" 1023 "Invalid" ;
VAL_ 898 ACC_Target4LngRange 0 "-100~300" 4001 "reserved" 4095 "Invalid" ;
VAL_ 898 ACC_Target4Type 0 "no display" 1 "sedan" 2 "motorcycle" 3 "pedestrian" 4 "Bicycle" 5 "Bus" 6 "VAN" 7 "truck" 8 "Cone Consideration" 9 "Warning Column" 10 "Water Horse" 11 "Anti-Collision Bucket" 12 "others" 13 "animal" 14 "Non-road vehicle" 15 "CarWarningTriangle" ;
VAL_ 898 ACC_Target4ID 0 "" ;
VAL_ 898 ACC_Target4Detection 0 "not dectected" 1 "IP display" 2 "Front Target" 3 "IACC target" 4 "AEB target" 5 "dangerous target（ELK、UDLC、RCW, etc）" 6 "other target" 7 "reserved" ;
VAL_ 898 ACC_Target3ZoneID 0 "no zoneid" 1 "zoneid1-11
0xC=hostlane_zone
0xD=leftlane_zone
0xE=rightlane_zone
0xF=LLLane_zone
0x10=RRLane_zone
0x11=Ramp_zone" 18 "others" 19 "reserved" ;
VAL_ 898 ACC_Target3Direction 0 "Forward" 1 "OnComing" 2 "Left" 3 "Right" 4 "unknown" 5 "refer to headingangle" 6 "reserved" ;
VAL_ 898 ACC_Target3LatRange 0 "-50-50m" 1001 "reserved" 1023 "Invalid" ;
VAL_ 898 ACC_Target3LngRange 0 "-100~300" 4001 "reserved" 4095 "Invalid" ;
VAL_ 898 ACC_Target3Type 0 "no display" 1 "sedan" 2 "motorcycle" 3 "pedestrian" 4 "Bicycle" 5 "Bus" 6 "VAN" 7 "truck" 8 "Cone Consideration" 9 "Warning Column" 10 "Water Horse" 11 "Anti-Collision Bucket" 12 "others" 13 "animal" 14 "Non-road vehicle" 15 "CarWarningTriangle" ;
VAL_ 898 ACC_Target3ID 0 "" ;
VAL_ 898 ACC_Target3Detection 0 "not dectected" 1 "IP display" 2 "Front Target" 3 "IACC target" 4 "AEB target" 5 "dangerous target（ELK、UDLC、RCW, etc）" 6 "other target" 7 "reserved" ;
VAL_ 898 ACC_Target2ZoneID 0 "no zoneid" 1 "zoneid1-11
0xC=hostlane_zone
0xD=leftlane_zone
0xE=rightlane_zone
0xF=LLLane_zone
0x10=RRLane_zone
0x11=Ramp_zone" 18 "others" 19 "reserved" ;
VAL_ 898 ACC_Target2Direction 0 "Forward" 1 "OnComing" 2 "Left" 3 "Right" 4 "unknown" 5 "refer to headingangle" 6 "reserved" ;
VAL_ 898 ACC_Target2LatRange 0 "-50-50m" 1001 "reserved" 1023 "Invalid" ;
VAL_ 898 ACC_Target2LngRange 0 "-100~300" 4001 "reserved" 4095 "Invalid" ;
VAL_ 898 ACC_Target2Type 0 "no display" 1 "sedan" 2 "motorcycle" 3 "pedestrian" 4 "Bicycle" 5 "Bus" 6 "VAN" 7 "truck" 8 "Cone Consideration" 9 "Warning Column" 10 "Water Horse" 11 "Anti-Collision Bucket" 12 "others" 13 "animal" 14 "Non-road vehicle" 15 "CarWarningTriangle" ;
VAL_ 898 ACC_Target2ID 0 "" ;
VAL_ 898 ACC_Target2Detection 0 "not dectected" 1 "IP display" 2 "Front Target" 3 "IACC target" 4 "AEB target" 5 "dangerous target（ELK、UDLC、RCW, etc）" 6 "other target" 7 "reserved" ;
VAL_ 898 ACC_Target1ZoneID 0 "no zoneid" 1 "zoneid1-11
0xC=hostlane_zone
0xD=leftlane_zone
0xE=rightlane_zone
0xF=LLLane_zone
0x10=RRLane_zone
0x11=Ramp_zone" 18 "others" 19 "reserved" ;
VAL_ 898 ACC_Target1Direction 0 "Forward" 1 "OnComing" 2 "Left" 3 "Right" 4 "unknown" 5 "refer to headingangle" 6 "reserved" ;
VAL_ 898 ACC_Target1LatRange 0 "-50-50m" 1001 "reserved" 1023 "Invalid" ;
VAL_ 898 ACC_Target1LngRange 0 "-100~300" 4001 "reserved" 4095 "Invalid" ;
VAL_ 898 ACC_Target1Type 0 "no display" 1 "sedan" 2 "motorcycle" 3 "pedestrian" 4 "Bicycle" 5 "Bus" 6 "VAN" 7 "truck" 8 "Cone Consideration" 9 "Warning Column" 10 "Water Horse" 11 "Anti-Collision Bucket" 12 "others" 13 "animal" 14 "Non-road vehicle" 15 "CarWarningTriangle" ;
VAL_ 898 ACC_Target1ID 0 "" ;
VAL_ 898 ACC_Target1Detection 0 "not dectected" 1 "IP display" 2 "Front Target" 3 "IACC target" 4 "AEB target" 5 "dangerous target（ELK、UDLC、RCW, etc）" 6 "other target" 7 "reserved" ;
VAL_ 898 ACC_LaneEquationStatus 0 "no display" 1 "Left Lane" 2 "Right Lane" 3 "reserved" ;
VAL_ 898 ACC_LaneEquationC3 0 "y=C0+C1*x+(1/2)*C2*x^2+(1/6)*C3*x^3，其中C3为车道线曲率变化率，换算公式为(-2047 + (0x0 ~ 0xFFE))*2^(-21))" ;
VAL_ 898 ACC_LaneEquationC2 0 "y=C0+C1*x+(1/2)*C2*x^2+(1/6)*C3*x^3，其中C2为车道线曲率，换算公式为(-2047 + (0x0 ~ 0xFFE))*2^(-16))" ;
VAL_ 898 ACC_LaneEquationC1 0 "y=C0+C1*x+(1/2)*C2*x^2+(1/6)*C3*x^3，其中C1为车辆相对预期轨迹的角度，换算公式为-1+(0x0 ~ 0xFFE)*2^(-11))" ;
VAL_ 898 ACC_LaneQuality 0 "" ;
VAL_ 676 LCDAR_Left_RCTAAlert 0 "No RCTA warning" 1 "RCTA warning Level1" 2 "RCTA warning Level2" 3 "RCTA warning Level3" ;
VAL_ 676 LCDAR_RCTAAlert 0 "No RCTA warning" 1 "RCTA warning Level1" 2 "RCTA warning Level2" 3 "RCTA warning Level3" ;
VAL_ 676 LCDAR_BSD_LCASoundWar 0 "No Warning" 1 "Warning" ;
VAL_ 676 LCDAR_RCTBStatus 0 "OFF(关闭)" 1 "Inactive(未激活)" 2 "Active" 3 "Failure" ;
VAL_ 676 LCDAR_ELK_oAlert 0 "No warning" 1 "level 1" 2 "level 2" 3 "Reserved" ;
VAL_ 676 LCDAR_ELK_oStatus 0 "OFF(关闭)（预留）" 1 "Inactive(未激活)" 2 "Active" 3 "Failure" ;
VAL_ 676 LCDAR_Left_ELK_oAlert 0 "No warning" 1 "level 1" 2 "level 2" 3 "Reserved" ;
VAL_ 676 LCDAR_RCTBActive 0 " not Active" 1 " Active." ;
VAL_ 676 LCDAR_RCTBEnable 0 "off" 1 "on" ;
VAL_ 676 LCDAR_SystemStatus 0 "Reserved" 1 "StartUp" 2 "Running" 3 "Blocked" 4 "Calibration" 5 "ShutDown" 6 "Hot" 7 "Failure" ;
VAL_ 1426 LAS_NotSleep_BYTE7BIT1 0 "Inactive" 1 " IGN硬线信号为ON档/总线电源挡位信号非OFF" ;
VAL_ 1426 LAS_NotSleep_BYTE7BIT0 0 "Inactive" 1 " CAN网络上其他节点不允许休眠" ;
VAL_ 1426 LAS_WakeUp_BYTE4BIT1 0 "Inactive" 1 " IG唤醒（若不接IG硬线则无此位）" ;
VAL_ 1426 LAS_WakeUp_BYTE4BIT0 0 "Inactive" 1 " CAN网络管理报文唤醒" ;
VAL_ 1428 FR_NotSleep_BYTE7BIT1 0 "Inactive" 1 " IGN硬线信号为ON档/总线电源挡位信号非OFF" ;
VAL_ 1428 FR_NotSleep_BYTE7BIT0 0 "Inactive" 1 " CAN网络上其他节点不允许休眠" ;
VAL_ 1428 FR_WakeUp_BYTE4BIT1 0 "Inactive" 1 " IG唤醒（若不接IG硬线则无此位）" ;
VAL_ 1428 FR_WakeUp_BYTE4BIT0 0 "Inactive" 1 " CAN网络管理报文唤醒" ;
VAL_ 80 SRS_PassengerBuckleSwitchStatus 0 "Buckled" 1 "Unbuckle " 2 "Not Used" 3 "Not Used
Default value= 0x0" ;
VAL_ 80 SRS_RightRearBuckleSwitchSts 0 "Buckled " 1 " Unbuckle " 2 "Not Used" 3 "Not Used  
Default value= 0x0" ;
VAL_ 80 SRS_MiddleRearBuckleSwitchSts 0 "Buckled " 1 " Unbuckle " 2 "Not Used" 3 "Not Used 
Default value= 0x0" ;
VAL_ 80 SRS_LeftRearBuckleSwitchSts 0 "Buckled " 1 " Unbuckle " 2 "Not Used" 3 "Not Used  
Default value= 0x0" ;
VAL_ 80 SRS_FrontPsgOccupancy 0 "not occupied" 1 "occupied
Default value= 0x1" ;
VAL_ 80 SRS_PADIndication 0 "PAB on and Lamp off" 1 "PAB off and Lamp on
Default value= 0x1" ;
VAL_ 80 SRS_WarningLampStatus 0 "Lamp off" 1 "Lamp on" 2 "Lamp Flashing" 3 "Not Used" ;
VAL_ 80 SRS_DriverBuckleSwitchStatus 0 "Buckled" 1 "Unbuckle " 2 "Not Used" 3 "Not Used
Default value= 0x0" ;
VAL_ 80 SRS_CrashOutputStatusCheckSum 0 "(SRS_CrashOutputStatus) XOR 0xF" ;
VAL_ 80 SRS_CrashOutputStatus 0 "No Crash" 1 "crash " 2 "Not Used" ;
VAL_ 80 SRS_CRCCheck_50 0 "0xFF，XOR value=0xFF，input data reflected=No，Result data reflected=No，check=0x48，Magic check=0xC4）" ;
VAL_ 368 EPS_fault_state 0 "No Fault" 1 "Thermal Protection Fault " 2 "Power Limit Fault   " 3 "IMC Result error" 4 "Torque Sensor Fault(recoverable with assist)" 5 "Angle Sensor Fault(recoverable with assist)" 6 "Sensorless Angle Fault(Non recoverable without assist)" 7 "Power Supply Fault(Non recoverable)" 8 "Motor Sensor Fault(Non recoverable)" 9 "Flash/RAM/NVM Fault(Non recoverable)" 10 "Battery Voltage Fault(Recoverable)" 11 "ECU ID Fault(Non recoverable)" 12 "Other Fault(Non recoverable)" ;
VAL_ 368 EPS_ActualMotorTorq 2047 "" ;
VAL_ 368 EPS_ActualTorsionBarTorq 2047 "" ;
VAL_ 368 EPS_MinSafetyTorsionBarTorq 2047 "" ;
VAL_ 368 EPS_MaxSafetyTorsionBarTorq 2047 "" ;
VAL_ 384 SAS_SASFailure 0 "No Failure" 1 "Failure" ;
VAL_ 384 SAS_Calibrated 0 "Calibrated" 1 " Not Calibrated" ;
VAL_ 384 SAS_SteeringAngleValid 0 "Valid" 1 "Invalid" ;
VAL_ 580 ADS_EOMTOReq 0 "无请求" 1 "1级接管请求" 2 "2级接管请求" 3 "3级接管请求" ;
VAL_ 580 ACC_HandsOnReq 0 "no request" 1 "level 1 request" 2 "level 2 request" 3 "level 3 request" 4 "level 4 request" 5 "reserved" ;
VAL_ 580 ACC_LatTakeoverReq 0 "no request" 1 "level 1 request" 2 "level 2 request" 3 "reserved" ;
VAL_ 580 ACC_LngTakeOverReq 0 "no request" 1 "level 1 request" 2 "level 2 request" 3 "reserved" ;
VAL_ 580 ACC_LDWShakeLevStatus 0 "reserved" 1 "low" 2 "normal" 3 "high" ;
VAL_ 580 ACC_TextInfoForDriver 0 "no display" 1 "unable to activate ACC" 2 "ACC active control is cancelled" 3 "ACC error by Front Radar" 4 "ACC temporary unavailable by others" 5 "EPB activate" 6 "No forward gear" 7 "Seatbelt unbuckled" 8 "Engine No Running" 9 "ESP off" 10 "bonnet is Open" 11 "Speed over 150kph" 12 "ACC Error by EMS/VCU/TCU" 14 "ACC Error by EPBI" 15 "ACC unintended exit warning" 16 "door is open" 17 "brake pedal is applied" 18 "speed reduce by ramp" 19 "speed reduce by tunnel" 20 "ACC error by Front Camera" 21 "speed reduce by condition" 22 "speed reduce by SpdLimited" 23 "ACC cannot active by Race mode" 24 "speed reduce by Tollstation" 25 "ACC cannot active by snow mode" 26 "SteeringAngle is over" 27 "emergency brake suddenly" 28 "前雷达不可用，ACC退出" 29 "前摄像头不可用，ACC退出" 30 "Bad weather" 31 "设定车速达到上限" 32 "设定车速达到下限" 33 "设定车速达到限速值" 34 "激活提示
0x23=退出提示-安全带解开
0x24=退出提示-开启车门
0x25=不可激活原因-纵向系统故障
0x26=加速提示-避让并行大车
0x27=减速提示-避让并行大车
0x28=减速提示-避让行人
0x29=减速提示-前方红灯
0x2A=减速提示-减速带
0x2B=不可激活原因-泊车功能激活
0x2C=前方绿灯，�" 46 "减速提示-能见度低
0x2F=不可激活原因-摄像头温度异常
0x30=不可激活原因-拖车功能激活
0x31=不可激活原因-全地形功能激活" ;
VAL_ 580 ACC_AEBCtrlType 0 "no request" 1 "AEB C&U（AEB车辆）" 2 "AEB VRU（AEB行人）" 3 "AEB Cyclist（AEB骑行者）" 4 "EBA（制动辅助）" 5 "FCTB（前向横向AEB）" 6 "RCTB(后向横向AEB)" 7 "Reserved" ;
VAL_ 580 ACC_AccTrqReqActive 0 " not Active" 1 " Active." ;
VAL_ 580 ACC_AEBVehilceHoldReq 0 " No hold" 1 " hold" ;
VAL_ 580 ACC_FCWPreWarning 0 " no warning" 1 " warning" ;
VAL_ 580 ACC_FCWLatentWarning 0 " no warning" 1 " warning" ;
VAL_ 580 ACC_FCWActive 0 " not Active" 1 " Active" ;
VAL_ 580 ACC_PrefillActive 0 " not Active" 1 " Active" ;
VAL_ 580 ACC_AWBActive 0 " not Active" 1 " Active" ;
VAL_ 580 ACC_AWBlevel 0 "  no level" 1 "  level 1" 2 "  level 2" 3 "  level 3" 4 "  level 4" 5 " reserved" ;
VAL_ 580 ACC_ABAActive 0 " not Active" 1 " Active" ;
VAL_ 580 ACC_ABAlevel 0 " level 0" 1 "level 1" 2 " level 2" 3 " level 3" ;
VAL_ 580 ACC_AEBActive 0 " not Active" 1 " Active." ;
VAL_ 580 ACC_EmergencyDataRrdReq 0 "no request" 1 "Event 1 Request" 2 "Event 2 Request" 3 "Image Record" ;
VAL_ 580 ACC_Driveoff_Request 0 " No request" 1 " request" ;
VAL_ 580 ACC_ACCMode 0 "OFF mode" 1 "Passive mode" 2 "StandBy mode" 3 " Active Control mode" 4 " Brake Only mode" 5 " Override" 6 " Stand Wait mode" 7 " Failure mode" ;
VAL_ 580 ACC_CDDActive 0 " not active" 1 " Active" ;
VAL_ 580 ACC_DecToStop 0 "no demand" 1 " demand" ;
VAL_ 580 ACC_LKAStatus 0 "Off" 1 "Standby" 2 "Active" 3 "Failure" ;
VAL_ 580 ACC_LDWVibrationWarningReq 0 " No Warning不报警" 1 " Left Warning左报警" 2 "Right Warning右报警" 3 " reserved" ;
VAL_ 580 ACC_LDWStatus 0 "" ;
VAL_ 632 ESP_YawRateValid 0 "Valid" 1 "Invalid" ;
VAL_ 664 BCM_TrunkUnlockReq 0 "No request" 1 "Trunk unlock" ;
VAL_ 664 BCM_DriverDoorLockStatus 0 "Lock" 1 "Unlock" 2 "Not used" 3 "Error" ;
VAL_ 664 BCM_PassengerDoorLockStatus 0 "Lock" 1 "Unlock" 2 "Not used" 3 "Error" ;
VAL_ 664 BCM_LeftRearDoorStatus 0 "Close" 1 "Open" ;
VAL_ 664 PEPS_SmartWelcomeLightStaus 0 "inactive" 1 "On" 2 "Off" 3 "Reserved" ;
VAL_ 664 PEPS_TrunkKeyStatus 0 "invalid" 1 " pressed" 2 "not pressed " 3 "reserve" ;
VAL_ 664 PEPS_UnLockKeyStatus 0 "invalid" 1 " pressed" 2 "not pressed " 3 "reserve" ;
VAL_ 664 PEPS_LockKeyStatus 0 "invalid" 1 " pressed" 2 "not pressed " 3 "reserve" ;
VAL_ 664 PEPS_SmartTrunkUlockRemind 0 " Inactive" 1 "SlowFlash" 2 "FastFlash" 3 "Reserved" ;
VAL_ 664 PEPS_UnlockSignal 0 " Inactive" 1 " 遥控解锁" 2 " 左前PE解锁" 3 " 右前PE解锁" ;
VAL_ 664 PEPS_LockSignal 0 " Inactive" 1 " 遥控闭锁" 2 " PE闭锁" 3 " 不可用" ;
VAL_ 664 PEPS_KeyNumber 0 "invalid" 1 "Key1-Key6" 7 "Reserved" ;
VAL_ 664 PEPS_KeyAuthenticationStatus 0 "Inactive非认证状态" 1 "start认证中" 2 "Success成功" 3 "failed失败" ;
VAL_ 664 PEPS_Easy_open 0 "no command" 1 "自动感应信号" ;
VAL_ 664 PEPS_Welcomelamp 0 "Inactive" 1 " OFF" 2 "ON" 3 "Reserved" ;
VAL_ 664 PEPS_TrunkRequestSignal 0 "OFF" 1 " 行李箱按钮被按下" ;
VAL_ 664 PEPS_KeyLearningSignal 0 " Inactive非学习状态" 1 " Start学习中" 2 " Success成功" 3 " Failed失败" ;
VAL_ 664 PEPS_EasyOpenOrginalSignal 0 " 脚步传感器未触发" 1 "脚步传感器触发" ;
VAL_ 664 PEPS_RemoteFailedAlarmSignal 0 "Inactive" 1 "钥匙认证失败" ;
VAL_ 664 PEPS_SearchCarSignal 0 "Inactive" 1 "ON" ;
VAL_ 664 PEPS_LuggageUnlockSignal 0 " Inactive" 1 " 遥控行李箱解锁" 2 " PE行李箱解锁" 3 " 不可用" ;
VAL_ 775 ACC_AEBTargetSelected 0 " no object selected" 1 " only longitudinal object selected" 2 " only crossing object selected" 3 " both longitudinal & crossing object selected" 4 " LTA object selected" 5 " CPTA object selected" 6 " both LTA & CPTA object selected" 7 " Reserved" ;
VAL_ 775 ACC_AEBFeatureConfig 0 " AEBM not configured" 1 " AEBVru not configured" 2 " EBA not configured" 3 " AEBP not configured" 4 " Prewarning not configured" 5 " PrewarningVru not configured" 6 " AWB not configured" 7 " LTA not configured" 8 " CPTA not configured" 9 " Prefill not configured" 10 " HBA not configured" 11 " Reserved" ;
VAL_ 775 ACC_ACCTargetLngRange 0 "-70~180" 501 "reserved" 511 "no display" ;
VAL_ 775 ACC_IACCSuspendReason 0 "idle" 1 "无控制信息（线、车、Freespace都不存在）" 2 "手拉方向盘" 3 "加速度过大" 4 "规划异常" 5 "转角或转速过大" 6 "Reserved" 7 "其他原因" ;
VAL_ 775 ACC_RLaneDistanceFus 0 "-5-1" 120 "reserved" ;
VAL_ 775 ACC_LLaneDistanceFus 0 "-1-5" 121 "reserved" ;
VAL_ 775 ACC_RRLaneDis 0 "-12-0" 241 "reserved" ;
VAL_ 775 ACC_LLLaneDis 0 "0-12" 241 "reserved" ;
VAL_ 775 ACC_Target7ZoneID 0 "no zoneid" 1 "zoneid1-11
0xC=hostlane_zone
0xD=leftlane_zone
0xE=rightlane_zone
0xF=LLLane_zone
0x10=RRLane_zone
0x11=Ramp_zone" 18 "others" 19 "reserved" ;
VAL_ 775 ACC_Target7Direction 0 "Forward" 1 "OnComing" 2 "Left" 3 "Right" 4 "unknown" 5 "refer to headingangle" 6 "reserved" ;
VAL_ 775 ACC_Target7LatRange 0 "-50-50m" 1001 "reserved" 1023 "Invalid" ;
VAL_ 775 ACC_Target7LngRange 0 "-100~300" 4001 "reserved" 4095 "Invalid" ;
VAL_ 775 ACC_Target7Type 0 "no display" 1 "sedan" 2 "motorcycle" 3 "pedestrian" 4 "Bicycle" 5 "Bus" 6 "VAN" 7 "truck" 8 "Cone Consideration" 9 "Warning Column" 10 "Water Horse" 11 "Anti-Collision Bucket" 12 "others" 13 "animal" 14 "Non-road vehicle" 15 "CarWarningTriangle" ;
VAL_ 775 ACC_Target7ID 0 "" ;
VAL_ 775 ACC_Target7Detection 0 "not dectected" 1 "IP display" 2 "Front Target" 3 "IACC target" 4 "AEB target" 5 "dangerous target（ELK、UDLC、RCW, etc）" 6 "other target" 7 "reserved" ;
VAL_ 775 ACC_Target6ZoneID 0 "no zoneid" 1 "zoneid1-11
0xC=hostlane_zone
0xD=leftlane_zone
0xE=rightlane_zone
0xF=LLLane_zone
0x10=RRLane_zone
0x11=Ramp_zone" 18 "others" 19 "reserved" ;
VAL_ 775 ACC_Target6Direction 0 "Forward" 1 "OnComing" 2 "Left" 3 "Right" 4 "unknown" 5 "refer to headingangle" 6 "reserved" ;
VAL_ 775 ACC_Target6LatRange 0 "-50-50m" 1001 "reserved" 1023 "Invalid" ;
VAL_ 775 ACC_Target6LngRange 0 "-100~300" 4001 "reserved" 4095 "Invalid" ;
VAL_ 775 ACC_Target6Type 0 "no display" 1 "sedan" 2 "motorcycle" 3 "pedestrian" 4 "Bicycle" 5 "Bus" 6 "VAN" 7 "truck" 8 "Cone Consideration" 9 "Warning Column" 10 "Water Horse" 11 "Anti-Collision Bucket" 12 "others" 13 "animal" 14 "Non-road vehicle" 15 "CarWarningTriangle" ;
VAL_ 775 ACC_Target6ID 0 "" ;
VAL_ 775 ACC_Target6Detection 0 "not dectected" 1 "IP display" 2 "Front Target" 3 "IACC target" 4 "AEB target" 5 "dangerous target（ELK、UDLC、RCW, etc）" 6 "other target" 7 "reserved" ;
VAL_ 775 ACC_AEBEnable 0 "off" 1 "on" ;
VAL_ 775 ACC_VehicleStartRemindSts 0 "off" 1 "passive" 2 "standby" 3 "active" 4 "failure " 5 "reserve" ;
VAL_ 775 ACC_CSLAEnableStatus 0 "OFF" 1 "All Speed-Limit" 2 "Road Camera" 3 "invalid" ;
VAL_ 775 ACC_CSLSetReq 0 "no request" 1 "request" ;
VAL_ 775 ACC_ACCTargetRelSpd 0 "-250-250" 501 "reserved" ;
VAL_ 775 ACC_FRadarCalibrationStatus 0 " Calibration is ok" 1 " Calibration In Process" 2 " Calibration never done" 3 "  Calibration Failed" ;
VAL_ 775 ACC_FCWSettingStatus 0 "early" 1 "normal" 2 "late" 3 "Off" 4 "Reserved" ;
VAL_ 775 ACC_ACCEPBrequest 0 " no request" 1 "  request" ;
VAL_ 775 ACC_ObjValid 0 " no object" 1 " target object detected" ;
VAL_ 775 ACC_TimeGapSet 0 "no display" 1 "1.0S" 2 "1.4S" 3 "1.8S" 4 "2.4S" 5 "reserved" ;
VAL_ 775 ACC_DistanceLevel 0 "no display" 1 " Level 1" 2 "Level 2" 3 " Level 3" 4 "reserved" ;
VAL_ 786 ACC_Selflearning_status 0 "int" 1 "earning" 2 "completed" 3 "rsvrd" ;
VAL_ 786 ADS_NDAAudioWarEnableStatus 0 "OFF" 1 "ON" ;
VAL_ 786 ADS_ADSVoiceRequest 0 "no display" 1 "TakeOver" 2 "saft parking" 3 "deactivate" 4 "handsoff0" 5 "drowsiness" 6 "IACC Cancel" 7 "IACC active" 8 "IACC suspend" 9 "IACCorACC Override" 10 "ACC Cancel" 11 "ACC Active" 12 "TJP active" 13 "SeatPostureRectify" 14 "vehicle distance" 19 "speed out of range" 20 "lanechange to leftpath" 21 " lanechange to rightpath" 22 "lane change return" 23 "lanechange to left side soon" 24 "lanechange to right side soon" 25 "plz lanechange for PathThroughRamp in right side" 26 "plz lanechange for PathThroughRamp in left side" 31 "lanechange condition not support" 32 "waiting lanechange timeout" 33 "Be careful of complex road condition" 34 "Be careful of confluence ahead" 35 "frequent accidents" 36 "Congestion ahead" 37 " plz override for PathThroughRamp" 38 " plz override because of toll station ahead" 39 "recommend TJP" 40 "SpdLimit" 41 "NID cancle" 42 "NID active" 43 "NID out" 44 "Bad weather lead to NID out" 45 "sharp turn lead to NID out" 46 "Toll Station lead to NID out" 47 "accidents lead to NID out" 48 "roadworks lead to NID out" 49 " NID out after 300m" 50 " NID out after 200m" 51 " NID out after 100m" 52 "concetrate
0x35=concetrate to see road" 54 "NID out after 1000m" 55 "sharp turn Plz watch out" 56 "leaving out current road plz watch out" 57 "merge in main road plz watch out" 58 "ramp ahead to turn left" 59 "ramp ahead to turn right" 60 "merge in main road" 61 "turn left right now" 62 "turn right right now" 63 "overtakeing left" 64 "overtaking right" 65 "heavy braking" 66 "over speed" 67 "前方红绿灯，智能限速" 68 "前方人行横道，请注意减速慢行" 69 "前方人行横道，智能限速" 70 "前方收费站，请注意减速慢行" 71 "前方收费站，智能限速" 72 "前方弯道，智能限速" 73 "智能加速避让并行车辆" 74 "智能减速避让并行车辆" 75 "主动加速提醒" 76 "您正处于弯道中，辅助驾驶IACC无法激活" 77 "激活失败，请先减速到120KM/H" 78 "激活失败，请先关闭转向灯
0x4F=请手握方向盘，观察路况
0x50=请打开车灯
0x51=停车完成
0x52=您未进行智能驾驶用户认证，请谨慎操作！
0x53=您已超速接近系统控制极限，IACC即将退出
0x54=车辆临时靠左行驶，避让并行车辆
0x55=车辆临时靠右行驶，避让并行车辆 
0x56=车辆临�" 195 "BAACC不可激活-安全带
0xC4=ACC/IACC不可激活-超速
0xC5=ACC不可激活-发动机
0xC6=ACC不可激活-未开启ESP
0xC7=ACC不可激活-车门未关
0xC8=ACC不可激活-未松开制动踏板
0xC9=ACC/IACC不可激活-系统故障
0xCA=ACC不可激活-仪表故障
0xCB=ACC不可激活-正在APA模式
0xCC=ACC不可�" 275 "DDSAS已激活" 276 "" 277 "" 278 "" 279 "" 280 "" 281 "" 282 "" 283 "" 284 "安全带解开，ACC计时退出" 285 "安全带解开，IACC计时退出" 286 "IACC激活到中断" 287 "车门打开，ACC计时退出" 288 "车门打开，IACC计时退出" 289 "" 290 "reserved" ;
VAL_ 786 ADS_EOMWarnning 0 "no warnning" 1 "L1 warnning" 2 "L2 warnning" 3 "L3 warnning" 4 "Reserved" ;
VAL_ 786 ACC_DriverWindowControl 0 " No Request" 1 " 0%~100% (支持百分比形式)" 102 " Reserved" ;
VAL_ 786 ACC_AEBTargetDirection 0 "Forward" 1 "OnComing" 2 "Left" 3 "Right" 4 "unknown" 5 "no display" 6 "reserved" ;
VAL_ 786 ACC_AEBTargetDetection 0 "no detected" 1 "detected" ;
VAL_ 786 ACC_AEBTargetType 0 "no display" 1 "sedan" 2 "motorcycle" 3 "pedestrian" 4 "Bicycle" 5 "Bus" 6 "van" 7 "truck" 8 "reserved" 15 "other" ;
VAL_ 832 AC_EvaporatorTemp 0 "-40~87℃" 255 "Invalid" ;
VAL_ 832 AC_PrAirMergePortOpeningRatioVD 0 "Valid" 1 "Invalid" ;
VAL_ 832 AC_PrAirMergePortOpeningRatio 0 "0~100" 101 "Reserved" 127 "Invalid" ;
VAL_ 832 AC_DrAirMergePortOpeningRatioVD 0 "Valid" 1 "Invalid" ;
VAL_ 832 AC_DrAirMergePortOpeningRatio 0 "0~100" 101 "Reserved" 127 "Invalid" ;
VAL_ 832 AC_RrAirMergePortOpeningRatioVD 0 "Valid" 1 "Invalid" ;
VAL_ 832 AC_RrAirMergePortOpeningRatio 0 "0~100" 101 "Reserved" 127 "Invalid" ;
VAL_ 832 AC_ACOnOff 0 "OFF" 1 "ON" 2 "not used" 3 "invalid" ;
VAL_ 832 AC_FrBlowType 0 "blow face" 1 "blow face/blow feet" 2 "blow feet" 3 "blow fee/defroster" 4 "defroster" 5 "blowface/defroster" 6 " blowface/blowfeet/defroster" 7 "Invalid" ;
VAL_ 832 AC_RrReqWindLevelVD 0 "Valid" 1 "Invalid" ;
VAL_ 832 AC_RrReqWindLevel 0 "OFF" 1 "Level1" 2 "Level2" 3 "Level3" 4 "Level4" 5 "Level5" 6 "Level6" 7 "Level7" 8 "Level8" 9 "Level0扇叶" 10 "Reserved" 11 "Reserved" 12 "Reserved" 13 "Reserved" 14 "Reserved" 15 "Invaild" ;
VAL_ 839 TPMS_RRPressureWarning 0 "No warning" 1 "High pressure warning" 2 "Low pressure warning" 3 "Quik leakage" 4 "Lost Sensor" 5 "Sensor battery low" 6 "Sensor failure" 7 "Reserved" ;
VAL_ 839 TPMS_LRPressureWarning 0 "No warning" 1 "High pressure warning" 2 "Low pressure warning" 3 "Quik leakage" 4 "Lost Sensor" 5 "Sensor battery low" 6 "Sensor failure" 7 "Reserved" ;
VAL_ 839 TPMS_SystemFailureWarning 0 "No any error" 1 "System error" ;
VAL_ 839 BCM_TirePresureSignalStatus 0 "reliable signal" 1 "unreliable signal" ;
VAL_ 839 TPMS_LFPressureWarning 0 "No warning" 1 "High pressure warning" 2 "Low pressure warning" 3 "Quik leakage" 4 "Lost Sensor" 5 "Sensor battery low" 6 "Sensor failure" 7 "Reserved" ;
VAL_ 839 TPMS_RFPressureWarning 0 "No warning" 1 "High pressure warning" 2 "Low pressure warning" 3 "Quik leakage" 4 "Lost Sensor" 5 "Sensor battery low" 6 "Sensor failure" 7 "Reserved" ;
VAL_ 839 TPMS_SignalStatus 0 "Current Signal" 1 "Last Signal" ;
VAL_ 869 DMS_Zlocation_eye 0 "0x00-0x7FE=-2046~+2046
默认值=0x7FF" ;
VAL_ 869 DMS_Ylocation_eye 0 "0x00-0x7FE=-2046~+2046
默认值=0x7FF" ;
VAL_ 869 DMS_Xlocation_eye 0 "0x00-0x7FE=-2046~+2046
默认值=0x7FF" ;
VAL_ 869 IMS_JawOffsetValue 0 " 0cm" 1 "1cm~15cm" ;
VAL_ 869 IMS_BrowOffsetValue 0 " 0cm" 1 "1cm~15cm" ;
VAL_ 869 IMS_PhoneCallSts 0 " Not In Phone Call" 1 " In Phone Call" ;
VAL_ 869 IMS_DriverEyesFovArea 0 "driver forward" 1 "left outside mirror" 2 "right outside mirror" 3 " inside mirror" 4 " front passenger forward" 5 " HU area " 6 "IP area" 7 " gear area" 8 " below IP" 9 " driver door" 10 " front passenger" 11 " driver door window" 12 "up forward" 13 " front passenger door window" 14 " other" 15 "invalid" ;
VAL_ 869 IMS_DriverEyeClosestatus 0 " both eyes close" 1 "left eye close" 2 " right ?eye close" 3 "both eyes open" 4 " Reserved" 7 " Invalid" ;
VAL_ 869 IMS_DriverEyeConfidence 0 "0~100%" 101 "Reserved" 255 "invalid" ;
VAL_ 869 IMS_DriverEyeDetect 0 "Invalid" 1 "Not detected" 2 "detected" 3 "Reserved" ;
VAL_ 869 IMS_DistractionWarning 0 "Invalid" 1 "开启" 2 "停止" 3 "Reserved" ;
VAL_ 869 IMS_DistractionSetFb 0 "inactive" 1 "On" 2 "Off" 3 "Reserved" ;
VAL_ 869 IMS_DrowsinessSetFb 0 "inactive" 1 "On" 2 "Off" 3 "Reserved" ;
VAL_ 869 IMS_DrowsinessSensFb 0 "Invalid" 1 "低" 2 "中" 3 "高" ;
VAL_ 869 IMS_DrowsinessWarning 0 "Invalid" 1 "一级疲劳报警信号" 2 "二级疲劳报警信号" 3 "微睡眠报警信号" 4 "停止报警信号" 5 "Reserved" ;
VAL_ 869 IMS_IDUpdateRemind 0 "Invalid" 1 "数据库0语音提示" 2 "正视摄像头提示" 3 "更新成功提示" 4 "更新失败提示" 5 "人脸属性删除成功提示" 6 "人脸属性删除失败提示" 7 "Reserved" ;
VAL_ 869 IMS_DriverID 0 "Invalid" 1 "ID Driver 1" 2 "ID Driver 2" 3 "ID Driver 3" 4 "ID Driver 4" 5 "Reserved" 15 "ID Unknow                                 " ;
VAL_ 869 IMS_HeadDetectSts_Yaw 0 "-75~75" 152 "Reserved" 255 "invalid" ;
VAL_ 869 IMS_HeadDetectSts_Roll 0 "-45~45" 92 "Reserved" 255 "invalid" ;
VAL_ 869 IMS_HeadDetectSts_Pitch 0 "-25~45" 72 "Reserved" 255 "invalid" ;
VAL_ 869 IMS_IMSStatus 0 " Off" 1 " Standby" 2 " Active" 3 " Camera Blocked" 4 " Failure" 5 " Reserved" 7 " Invalid" ;
VAL_ 869 IMS_EyeGazeStatus 0 "-75~75" 152 "Reserved" 255 "invalid" ;
VAL_ 869 IMS_EyeDetectSatus 0 "0~100%" 101 "Reserved" 255 "invalid   " ;
VAL_ 869 IMS_DrowsinessStatus 0 " Awake" 1 " Slightly Drowsy" 2 " Drowsy" 3 "Microsleep" 4 " Reserved" 5 " Unavailable" 6 "Unknown" 7 " Invalid" ;
VAL_ 869 IMS_DriverHeadDetect 0 "Invalid" 1 "Not detected" 2 "detected" 3 "Reserved" ;
VAL_ 869 IMS_DistractionStatus 0 " Not Distracted" 1 " Distracted" 2 "Unknown" 3 " Invalid" ;
VAL_ 870 AC_WorkSts 0 "OFF" 1 "Defrost_Defog" 2 "fast Cool" 3 "fast Warm" 4 "Opportunistic Cool" 5 "Opportunistic Warm" 6 "Large Heating" 7 "Reserved" ;
VAL_ 870 AC_PTCStatus 0 "OFF" 1 "1挡" 2 "2挡" 3 "3挡" ;
VAL_ 870 AC_ACPre 0 "0~40.94" 4095 "Invalid" ;
VAL_ 870 AC_AC_ReqValid 0 " Valid" 1 " Invalid" ;
VAL_ 870 AC_FrReqWindLevel 0 "OFF" 1 "Level1" 2 "Level2" 3 "Level3" 4 "Level4" 5 "Level5" 6 "Level6" 7 "Level7" 8 "Level8" 9 "Level0扇叶" 10 "Reserved" 11 "Reserved" 12 "Reserved" 13 "Reserved" 14 "Reserved" 15 "Invaild" ;
VAL_ 870 AC_FrReqWindLevelVD 0 "Valid" 1 "Invalid" ;
VAL_ 870 AC_AC_Req 0 "OFF" 1 "ON" ;
VAL_ 870 AC_EnvironmentalTemp 0 "-40~87℃" 255 "Invalid" ;
VAL_ 870 AC_EnvironmentalTempVD 0 "Valid" 1 "Invalid" ;
VAL_ 903 BCM_WelcomeLightModeFB 0 "inactive" 1 "off" 2 "on mode1" 3 "on mode2 " 4 "on mode3" 5 "Reserved" ;
VAL_ 903 BCM_RainfallLevel 0 "No rain" 1 "Level 1" 2 "Level 2" 3 "Level 3" 4 "Level 4" 5 "Level 5?" 6 "Level 6" 7 "Level 7" 8 "Level 8" 9 "Level 9" 10 "Level 10" 11 "Level 11" 12 "Level 12" 13 "level 13" 14 "init value" 15 "Invalid value" ;
VAL_ 903 BCM_BLEKeyIndicator 0 "inactive" 1 "无蓝牙启动权限" 2 "蓝牙钥匙连接断开" 3 "Reserved" ;
VAL_ 903 BCM_SaveEnergySetStatus 0 "inactive" 1 "10min" 2 "5min" 3 "2min" ;
VAL_ 903 BCM_RearWiperStatus 0 "OFF" 1 "ON" ;
VAL_ 903 BCM_FrontWashStatus 0 "OFF" 1 "ON" 2 "Not used" 3 "Error" ;
VAL_ 903 BCM_FrontWiperStatus 0 "OFF" 1 "Low" 2 "High" 3 "Error" ;
VAL_ 903 BCM_SystemFailureFlag 0 "No Error" 1 "Error" ;
VAL_ 903 BCM_BuzzerWarningMode 0 " OFF" 1 " FollwoMeLight" 2 " LockSpeedSetOFF" 3 " LockSpeedSetON" 4 " KeyLearnSuccess" 5 " DriverDoorUnlockModeSetOFF" 6 " DriverDoorUnlockModeSetON" 7 " AlcoholinterlockLock" 8 " Reserved" 16 " LightON" 17 " RoofWinOpen" 18 " KeyInCarAlarm" 19 " KeyUndetectedAlarm" 20 " ExitActiveArm" 21 " DoorOpenLock" 22 " KeyLowBat" 23 " PassengerSeatBeltWarning" 24 " Reserved" 25 " DriverSeatBeltWarning" 26 " Reserved" 27 " DoorOpen" 28 " PowerManagementNotice" 29 "PowerDownWarning" 30 "TrunkReleaseReqWarning" 31 "Reserved" ;
VAL_ 903 BCM_LightSensor 0 "Day" 1 "Night" ;
VAL_ 903 BCM_Statusrainsensor 0 "NO error" 1 "Error" ;
VAL_ 903 BCM_Statuslowbeam 0 "NO error" 1 "Error" ;
VAL_ 903 BCM_DrivingModeMemoryStatus 0 "Inactive" 1 "yes" 2 "no" 3 "Reserved" ;
VAL_ 903 BCM_DriveModeSet 0 "normal" 1 "eco" 2 "sport" 3 "snow" 4 "Reserved" ;
VAL_ 903 BCM_ThemeChangeSet 0 "Inactive" 1 "press" 2 "Reserved " ;
VAL_ 903 BCM_EPSTorqueModeFeedback 0 "normal" 1 "light" 2 "heavy" 3 " reserved" ;
VAL_ 903 BCM_DriveModeFeedback 0 "normal" 1 "eco" 2 "sport" 3 " Reserved" ;
VAL_ 903 BCM_DriveModeStatus 0 "Normal" 1 "Eco" 2 "Sport  " 3 "Snow" 4 "Sport+(reserved)" 5 "individual" 6 "Reserved" 15 "Invalid" ;
VAL_ 912 BCM_SOH_LifePercent 0 "%0-100%" 101 "Reserved" 255 "invalid" ;
VAL_ 912 BCM_BSNLevel 0 "LEVEL1  蓄电池健康" 1 "LEVEL2 蓄电池老化" 2 "LEVEL3  蓄电池报废" 3 "Reserved" 7 "Invalid" ;
VAL_ 912 BCM_PMSLevel 0 "电量正常" 1 "电量低" 2 "电量消耗过多" 3 "预留Reserved" ;
VAL_ 912 BCM_LowPowerWarning 0 "无动作" 1 "电量低即将关闭电源" 2 "关闭电源" 3 "电量消耗过多即将关闭电源" 4 "预留Reserved" ;
VAL_ 918 BCM_Sunroof_APActive 0 "Inactive" 1 "Active" ;
VAL_ 918 BCM_Sunroof_Intialized 0 "Inactive" 1 "Active" ;
VAL_ 918 BCM_AerationHintReq 0 "Inactive" 1 "On" 2 "Off" 3 "Reserved" ;
VAL_ 918 PEPS_RemoteWindowUpSignal 0 "Inactive" 1 "ON" ;
VAL_ 918 BCM_RemoteWindowUpSetStaus 0 "invalid" 1 "off" 2 "On" 3 "Reserved" ;
VAL_ 918 BCM_RemoteWindowDownSetStaus 0 "inactive" 1 "off" 2 "open" 3 "Reserved" ;
VAL_ 918 PEPS_RemoteWindowDownSignal 0 "Inactive" 1 "ON" ;
VAL_ 918 BCM_RemoteWindowControl 0 "Inactive" 1 "Close" 2 "Open" 3 "Reserved" ;
VAL_ 918 BCM_AutoCloseWindow 0 "inactive" 1 "success " 2 "fail " 3 "reserved" ;
VAL_ 918 BCM_WinOpenWarn 0 "inactive" 1 "warning" ;
VAL_ 918 BCM_WinDownCfgSts 0 "不带遥控功能" 0 "遥控长按下降模式" 2 "遥控一键下降模式" 3 "无效值" ;
VAL_ 918 BCM_WinUpCfgSts 0 "不带遥控功能" 1 "遥控长按上升模式" 2 "遥控一键上升模式" 3 "无效值" ;
VAL_ 918 BCM_LockAutoClsWinSetStatus 0 "inactive" 1 "on" 2 "off " 3 "reserved" ;
VAL_ 918 BCM_SunroofMotor 0 " OFF" 1 "Running" 2 " Not used" 3 " Error(Reserved)" ;
VAL_ 918 BCM_SunroofRainSetStatus 0 "inactive" 1 "off" 2 "on" 3 "Reserved" ;
VAL_ 918 BCM_Sunshade_Movement 0 " stopped" 1 " opening slide" 2 " closing slide " 3 " reversing (AP/Stall)" 4 " moving uninitialized" 5 " reserved" ;
VAL_ 918 BCM_Sunroof_POS_Direction 0 "horizontal" 1 "vertical" ;
VAL_ 918 BCM_Sunroof_Movement 0 "stopped" 1 " opening tilt" 2 " closing tilt" 3 " opening slide" 4 " closing slide " 5 " reversing (AP/Stall)" 6 " moving uninitialized" 7 " reserved" ;
VAL_ 918 BCM_SunroofStatus 0 "Close" 1 "Open" ;
VAL_ 1287 HU_NDANavEnable 0 "Inactive" 1 "Off" 2 "On" 3 " Reserved" ;
VAL_ 1287 HU_NDAEnable 0 "Inactive" 1 "Off" 2 "On" 3 " Reserved" ;
VAL_ 1287 HU_Tutorialmodel 0 "Invalid" 1 "OK" 2 "Cancel" 3 "Test" ;
VAL_ 1287 HU_APAActive3 0 "Invalid" 1 "Activate" ;
VAL_ 1287 HU_LaneChangeStyle 0 "Inactive" 1 "Soft" 2 "Comfortable" 3 "Radical" 4 "reserve" ;
VAL_ 1287 HU_DoorOpenWarningSelect 0 "Not Active" 1 "Open" 2 "Close" 3 "Invalid" ;
VAL_ 1287 HU_FullSpeedPanoramicSelect 0 "Not Active" 1 "Open" 2 "Close" 3 "Invalid" ;
VAL_ 1287 HU_ParkVoiceIntSetStatus 0 "inactive" 1 " On" 2 " Off" 3 "Reserved" ;
VAL_ 1287 HU_TJPEnable 0 "Inactive" 1 "Off" 2 "On" 3 " Reserved" ;
VAL_ 1287 HU_FCTAEnable 0 "Inactive" 1 "Off" 2 "On" 3 " Reserved" ;
VAL_ 1287 HU_FCTBEnable 0 "Inactive" 1 "Off" 2 "On" 3 " Reserved" ;
VAL_ 1287 HU_RCTBEnable 0 "Inactive" 1 "Off" 2 "On" 3 " Reserved" ;
VAL_ 1287 HU_SlotVoiceSelect 0 "Inactive" 1 "No.1" 2 "No.2" 3 "No.3" 4 "No.4" 5 "No.5" 6 "No.6" 7 "No.7" 8 "No.8" 9 "No.9" 10 "No.10" 11 "Reserved" ;
VAL_ 1287 HU_ParkingModeSelect 0 "Inactive" 1 "InteriorParking" 2 "RemoteParking" 3 "ParkingResume" ;
VAL_ 1287 HU_TopLookDownSwitch 0 "Inactive" 1 "Off" 2 "On" 3 "Reserved" ;
VAL_ 1287 HU_TransparentCarSwitch 0 "Inactive" 1 "Off" 2 "On" 3 "Reserved" ;
VAL_ 1287 HU_DVREmergencyRecord 0 "Inactive" 1 "Record" 2 "Reserved" 3 "Invalid" ;
VAL_ 1287 HU_MODEnable 0 "Inactive" 1 "Off" 2 "On" 3 "Reserved" ;
VAL_ 1287 HU_AVMCalibrationSwitch 0 "Inactive" 1 "Calibrate" 2 "Edit Calibrate" 3 "Reset" ;
VAL_ 1287 HU_DVRDistortCorrectSwitch 0 "Inactive" 1 "Off" 2 "On" 3 "Reserved" ;
VAL_ 1287 HU_DVRTapeSet 0 "Inactive" 1 "Off" 2 "On" 3 "Reserved" ;
VAL_ 1287 HU_ResolutionSet 0 "Inactive" 1 "1080P" 2 "720P" 3 "Reserved" ;
VAL_ 1287 HU_DVREnableSet 0 "Inactive" 1 "Off" 2 "On" 3 "Reserved" ;
VAL_ 1287 HU_DVRReplaySpeed 0 "No Request" 1 "Forward Play" 2 "Rewind Play" 3 "Reserved" ;
VAL_ 1287 HU_DVRReplayMode 0 "No Request" 1 "Enter Cycle Mode Browse" 2 "Enter Emergency Mode Browse" 3 "Enter Photo Mode Browse" ;
VAL_ 1287 HU_ShootControl 0 "Inactive" 1 "ShootReq" 2 "Reserved" 3 "Reserved" ;
VAL_ 1287 HU_RecordingcycleSetting 0 "inactive" 1 "1min" 2 "3min" 3 "5min" ;
VAL_ 1287 HU_LanguageSet 0 "Inactive" 1 "Chinese" 2 "English" 3 "Reserved" ;
VAL_ 1287 HU_DVRVedioSeek 0 "No Request" 1 "Prev" 2 "Next" 3 "Exit" ;
VAL_ 1287 HU_DVRFormatReq 0 "inactive" 1 " Format cancel" 2 "Format" 3 "Reserved" ;
VAL_ 1287 HU_DVRReplayCommand 0 "No Request" 1 "Play" 2 "Pause" 3 "Reserved" ;
VAL_ 1287 HU_DVRVideoPlayUserTime 0 "0~510" 511 "Inactive" ;
VAL_ 1287 HU_TurnLightAVMSwitch 0 "Inactive" 1 "Off" 2 "On" 3 "Reserved" ;
VAL_ 1287 HU_RadarAVMSwitch 0 "Inactive" 1 "Off" 2 "On" 4 "Reserved" ;
VAL_ 1287 HU_VC_CruiseSetSpeed 0 "No Request" 1 "1-250" 251 "Reserved" 255 "Invalid" ;
VAL_ 1287 HU_VC_CruiseSetDistance 0 "No Request" 1 "Level 1" 2 "Level 2" 3 "Level 3" 4 "Level 4" 5 "Level 5" 6 "reserved" 7 "Invalid" ;
VAL_ 1287 HU_VC_CruiseControl 0 "No Request" 1 "ACC Activate" 2 "ACC Resume" 3 "IACC Activate" 4 "IACC Resume" 5 "Cancel" 6 "Reserved" 7 "Invalid" ;
VAL_ 1287 HU_BSDLCASetting 0 "early" 1 "normal" 2 "late" 3 "Off" 4 "reserved" 7 "Invalid" ;
VAL_ 1287 HU_FCWSetting 0 "Early" 1 "Normal" 2 "Late" 3 "Off" 4 "Reserved" 7 "Invalid" ;
VAL_ 1287 HU_FrontRadarActive 0 "Invalid" 1 "Activate" 2 "Deactivate" 3 "Reserved" ;
VAL_ 1287 HU_APAActive2 0 "Invalid" 1 "Activate" 2 "Deactivate" 3 "Reserved" ;
VAL_ 1287 HU_ACCObjEnable 0 "no voice" 1 " Reserved" 3 " both voice" ;
VAL_ 1287 HU_CruiseControlSet 0 "Inactive" 1 "ACC" 2 "CC" 3 "IACC（预留）" 4 "HWA（预留）" 5 "reserved" ;
VAL_ 1287 HU_AutoBrakeEnable 0 "off" 1 "on" 2 "reserved" 3 "Invalid" ;
VAL_ 1287 HU_DVRPrintScreen 0 "Inactive" 1 "Print Screen" 2 "Reserved" 3 "Reserved" ;
VAL_ 1287 HU_AVMCalibrationConfirm 0 "Inactive" 1 "Yes" 2 "No" 3 "Reserved" ;
VAL_ 1287 HU_IACCEnable 0 "Inactive" 1 "Off" 2 "On" 3 "Reserved" ;
VAL_ 1287 HU_LockCtrlEnable 0 "Inactive" 1 "Off" 2 "On" 3 " Reserved" ;
VAL_ 1287 HU_AudioWarningEnable 0 "inactive" 1 "Off" 2 "On" 3 " Reserved" ;
VAL_ 1287 HU_LDWShakeLev 0 "inactive" 1 "low" 2 "normal" 3 "high" ;
VAL_ 1287 HU_SEAEnable 0 "inactive" 1 "Off" 2 "On" 3 " Reserved" ;
VAL_ 1287 HU_RCTAEnable 0 "inactive" 1 "Off" 2 "On" 3 " Reserved" ;
VAL_ 1287 HU_RCWEnable 0 "Inactive" 1 "Off" 2 "On" 3 " Reserved" ;
VAL_ 1287 HU_HMAEnable 0 "off" 1 "on" 2 "reserved" 3 "Invalid" ;
VAL_ 1287 HU_TSRSwitch 0 "off" 1 "on" ;
VAL_ 1287 HU_LASWarningModeSelection 0 "inactive" 1 "visual" 2 "sound" 3 "vibration" 4 "sound and vibration" 5 "Reserved" ;
VAL_ 1287 HU_LASModeSelection 0 "Inactive" 1 "LDW" 2 "LKA" 3 "LCS" 4 "Reserved" 7 "OFF" ;
VAL_ 1287 HU_ObstacleSafeDistanceSet 0 "Inactive" 1 "30" 2 "40" 3 "50" 4 "60" 5 "70" 6 "80" 7 "Reserved" ;
VAL_ 1287 HU_ParkingConfirm 0 "No Request" 1 "Request" ;
VAL_ 1287 HU_RemoteDistanceSet 0 "Inactive" 1 "1~15" ;
VAL_ 1287 HU_ParkingResume 0 "No Request" 1 "Request" ;
VAL_ 1287 HU_Uls_FKP_Activation 0 "inactive" 1 "On" 2 "Off" 3 "Reserved" ;
VAL_ 1287 HU_Uls_BSD_Activation 0 "inactive" 1 "On" 2 "Off" 3 "Reserved" ;
VAL_ 1287 HU_OverspeedWarningOffset 0 "-10~20km/h" 31 "Reserved" 47 "Invalid." ;
VAL_ 1287 HU_OverspeedWarningEnable 0 "Inactive" 1 "OFF" 2 "ON" 3 "Reserved" ;
VAL_ 1287 HU_OverspeedSoundWarEnable 0 "Inactive" 1 "Off" 2 "On" 3 " Reserved" ;
VAL_ 1287 HU_FatigueDectionEnable 0 "Invalid" 1 "OFF" 2 "ON" 3 "Reserved" ;
VAL_ 1287 HU_DVRBrowseCommand 0 "No Req" 1 "Up" 2 "Down" 3 "Left" 4 "Right" 5 "Delete Files" 6 "NormalToEmergency" 7 "Edit Enter" 8 "Edit Cancel" 9 "Reserved" ;
VAL_ 1287 HU_NDAAudioWarEnable 0 "Inactive" 1 "Off" 2 "On" 3 " Reserved" ;
VAL_ 1287 HU_RampAVMSwitch 0 "Inactive" 1 "Off" 2 "On" 3 "Reserved" ;
VAL_ 1287 HU_NDASetSpdMode 0 "Inactive" 1 "Manual/Normal" 2 "Auto/Sport" 3 "Auto/Eco" ;
VAL_ 1287 HU_HZPOnOff 0 "off" 1 "on" ;
VAL_ 1287 HU_HZPRecomendRes 0 "default" 1 "accepted" ;
VAL_ 1302 HU_AirHumidityValid 0 "Valid" 1 "Invalid" ;
VAL_ 1302 HU_AirHumidity 0 "0~100" 101 "reserved" 127 "Invalid" ;
VAL_ 1302 HU_LeaveMaintainMileage 0 "0~100000" 100001 "Reserved" 1048575 "Invalid" ;
VAL_ 1302 HU_LeaveMaintainDay 0 "0~3100天" 3101 "Reserved" 4095 "Invalid" ;
VAL_ 1302 HU_MaintainRemindReq 0 "无请求" 1 "保养预警请求" 2 "保养到期提示请求" 3 "Invalid" ;
VAL_ 1302 HU_LocalTimeSystem 0 "24h" 1 "12h" 2 "Reserved" 3 "Invalid" ;
VAL_ 1302 HU_LocalTimeValid 0 "Valid" 1 "Not Valid" ;
VAL_ 1302 HU_CurrentLocationLatitude 134217727 "" ;
VAL_ 1302 HU_CurrentLocationLongitude 268435455 "" ;
VAL_ 1302 HU_CurrentLocationValid 0 "Valid" 1 "Not Valid" ;
VAL_ 1302 HU_CurrentLocationstd 0 "0-100m" 10001 "Reserved" ;
VAL_ 1328 IP_FuelLevel 0 " FUEIL≤E" 1 " E < FUEIL ≤1/8" 2 " 1/8< FUEIL ≤1/4" 3 " 1/4< FUEIL ≤3/8" 4 "3/8< FUEIL ≤1/2" 5 "  1/2< FUEIL ≤5/8" 6 " 5/8< FUEIL ≤3/4" 7 " 3/4< FUEIL ≤7/8" 8 " 7/8< FUEIL ≤F" ;
VAL_ 1328 IP_EngineOffTime 0 "0-65533s" 65534 "65534 or >65534" 65535 "invalid" ;
VAL_ 391 IBCU_BrakeFluid_Warning 0 "Normal" 1 "low" 2 "empty/Reserved" 3 "Invalid" ;
VAL_ 391 ESP_VehicleSpeed 0 "0~360km/h" 6401 "Reserved" 8191 "Invalid
APA2.0接收" ;
VAL_ 391 ESP_VehicleSpeedValid 0 "Valid" 1 "NotValid" ;
VAL_ 391 ESP_TCSFailStatus 0 "Noerror" 1 "Error" ;
VAL_ 391 ESP_GearHoldRequestValid 0 "Valid" 1 "NotValid" ;
VAL_ 391 ESP_GearHoldRequest 0 "NotRequest" 1 "Request" ;
VAL_ 391 ESP_ESPFunctionStatus 0 "OFF" 1 "ON" ;
VAL_ 391 ESP_ESPActiveStatus 0 "NotActive" 1 "Active" ;
VAL_ 391 ESP_EngTorqIncFrontActive 0 "NotActive" 1 "Active" ;
VAL_ 391 ESP_EngTorqDecActive 0 "NotActive" 1 "Active" ;
VAL_ 391 ESP_EBDFailStatus 0 "Noerror" 1 "Error" ;
VAL_ 391 ESP_ADBF_Active 0 "NotActive" 1 "Active" ;
VAL_ 391 ESP_ABSFailStatus 0 "Noerror" 1 "Error" ;
VAL_ 391 ESP_ABSActiveStatus 0 "NotActive" 1 "Active" ;
VAL_ 391 EPBi_MILReq 0 "Not Request" 1 "Request" ;
VAL_ 391 EPBi_ClearDiagnosticInfo 0 "Normal" 1 "Not used" 2 "EPBi request EMS to clear DiagnosticInfo" 3 "EPBi has cleared Diag info per EMS request" ;
VAL_ 404 EMS_IGNKL15Posn 1 "Yes" 0 "No" ;
VAL_ 404 EMS_IdleCtrlSts 1 "True" 0 "False" ;
VAL_ 404 EMS_EngTqFlywhFailr 0 "No error" 1 "Error" ;
VAL_ 404 EMS_EngSts 3 "Reserved" 2 "Running" 1 "Crank" 0 "Stop" ;
VAL_ 404 EMS_EngStrtSuccess 1 "Success" 0 "Not success" ;
VAL_ 404 EMS_EngStopInhb 3 "3rd priority" 2 "2nd priority" 1 "1st priority" 0 "no inhibit" ;
VAL_ 404 EMS_EngSpdErr 0 "No error" 1 "Error" ;
VAL_ 404 EMS_EngRunReq 3 "3rd priority" 2 "2nd priority" 1 "1st priority" 0 "no request" ;
VAL_ 404 EMS_EngFuPumpSts 3 "not used" 2 "Error" 1 "Work" 0 "Not work" ;
VAL_ 404 EMS_EngFuCutOff 1 "True" 0 "False" ;
